VERSION ""

NS_ :

BS_:

BU_: Engine2 Aftertreatment_1_GasOutlet BrakesSystemController Transmission1 Engine1

BO_ 2364473170 AC_At1Out: 8 Aftertreatment_1_GasOutlet
 SG_ ArbitraryAddressCapable : 63|1@1+ (1,0) [0|1] "" Vector__XXX
 SG_ IndustryGroup M : 60|3@1+ (1,0) [0|7] "" Vector__XXX
 SG_ VehicleSystemInstance : 56|4@1+ (1,0) [0|15] "" Vector__XXX
 SG_ Function : 40|8@1+ (1,0) [0|255] "" Vector__XXX
 SG_ FunctionInstance : 35|5@1+ (1,0) [0|31] "" Vector__XXX
 SG_ ECUInstance : 32|3@1+ (1,0) [0|7] "" Vector__XXX
 SG_ ManufacturerCode : 21|11@1+ (1,0) [0|2047] "" Vector__XXX
 SG_ IdentityNumber : 0|21@1+ (1,0) [0|2097152] "" Vector__XXX
 SG_ VehicleSystem m0 : 49|7@1+ (1,0) [0|127] "" Vector__XXX
 SG_ VehicleSystem5 m5 : 49|7@1+ (1,0) [0|127] "" Vector__XXX
 SG_ VehicleSystem4 m4 : 49|7@1+ (1,0) [0|127] "" Vector__XXX
 SG_ VehicleSystem3 m3 : 49|7@1+ (1,0) [0|127] "" Vector__XXX
 SG_ VehicleSystem2 m2 : 49|7@1+ (1,0) [0|127] "" Vector__XXX
 SG_ VehicleSystem1 m1 : 49|7@1+ (1,0) [0|127] "" Vector__XXX

BO_ 2364473169 AC_At1In: 8 Vector__XXX
 SG_ ArbitraryAddressCapable : 63|1@1+ (1,0) [0|1] "" Vector__XXX
 SG_ IndustryGroup M : 60|3@1+ (1,0) [0|7] "" Vector__XXX
 SG_ VehicleSystemInstance : 56|4@1+ (1,0) [0|15] "" Vector__XXX
 SG_ Function : 40|8@1+ (1,0) [0|255] "" Vector__XXX
 SG_ FunctionInstance : 35|5@1+ (1,0) [0|31] "" Vector__XXX
 SG_ ECUInstance : 32|3@1+ (1,0) [0|7] "" Vector__XXX
 SG_ ManufacturerCode : 21|11@1+ (1,0) [0|2047] "" Vector__XXX
 SG_ IdentityNumber : 0|21@1+ (1,0) [0|2097152] "" Vector__XXX
 SG_ VehicleSystem m0 : 49|7@1+ (1,0) [0|127] "" Vector__XXX
 SG_ VehicleSystem5 m5 : 49|7@1+ (1,0) [0|127] "" Vector__XXX
 SG_ VehicleSystem4 m4 : 49|7@1+ (1,0) [0|127] "" Vector__XXX
 SG_ VehicleSystem3 m3 : 49|7@1+ (1,0) [0|127] "" Vector__XXX
 SG_ VehicleSystem2 m2 : 49|7@1+ (1,0) [0|127] "" Vector__XXX
 SG_ VehicleSystem1 m1 : 49|7@1+ (1,0) [0|127] "" Vector__XXX

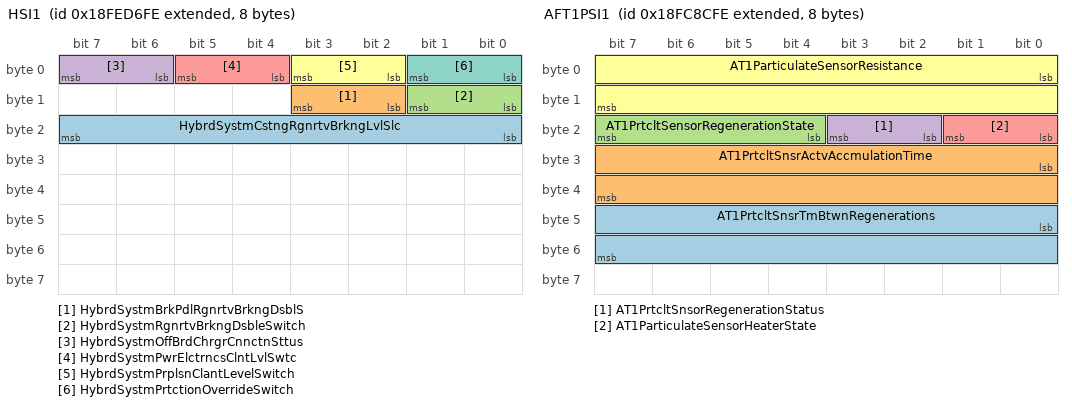
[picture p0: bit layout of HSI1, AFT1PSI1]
BO_ 2566838014 HSI1: 8 Vector__XXX
 SG_ HybrdSystmCstngRgnrtvBrkngLvlSlc : 16|8@1+ (0.4,0) [0|100] "%" Vector__XXX
 SG_ HybrdSystmBrkPdlRgnrtvBrkngDsblS : 10|2@1+ (1,0) [0|3] "" Vector__XXX
 SG_ HybrdSystmRgnrtvBrkngDsbleSwitch : 8|2@1+ (1,0) [0|3] "" Vector__XXX
 SG_ HybrdSystmOffBrdChrgrCnnctnSttus : 6|2@1+ (1,0) [0|3] "" Vector__XXX
 SG_ HybrdSystmPwrElctrncsClntLvlSwtc : 4|2@1+ (1,0) [0|3] "" Vector__XXX
 SG_ HybrdSystmPrplsnClantLevelSwitch : 2|2@1+ (1,0) [0|3] "" Vector__XXX
 SG_ HybrdSystmPrtctionOverrideSwitch : 0|2@1+ (1,0) [0|3] "" Vector__XXX

BO_ 2566761726 EFI: 8 Vector__XXX
 SG_ EngIdleFuelFlowRateThreshold : 8|32@1+ (0.001,0) [0|4211081.215] "L/h" Vector__XXX
 SG_ NmbrOfFlCnsmptnMntrngTransducers : 0|8@1+ (1,0) [0|250] "" Vector__XXX

BO_ 2566756350 LFI3: 8 Vector__XXX
 SG_ EngFuelReturnTemp : 8|8@1+ (1,-40) [-40|210] "°C" Vector__XXX
 SG_ EngFuelSupplyTemp : 0|8@1+ (1,-40) [-40|210] "°C" Vector__XXX

BO_ 2566756094 LFI2: 8 Vector__XXX
 SG_ EngFuelReturnFlowRate : 32|32@1+ (0.001,0) [0|4211081.215] "L/h" Vector__XXX
 SG_ EngFuelSupplyFlowRate : 0|32@1+ (0.001,0) [0|4211081.215] "L/h" Vector__XXX

BO_ 2566687998 AFT1PSI1: 8 Vector__XXX
 SG_ AT1PrtcltSnsrTmBtwnRegenerations : 40|16@1+ (6,0) [0|385530] "s" Vector__XXX
 SG_ AT1PrtcltSnsrActvAccmulationTime : 24|16@1+ (6,0) [0|385530] "s" Vector__XXX
 SG_ AT1PrtcltSensorRegenerationState : 20|4@1+ (1,0) [0|15] "" Vector__XXX
 SG_ AT1PrtcltSnsorRegenerationStatus : 18|2@1+ (1,0) [0|3] "" Vector__XXX
 SG_ AT1ParticulateSensorHeaterState : 16|2@1+ (1,0) [0|3] "" Vector__XXX
 SG_ AT1ParticulateSensorResistance : 0|16@1+ (1,0) [0|62500] "kohm" Vector__XXX

BO_ 2566687742 AFT1PSI2: 8 Vector__XXX
 SG_ AT1PrtclteSensorHeaterResistance : 40|16@1+ (0.1,0) [0|6425.5] "ohm" Vector__XXX
 SG_ AT1PrticulateSensorMaxResistance : 32|16@1+ (250,0) [0|62500] "kohm" Vector__XXX
 SG_ AT1ParticulateSensorTemp : 16|16@1+ (0.03125,-273) [-273|1734.96875] "°C" Vector__XXX
 SG_ AT1PrtcltSnsrRgnrtionFailedCount : 8|8@1+ (1,0) [0|250] "" Vector__XXX
 SG_ AT1ParticulateSensorPowerSupply : 4|2@1+ (1,0) [0|3] "" Vector__XXX
 SG_ AT1PrtclateSensorDetectionStatus : 0|4@1+ (1,0) [0|15] "" Vector__XXX

BO_ 2365348350 ELS: 8 Vector__XXX
 SG_ EngLoadShareStatus : 2|4@1+ (1,0) [0|15] "" Vector__XXX
 SG_ EngUnloadStatus : 0|2@1+ (1,0) [0|3] "" Vector__XXX

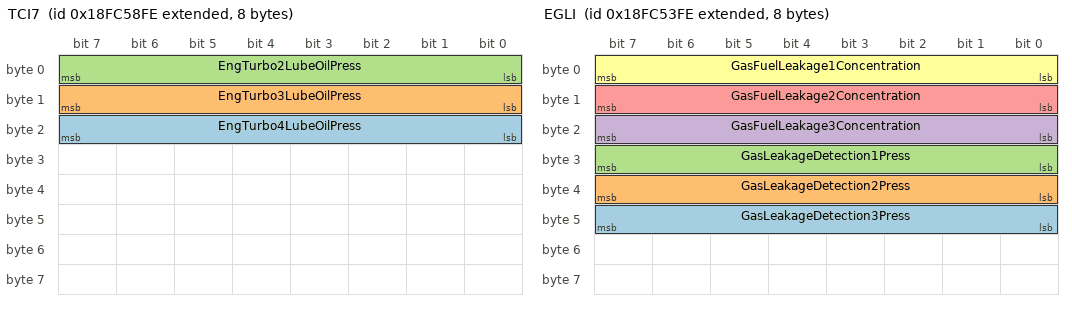
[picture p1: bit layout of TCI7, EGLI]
BO_ 2566674686 TCI7: 8 Vector__XXX
 SG_ EngTurbo4LubeOilPress : 16|8@1+ (4,0) [0|1000] "kPa" Vector__XXX
 SG_ EngTurbo3LubeOilPress : 8|8@1+ (4,0) [0|1000] "kPa" Vector__XXX
 SG_ EngTurbo2LubeOilPress : 0|8@1+ (4,0) [0|1000] "kPa" Vector__XXX

BO_ 2566674430 SCROII1: 8 Vector__XXX
 SG_ DslExhstFldQalityMalfunctionTime : 32|32@1+ (1,0) [0|4211081215] "s" Vector__XXX
 SG_ DieselExhaustFluidTank1EmptyTime : 0|32@1+ (1,0) [0|4211081215] "s" Vector__XXX

BO_ 2566674174 SCROII2: 8 Vector__XXX
 SG_ SCROperatorInducementTotalTime : 32|32@1+ (1,0) [0|4211081215] "s" Vector__XXX
 SG_ ATSCRMalfunctionTime : 0|32@1+ (1,0) [0|4211081215] "s" Vector__XXX

BO_ 2566673406 EGLI: 8 Vector__XXX
 SG_ GasLeakageDetection3Press : 40|8@1+ (4,0) [0|100] "kPa" Vector__XXX
 SG_ GasLeakageDetection2Press : 32|8@1+ (4,0) [0|100] "kPa" Vector__XXX
 SG_ GasLeakageDetection1Press : 24|8@1+ (4,0) [0|100] "kPa" Vector__XXX
 SG_ GasFuelLeakage3Concentration : 16|8@1+ (0.5,0) [0|100] "%" Vector__XXX
 SG_ GasFuelLeakage2Concentration : 8|8@1+ (0.5,0) [0|100] "%" Vector__XXX
 SG_ GasFuelLeakage1Concentration : 0|8@1+ (0.5,0) [0|100] "%" Vector__XXX

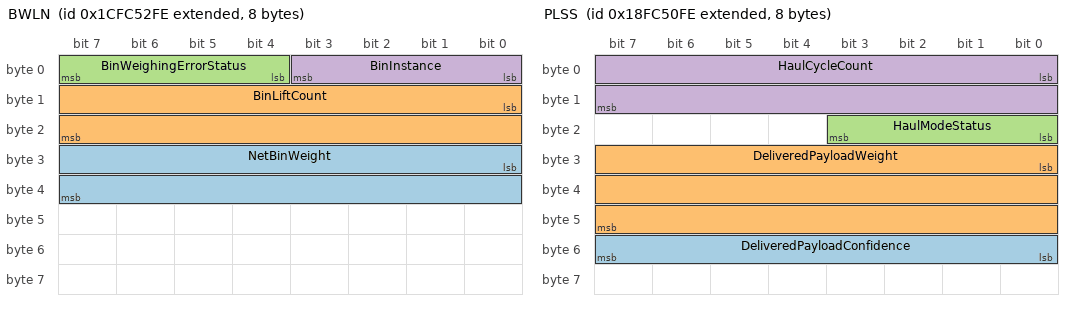
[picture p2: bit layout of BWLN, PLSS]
BO_ 2633782014 BWLN: 8 Vector__XXX
 SG_ NetBinWeight : 24|16@1+ (2,0) [0|128510] "kg" Vector__XXX
 SG_ BinLiftCount : 8|16@1+ (1,0) [0|64255] "" Vector__XXX
 SG_ BinWeighingErrorStatus : 4|4@1+ (1,0) [0|15] "" Vector__XXX
 SG_ BinInstance : 0|4@1+ (1,0) [0|15] "" Vector__XXX

BO_ 2365346302 ASC7: 8 Vector__XXX
 SG_ LiftAxle2Status : 3|3@1+ (1,0) [0|7] "" Vector__XXX
 SG_ LiftAxle1Status : 0|3@1+ (1,0) [0|7] "" Vector__XXX

BO_ 2566672638 PLSS: 8 Vector__XXX
 SG_ DeliveredPayloadConfidence : 48|8@1+ (0.5,0) [0|100] "%" Vector__XXX
 SG_ DeliveredPayloadWeight : 24|24@1+ (2,0) [0|32899070] "kg" Vector__XXX
 SG_ HaulModeStatus : 16|4@1+ (1,0) [0|15] "" Vector__XXX
 SG_ HaulCycleCount : 0|16@1+ (1,0) [0|64255] "" Vector__XXX

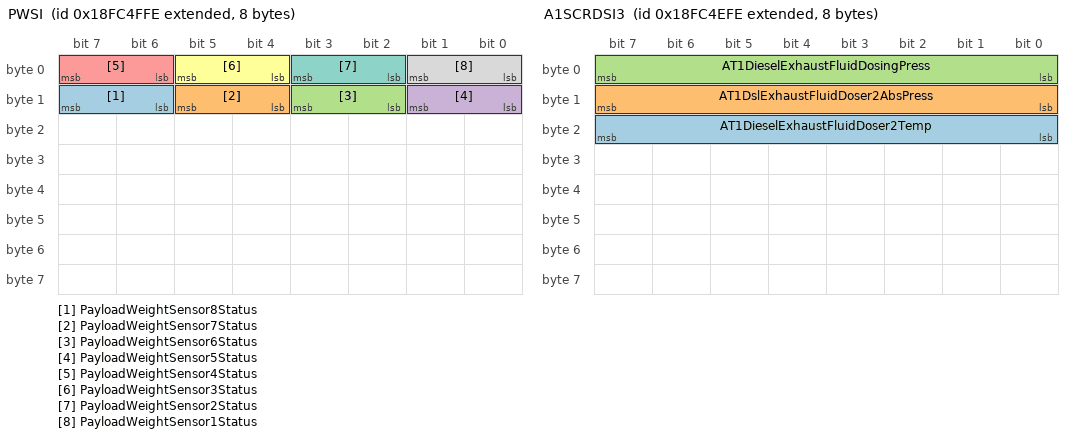
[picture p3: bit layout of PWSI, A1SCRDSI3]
BO_ 2566672382 PWSI: 8 Vector__XXX
 SG_ PayloadWeightSensor8Status : 14|2@1+ (1,0) [0|3] "" Vector__XXX
 SG_ PayloadWeightSensor7Status : 12|2@1+ (1,0) [0|3] "" Vector__XXX
 SG_ PayloadWeightSensor6Status : 10|2@1+ (1,0) [0|3] "" Vector__XXX
 SG_ PayloadWeightSensor5Status : 8|2@1+ (1,0) [0|3] "" Vector__XXX
 SG_ PayloadWeightSensor4Status : 6|2@1+ (1,0) [0|3] "" Vector__XXX
 SG_ PayloadWeightSensor3Status : 4|2@1+ (1,0) [0|3] "" Vector__XXX
 SG_ PayloadWeightSensor2Status : 2|2@1+ (1,0) [0|3] "" Vector__XXX
 SG_ PayloadWeightSensor1Status : 0|2@1+ (1,0) [0|3] "" Vector__XXX

BO_ 2566672126 A1SCRDSI3: 8 Vector__XXX
 SG_ AT1DieselExhaustFluidDoser2Temp : 16|8@1+ (1,-40) [-40|210] "°C" Vector__XXX
 SG_ AT1DslExhaustFluidDoser2AbsPress : 8|8@1+ (8,0) [0|2000] "kPa" Vector__XXX
 SG_ AT1DieselExhaustFluidDosingPress : 0|8@1+ (4,0) [0|1000] "kPa" Vector__XXX

BO_ 2566671870 A2SCRDSI3: 8 Vector__XXX
 SG_ AT2DieselExhaustFluidDosingPress : 0|8@1+ (4,0) [0|1000] "kPa" Vector__XXX

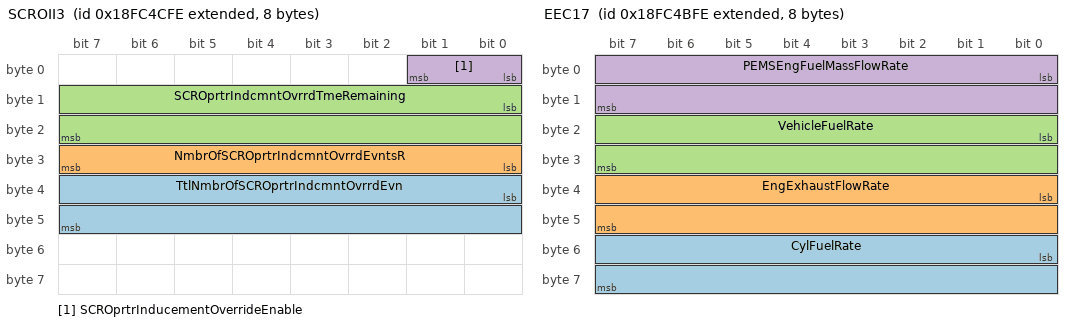
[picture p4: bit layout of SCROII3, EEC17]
BO_ 2566671614 SCROII3: 8 Vector__XXX
 SG_ TtlNmbrOfSCROprtrIndcmntOvrrdEvn : 32|16@1+ (1,0) [0|64255] "" Vector__XXX
 SG_ NmbrOfSCROprtrIndcmntOvrrdEvntsR : 24|8@1+ (1,0) [0|250] "" Vector__XXX
 SG_ SCROprtrIndcmntOvrrdTmeRemaining : 8|16@1+ (1,0) [0|64255] "s" Vector__XXX
 SG_ SCROprtrInducementOverrideEnable : 0|2@1+ (1,0) [0|3] "" Vector__XXX

BO_ 2566671358 EEC17: 8 Vector__XXX
 SG_ CylFuelRate : 48|16@1+ (0.03125,0) [0|2007.96875] "mg/stroke" Vector__XXX
 SG_ EngExhaustFlowRate : 32|16@1+ (0.2,0) [0|12851] "kg/h" Vector__XXX
 SG_ VehicleFuelRate : 16|16@1+ (0.02,0) [0|1285.1] "g/s" Vector__XXX
 SG_ PEMSEngFuelMassFlowRate : 0|16@1+ (0.02,0) [0|1285.1] "g/s" Vector__XXX

BO_ 2566671102 SCRSC: 8 Vector__XXX
 SG_ SCRSystemCleaningForcedStatus : 53|3@1+ (1,0) [0|7] "" Vector__XXX
 SG_ SCRSystmClnngAtmtcIntationConfig : 48|2@1+ (1,0) [0|3] "" Vector__XXX
 SG_ SCRSystmClnngInhbtdDTVhclSpdBlwA : 46|2@1+ (1,0) [0|3] "" Vector__XXX
 SG_ SCRSystmClnngInhbtdDTEngNtWrmdUp : 44|2@1+ (1,0) [0|3] "" Vector__XXX
 SG_ SCRSystmClnngInhbtdDTPrmnntSystm : 42|2@1+ (1,0) [0|3] "" Vector__XXX
 SG_ SCRSystmClnngInhbtdDTTmprrySystm : 40|2@1+ (1,0) [0|3] "" Vector__XXX
 SG_ SCRSystmClnngInhbtdDTSystmTmeout : 38|2@1+ (1,0) [0|3] "" Vector__XXX
 SG_ SCRSystmClnngInhbtdDTSystmFltAct : 36|2@1+ (1,0) [0|3] "" Vector__XXX
 SG_ SCRSystmClnngInhbtdDTLwExhstTemp : 34|2@1+ (1,0) [0|3] "" Vector__XXX
 SG_ SCRSystmClnngInhbtdDTPrkngBrkNtS : 32|2@1+ (1,0) [0|3] "" Vector__XXX
 SG_ SCRSystmClnngInhbtdDTVhclSpdAbvA : 30|2@1+ (1,0) [0|3] "" Vector__XXX
 SG_ SCRSystmClnngInhbtdDTOtOfNeutral : 28|2@1+ (1,0) [0|3] "" Vector__XXX
 SG_ SCRSystmClnngInhbtdDTAcclPdlOffI : 26|2@1+ (1,0) [0|3] "" Vector__XXX
 SG_ SCRSystmClnngInhbtdDeToPTOActive : 24|2@1+ (1,0) [0|3] "" Vector__XXX
 SG_ SCRSystmClnngInhbtdDTSrvcBrkActv : 22|2@1+ (1,0) [0|3] "" Vector__XXX
 SG_ SCRSystmClnngInhbtdDTCltchDsnggd : 20|2@1+ (1,0) [0|3] "" Vector__XXX
 SG_ SCRSystmClnngInhbtdDTInhbtSwitch : 18|2@1+ (1,0) [0|3] "" Vector__XXX
 SG_ SCRSystemCleaningInhibitedStatus : 16|2@1+ (1,0) [0|3] "" Vector__XXX
 SG_ SCRSystemCleaningStatus : 10|2@1+ (1,0) [0|3] "" Vector__XXX
 SG_ SCRSystemCleaningLampCmd : 0|3@1+ (1,0) [0|7] "" Vector__XXX

BO_ 2566670846 AT1HI2: 8 Vector__XXX
 SG_ AT1SCRSystmAvrgDstncBtwnSystmCln : 160|32@1+ (0.125,0) [0|526385151.875] "km" Vector__XXX
 SG_ AT1SCRSystmAvrgTmBtwnSystmClnngE : 128|32@1+ (1,0) [0|4211081215] "s" Vector__XXX
 SG_ AT1SCRSystmTtlNmbrOfSystmClnngMn : 96|32@1+ (1,0) [0|4211081215] "" Vector__XXX
 SG_ AT1SCRSystmTtlNmbrOfSystmClnngIn : 64|32@1+ (1,0) [0|4211081215] "" Vector__XXX
 SG_ AT1SCRSystmTtlNmbrOfSystmClnngEv : 32|32@1+ (1,0) [0|4211081215] "" Vector__XXX
 SG_ AT1SCRSystemTotalCleaningTime : 0|32@1+ (1,0) [0|4211081215] "s" Vector__XXX

BO_ 2566670590 AT2HI2: 8 Vector__XXX
 SG_ AT2SCRSystmAvrgDstncBtwnSystmCln : 160|32@1+ (0.125,0) [0|526385151.875] "km" Vector__XXX
 SG_ AT2SCRSystmAvrgTmBtwnSystmClnngE : 128|32@1+ (1,0) [0|4211081215] "s" Vector__XXX
 SG_ AT2SCRSystmTtlNmbrOfSystmClnngMn : 96|32@1+ (1,0) [0|4211081215] "" Vector__XXX
 SG_ AT2SCRSystmTtlNmbrOfSystmClnngIn : 64|32@1+ (1,0) [0|4211081215] "" Vector__XXX
 SG_ AT2SCRSystmTtlNmbrOfSystmClnngEv : 32|32@1+ (1,0) [0|4211081215] "" Vector__XXX
 SG_ AT2SCRSystmTtlSystemCleaningTime : 0|32@1+ (1,0) [0|4211081215] "s" Vector__XXX

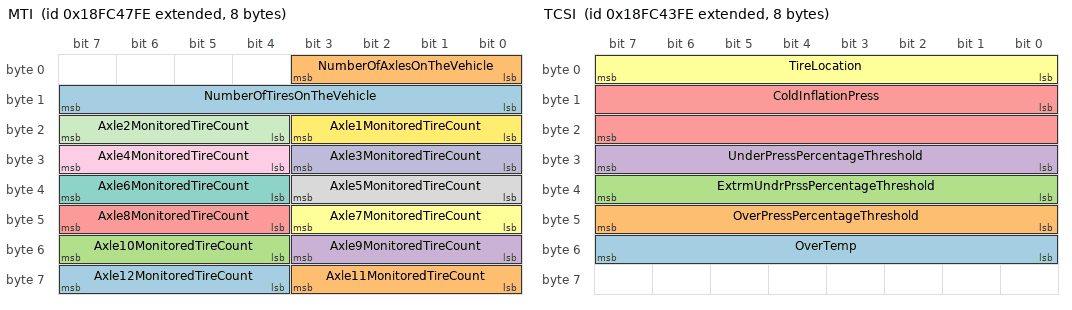
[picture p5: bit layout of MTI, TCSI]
BO_ 2566670334 MTI: 8 Vector__XXX
 SG_ Axle12MonitoredTireCount : 60|4@1+ (1,0) [0|13] "" Vector__XXX
 SG_ Axle11MonitoredTireCount : 56|4@1+ (1,0) [0|13] "" Vector__XXX
 SG_ Axle10MonitoredTireCount : 52|4@1+ (1,0) [0|13] "" Vector__XXX
 SG_ Axle9MonitoredTireCount : 48|4@1+ (1,0) [0|13] "" Vector__XXX
 SG_ Axle8MonitoredTireCount : 44|4@1+ (1,0) [0|13] "" Vector__XXX
 SG_ Axle7MonitoredTireCount : 40|4@1+ (1,0) [0|13] "" Vector__XXX
 SG_ Axle6MonitoredTireCount : 36|4@1+ (1,0) [0|13] "" Vector__XXX
 SG_ Axle5MonitoredTireCount : 32|4@1+ (1,0) [0|13] "" Vector__XXX
 SG_ Axle4MonitoredTireCount : 28|4@1+ (1,0) [0|13] "" Vector__XXX
 SG_ Axle3MonitoredTireCount : 24|4@1+ (1,0) [0|13] "" Vector__XXX
 SG_ Axle2MonitoredTireCount : 20|4@1+ (1,0) [0|13] "" Vector__XXX
 SG_ Axle1MonitoredTireCount : 16|4@1+ (1,0) [0|13] "" Vector__XXX
 SG_ NumberOfTiresOnTheVehicle : 8|8@1+ (1,0) [0|250] "" Vector__XXX
 SG_ NumberOfAxlesOnTheVehicle : 0|4@1+ (1,0) [0|13] "" Vector__XXX

BO_ 2566670078 TSId: 8 Vector__XXX
 SG_ TireSensorIdentificationNumber : 0|8@1+ (1,0) [0|255] "" Vector__XXX
 SG_ TireSensorLocation : 65528|8@1+ (1,0) [0|255] "" Vector__XXX
 SG_ TireSensorTireNumber : 65520|8@1+ (1,0) [0|250] "" Vector__XXX
 SG_ NumberOfTireSensors : 65512|8@1+ (1,0) [0|250] "" Vector__XXX

BO_ 2566669822 TWSSI: 8 Vector__XXX
 SG_ TrWrelessSignalStrengthIndicator : 0|8@1+ (0.5,-125) [-125|0] "dBm" Vector__XXX
 SG_ TireLocation : 0|8@1+ (1,0) [0|0] "" Vector__XXX
 SG_ TireSensorNumber : 0|8@1+ (1,0) [0|250] "" Vector__XXX
 SG_ TtalNumberOfTireSensorsMonitored : 0|8@1+ (1,0) [0|250] "" Vector__XXX
 SG_ AntennaNumber : 0|8@1+ (1,0) [0|250] "" Vector__XXX
 SG_ TotalNumberOfAntennasUsed : 0|8@1+ (1,0) [0|250] "" Vector__XXX

BO_ 2566669310 TCSI: 8 Vector__XXX
 SG_ OverTemp : 48|8@1+ (1,-40) [-40|210] "°C" Vector__XXX
 SG_ OverPressPercentageThreshold : 40|8@1+ (0.5,0) [0|125] "%" Vector__XXX
 SG_ ExtrmUndrPrssPercentageThreshold : 32|8@1+ (0.5,0) [0|125] "%" Vector__XXX
 SG_ UnderPressPercentageThreshold : 24|8@1+ (0.5,0) [0|125] "%" Vector__XXX
 SG_ ColdInflationPress : 8|16@1+ (1,0) [0|64255] "kPa" Vector__XXX
 SG_ TireLocation : 0|8@1+ (1,0) [0|0] "" Vector__XXX

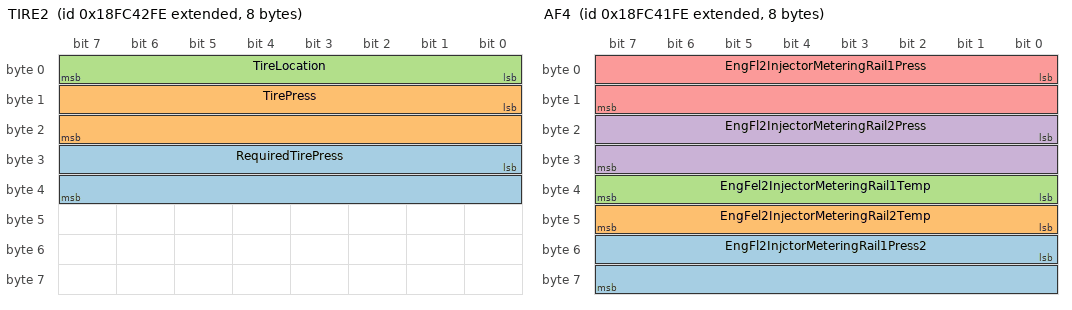
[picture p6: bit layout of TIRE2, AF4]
BO_ 2566669054 TIRE2: 8 Vector__XXX
 SG_ RequiredTirePress : 24|16@1+ (1,0) [0|64255] "kPa" Vector__XXX
 SG_ TirePress : 8|16@1+ (1,0) [0|64255] "kPa" Vector__XXX
 SG_ TireLocation : 0|8@1+ (1,0) [0|0] "" Vector__XXX

BO_ 2566668798 AF4: 8 Vector__XXX
 SG_ EngFl2InjctorMeteringRail1Press2 : 48|16@1+ (2,0) [0|128510] "kPa" Vector__XXX
 SG_ EngFel2InjectorMeteringRail2Temp : 40|8@1+ (1,-40) [-40|210] "°C" Vector__XXX
 SG_ EngFel2InjectorMeteringRail1Temp : 32|8@1+ (1,-40) [-40|210] "°C" Vector__XXX
 SG_ EngFl2InjectorMeteringRail2Press : 16|16@1+ (2,0) [0|128510] "kPa" Vector__XXX
 SG_ EngFl2InjectorMeteringRail1Press : 0|16@1+ (2,0) [0|128510] "kPa" Vector__XXX

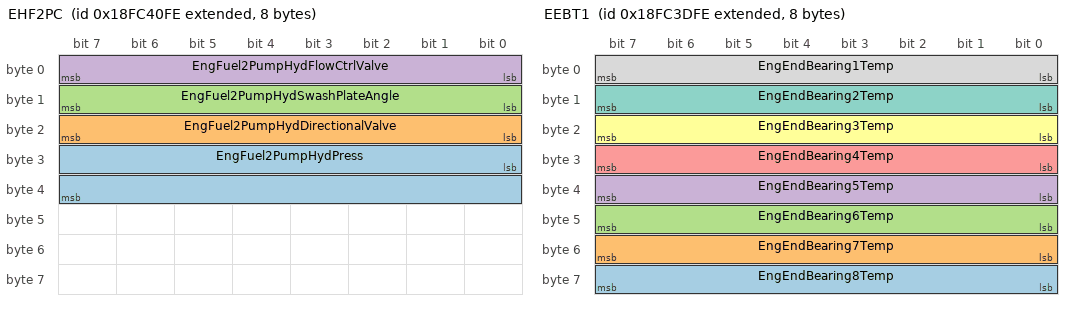
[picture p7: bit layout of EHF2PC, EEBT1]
BO_ 2566668542 EHF2PC: 8 Vector__XXX
 SG_ EngFuel2PumpHydPress : 24|16@1+ (2,0) [0|128510] "kPa" Vector__XXX
 SG_ EngFuel2PumpHydDirectionalValve : 16|8@1+ (0.4,0) [0|100] "%" Vector__XXX
 SG_ EngFuel2PumpHydSwashPlateAngle : 8|8@1+ (0.4,0) [0|100] "%" Vector__XXX
 SG_ EngFuel2PumpHydFlowCtrlValve : 0|8@1+ (0.4,0) [0|100] "%" Vector__XXX

BO_ 2566668286 ETCC2: 8 Vector__XXX
 SG_ EngStagedTurboSolenoidStatus : 0|8@1+ (0.4,0) [0|100] "%" Vector__XXX

BO_ 2566668030 HEDPI: 8 Vector__XXX
 SG_ HtExchngerDebrisPurgeApproaching : 2|2@1+ (1,0) [0|3] "" Vector__XXX
 SG_ HeatExchangerDebrisPurgeStatus : 0|2@1+ (1,0) [0|3] "" Vector__XXX

BO_ 2566667774 EEBT1: 8 Vector__XXX
 SG_ EngEndBearing8Temp : 56|8@1+ (1,-40) [-40|210] "°C" Vector__XXX
 SG_ EngEndBearing7Temp : 48|8@1+ (1,-40) [-40|210] "°C" Vector__XXX
 SG_ EngEndBearing6Temp : 40|8@1+ (1,-40) [-40|210] "°C" Vector__XXX
 SG_ EngEndBearing5Temp : 32|8@1+ (1,-40) [-40|210] "°C" Vector__XXX
 SG_ EngEndBearing4Temp : 24|8@1+ (1,-40) [-40|210] "°C" Vector__XXX
 SG_ EngEndBearing3Temp : 16|8@1+ (1,-40) [-40|210] "°C" Vector__XXX
 SG_ EngEndBearing2Temp : 8|8@1+ (1,-40) [-40|210] "°C" Vector__XXX
 SG_ EngEndBearing1Temp : 0|8@1+ (1,-40) [-40|210] "°C" Vector__XXX

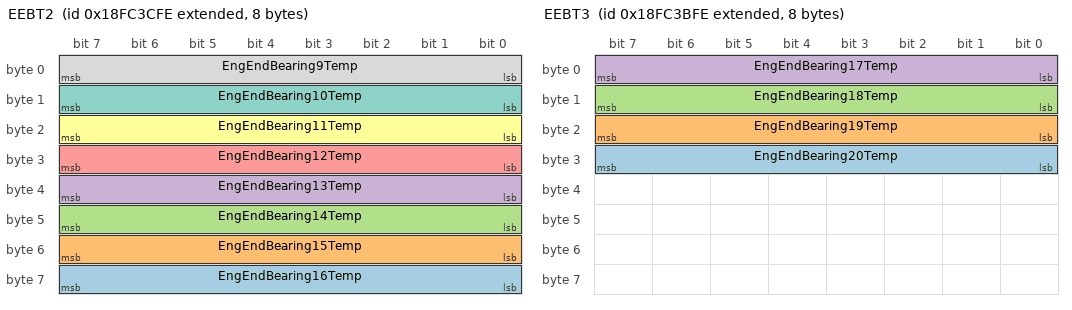
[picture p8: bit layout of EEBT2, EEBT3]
BO_ 2566667518 EEBT2: 8 Vector__XXX
 SG_ EngEndBearing16Temp : 56|8@1+ (1,-40) [-40|210] "°C" Vector__XXX
 SG_ EngEndBearing15Temp : 48|8@1+ (1,-40) [-40|210] "°C" Vector__XXX
 SG_ EngEndBearing14Temp : 40|8@1+ (1,-40) [-40|210] "°C" Vector__XXX
 SG_ EngEndBearing13Temp : 32|8@1+ (1,-40) [-40|210] "°C" Vector__XXX
 SG_ EngEndBearing12Temp : 24|8@1+ (1,-40) [-40|210] "°C" Vector__XXX
 SG_ EngEndBearing11Temp : 16|8@1+ (1,-40) [-40|210] "°C" Vector__XXX
 SG_ EngEndBearing10Temp : 8|8@1+ (1,-40) [-40|210] "°C" Vector__XXX
 SG_ EngEndBearing9Temp : 0|8@1+ (1,-40) [-40|210] "°C" Vector__XXX

BO_ 2566667262 EEBT3: 8 Vector__XXX
 SG_ EngEndBearing20Temp : 24|8@1+ (1,-40) [-40|210] "°C" Vector__XXX
 SG_ EngEndBearing19Temp : 16|8@1+ (1,-40) [-40|210] "°C" Vector__XXX
 SG_ EngEndBearing18Temp : 8|8@1+ (1,-40) [-40|210] "°C" Vector__XXX
 SG_ EngEndBearing17Temp : 0|8@1+ (1,-40) [-40|210] "°C" Vector__XXX

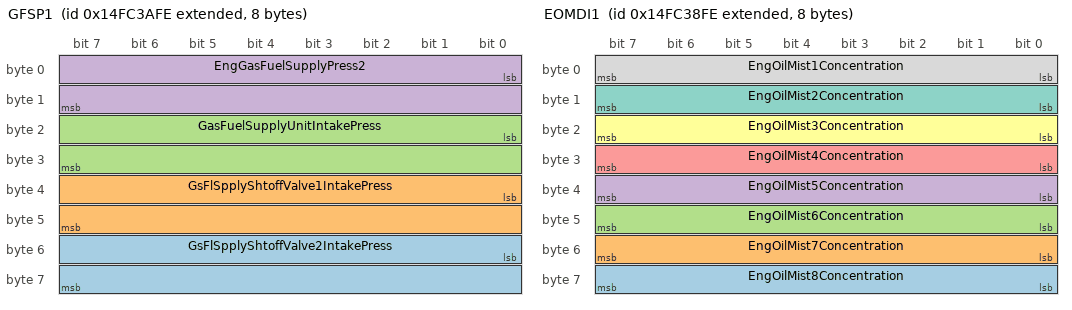
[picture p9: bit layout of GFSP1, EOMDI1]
BO_ 2499558142 GFSP1: 8 Vector__XXX
 SG_ GsFlSpplyShtoffValve2IntakePress : 48|16@1+ (0.5,0) [0|32127.5] "kPa" Vector__XXX
 SG_ GsFlSpplyShtoffValve1IntakePress : 32|16@1+ (0.5,0) [0|32127.5] "kPa" Vector__XXX
 SG_ GasFuelSupplyUnitIntakePress : 16|16@1+ (0.5,0) [0|32127.5] "kPa" Vector__XXX
 SG_ EngGasFuelSupplyPress2 : 0|16@1+ (0.5,0) [0|32127.5] "kPa" Vector__XXX

BO_ 2499557886 GFSP2: 8 Vector__XXX
 SG_ PlantInertGasSupplyOutletPress : 16|16@1+ (0.5,0) [0|32127.5] "kPa" Vector__XXX
 SG_ PlantGasFuelSupplyOutletPress : 0|16@1+ (0.5,0) [0|32127.5] "kPa" Vector__XXX

BO_ 2499557630 EOMDI1: 8 Vector__XXX
 SG_ EngOilMist8Concentration : 56|8@1+ (1,0) [0|250] "%" Vector__XXX
 SG_ EngOilMist7Concentration : 48|8@1+ (1,0) [0|250] "%" Vector__XXX
 SG_ EngOilMist6Concentration : 40|8@1+ (1,0) [0|250] "%" Vector__XXX
 SG_ EngOilMist5Concentration : 32|8@1+ (1,0) [0|250] "%" Vector__XXX
 SG_ EngOilMist4Concentration : 24|8@1+ (1,0) [0|250] "%" Vector__XXX
 SG_ EngOilMist3Concentration : 16|8@1+ (1,0) [0|250] "%" Vector__XXX
 SG_ EngOilMist2Concentration : 8|8@1+ (1,0) [0|250] "%" Vector__XXX
 SG_ EngOilMist1Concentration : 0|8@1+ (1,0) [0|250] "%" Vector__XXX

BO_ 2499557374 EOMDI2: 8 Vector__XXX
 SG_ EngOilMist10Concentration : 8|8@1+ (1,0) [0|250] "%" Vector__XXX
 SG_ EngOilMist9Concentration : 0|8@1+ (1,0) [0|250] "%" Vector__XXX

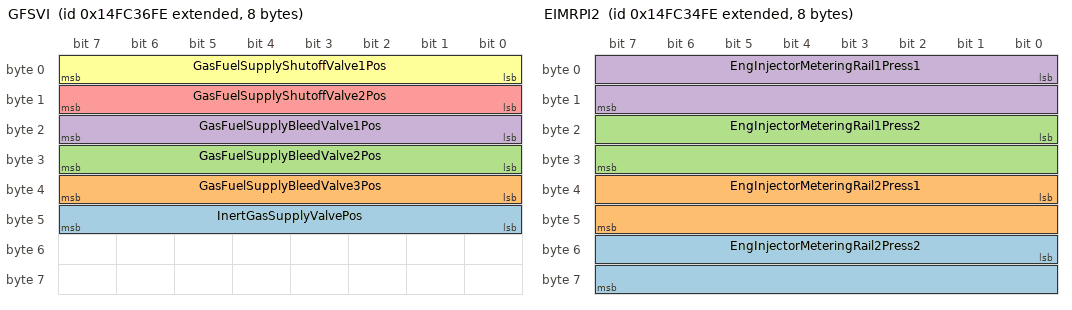
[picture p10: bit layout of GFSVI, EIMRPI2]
BO_ 2499557118 GFSVI: 8 Vector__XXX
 SG_ InertGasSupplyValvePos : 40|8@1+ (0.4,0) [0|100] "%" Vector__XXX
 SG_ GasFuelSupplyBleedValve3Pos : 32|8@1+ (0.4,0) [0|100] "%" Vector__XXX
 SG_ GasFuelSupplyBleedValve2Pos : 24|8@1+ (0.4,0) [0|100] "%" Vector__XXX
 SG_ GasFuelSupplyBleedValve1Pos : 16|8@1+ (0.4,0) [0|100] "%" Vector__XXX
 SG_ GasFuelSupplyShutoffValve2Pos : 8|8@1+ (0.4,0) [0|100] "%" Vector__XXX
 SG_ GasFuelSupplyShutoffValve1Pos : 0|8@1+ (0.4,0) [0|100] "%" Vector__XXX

BO_ 2566665726 AT2P1I: 8 Vector__XXX
 SG_ AT2DslExhustFluidPump2MotorSpeed : 8|16@1+ (0.5,0) [0|32127.5] "rpm" Vector__XXX
 SG_ AT2DieselExhaustFluidPumpHeater : 0|8@1+ (0.4,0) [0|100] "%" Vector__XXX

BO_ 2499556606 EIMRPI2: 8 Vector__XXX
 SG_ EngInjectorMeteringRail2Press2 : 48|16@1+ (5,0) [0|321275] "kPa" Vector__XXX
 SG_ EngInjectorMeteringRail2Press1 : 32|16@1+ (5,0) [0|321275] "kPa" Vector__XXX
 SG_ EngInjectorMeteringRail1Press2 : 16|16@1+ (5,0) [0|321275] "kPa" Vector__XXX
 SG_ EngInjectorMeteringRail1Press1 : 0|16@1+ (5,0) [0|321275] "kPa" Vector__XXX

BO_ 2499556350 EIMRPI3: 8 Vector__XXX
 SG_ EngInjctrMtringRail2DesiredPress : 16|16@1+ (5,0) [0|321275] "kPa" Vector__XXX
 SG_ EngInjctrMtringRail1DesiredPress : 0|16@1+ (5,0) [0|321275] "kPa" Vector__XXX

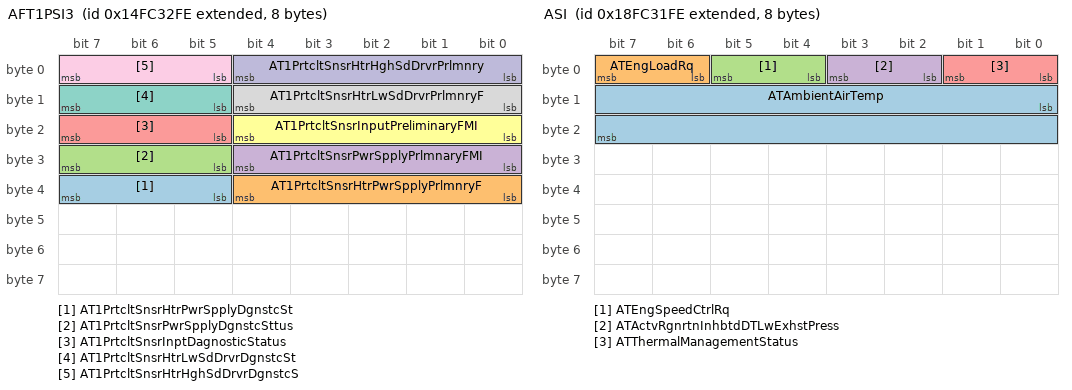
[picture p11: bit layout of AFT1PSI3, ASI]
BO_ 2499556094 AFT1PSI3: 8 Vector__XXX
 SG_ AT1PrtcltSnsrHtrPwrSpplyDgnstcSt : 37|3@1+ (1,0) [0|7] "" Vector__XXX
 SG_ AT1PrtcltSnsrHtrPwrSpplyPrlmnryF : 32|5@1+ (1,0) [0|31] "" Vector__XXX
 SG_ AT1PrtcltSnsrPwrSpplyDgnstcSttus : 29|3@1+ (1,0) [0|7] "" Vector__XXX
 SG_ AT1PrtcltSnsrPwrSpplyPrlmnaryFMI : 24|5@1+ (1,0) [0|31] "" Vector__XXX
 SG_ AT1PrtcltSnsrInptDagnosticStatus : 21|3@1+ (1,0) [0|7] "" Vector__XXX
 SG_ AT1PrtcltSnsrInputPreliminaryFMI : 16|5@1+ (1,0) [0|31] "" Vector__XXX
 SG_ AT1PrtcltSnsrHtrLwSdDrvrDgnstcSt : 13|3@1+ (1,0) [0|7] "" Vector__XXX
 SG_ AT1PrtcltSnsrHtrLwSdDrvrPrlmnryF : 8|5@1+ (1,0) [0|31] "" Vector__XXX
 SG_ AT1PrtcltSnsrHtrHghSdDrvrDgnstcS : 5|3@1+ (1,0) [0|7] "" Vector__XXX
 SG_ AT1PrtcltSnsrHtrHghSdDrvrPrlmnry : 0|5@1+ (1,0) [0|31] "" Vector__XXX

BO_ 2566664702 ASI: 8 Vector__XXX
 SG_ ATAmbientAirTemp : 8|16@1+ (0.03125,-273) [-273|1734.96875] "°C" Vector__XXX
 SG_ ATEngLoadRq : 6|2@1+ (1,0) [0|3] "" Vector__XXX
 SG_ ATEngSpeedCtrlRq : 4|2@1+ (1,0) [0|3] "" Vector__XXX
 SG_ ATActvRgnrtnInhbtdDTLwExhstPress : 2|2@1+ (1,0) [0|3] "" Vector__XXX
 SG_ ATThermalManagementStatus : 0|2@1+ (1,0) [0|3] "" Vector__XXX

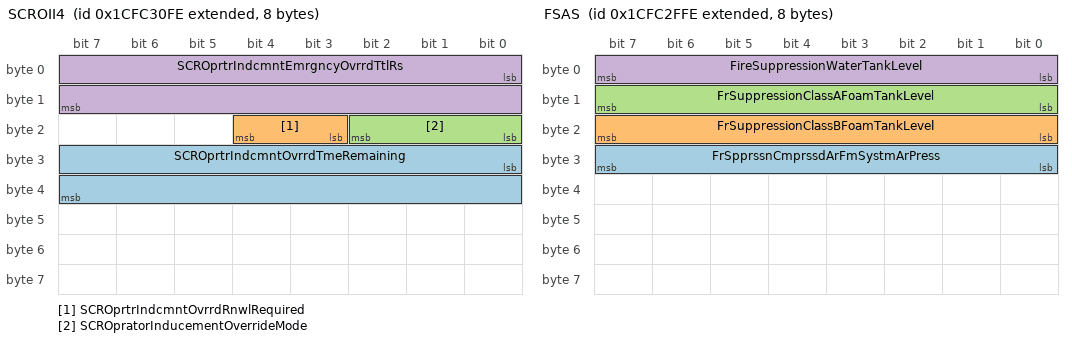
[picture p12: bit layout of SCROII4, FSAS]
BO_ 2633773310 SCROII4: 8 Vector__XXX
 SG_ SCROprtrIndcmntOvrrdTmeRemaining : 24|16@1+ (1,0) [0|64255] "min" Vector__XXX
 SG_ SCROprtrIndcmntOvrrdRnwlRequired : 19|2@1+ (1,0) [0|3] "" Vector__XXX
 SG_ SCROpratorInducementOverrideMode : 16|3@1+ (1,0) [0|7] "" Vector__XXX
 SG_ SCROprtrIndcmntEmrgncyOvrrdTtlRs : 0|16@1+ (1,0) [0|64255] "" Vector__XXX

BO_ 2633773054 FSAS: 8 Vector__XXX
 SG_ FrSpprssnCmprssdArFmSystmArPress : 24|8@1+ (8,0) [0|2000] "kPa" Vector__XXX
 SG_ FrSuppressionClassBFoamTankLevel : 16|8@1+ (0.4,0) [0|100] "%" Vector__XXX
 SG_ FrSuppressionClassAFoamTankLevel : 8|8@1+ (0.4,0) [0|100] "%" Vector__XXX
 SG_ FireSuppressionWaterTankLevel : 0|8@1+ (0.4,0) [0|100] "%" Vector__XXX

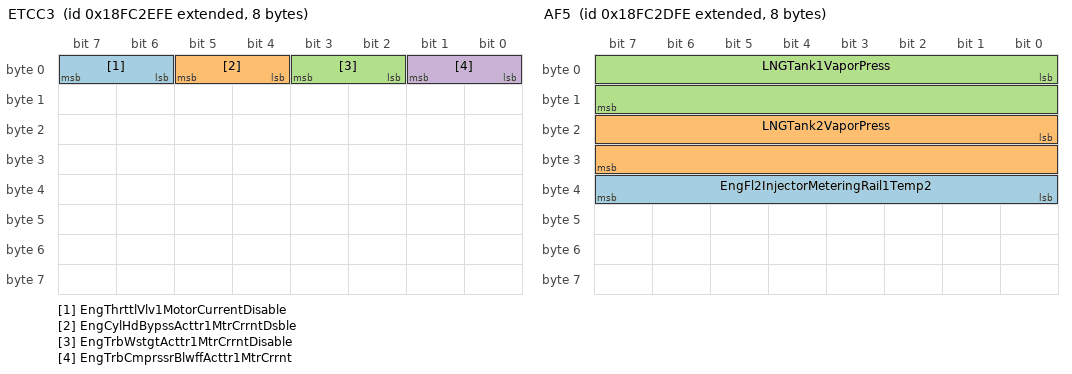
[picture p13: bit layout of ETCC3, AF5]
BO_ 2566663934 ETCC3: 8 Vector__XXX
 SG_ EngThrttlVlv1MotorCurrentDisable : 6|2@1+ (1,0) [0|3] "" Vector__XXX
 SG_ EngCylHdBypssActtr1MtrCrrntDsble : 4|2@1+ (1,0) [0|3] "" Vector__XXX
 SG_ EngTrbWstgtActtr1MtrCrrntDisable : 2|2@1+ (1,0) [0|3] "" Vector__XXX
 SG_ EngTrbCmprssrBlwffActtr1MtrCrrnt : 0|2@1+ (1,0) [0|3] "" Vector__XXX

BO_ 2566663678 AF5: 8 Vector__XXX
 SG_ EngFl2InjectorMeteringRail1Temp2 : 32|8@1+ (1,-40) [-40|210] "°C" Vector__XXX
 SG_ LNGTank2VaporPress : 16|16@1+ (0.1,0) [0|6425.5] "kPa" Vector__XXX
 SG_ LNGTank1VaporPress : 0|16@1+ (0.1,0) [0|6425.5] "kPa" Vector__XXX

BO_ 2566663422 BCLC: 8 Vector__XXX
 SG_ TrlrBrkClprLnngClranceAxle5Right : 38|2@1+ (1,0) [0|3] "" Vector__XXX
 SG_ TrlrBrkClprLnngClaranceAxle5Left : 36|2@1+ (1,0) [0|3] "" Vector__XXX
 SG_ TrlrBrkClprLnngClranceAxle4Right : 34|2@1+ (1,0) [0|3] "" Vector__XXX
 SG_ TrlrBrkClprLnngClaranceAxle4Left : 32|2@1+ (1,0) [0|3] "" Vector__XXX
 SG_ TrlrBrkClprLnngClranceAxle3Right : 30|2@1+ (1,0) [0|3] "" Vector__XXX
 SG_ TrlrBrkClprLnngClaranceAxle3Left : 28|2@1+ (1,0) [0|3] "" Vector__XXX
 SG_ TrlrBrkClprLnngClranceAxle2Right : 26|2@1+ (1,0) [0|3] "" Vector__XXX
 SG_ TrlrBrkClprLnngClaranceAxle2Left : 24|2@1+ (1,0) [0|3] "" Vector__XXX
 SG_ TrlrBrkClprLnngClranceAxle1Right : 22|2@1+ (1,0) [0|3] "" Vector__XXX
 SG_ TrlrBrkClprLnngClaranceAxle1Left : 20|2@1+ (1,0) [0|3] "" Vector__XXX
 SG_ TrctrBrkClprLnngClrnceAxle5Right : 18|2@1+ (1,0) [0|3] "" Vector__XXX
 SG_ TrctrBrkClprLnngClranceAxle5Left : 16|2@1+ (1,0) [0|3] "" Vector__XXX
 SG_ TrctrBrkClprLnngClrnceAxle4Right : 14|2@1+ (1,0) [0|3] "" Vector__XXX
 SG_ TrctrBrkClprLnngClranceAxle4Left : 12|2@1+ (1,0) [0|3] "" Vector__XXX
 SG_ TrctrBrkClprLnngClrnceAxle3Right : 10|2@1+ (1,0) [0|3] "" Vector__XXX
 SG_ TrctrBrkClprLnngClranceAxle3Left : 8|2@1+ (1,0) [0|3] "" Vector__XXX
 SG_ TrctrBrkClprLnngClrnceAxle2Right : 6|2@1+ (1,0) [0|3] "" Vector__XXX
 SG_ TrctrBrkClprLnngClranceAxle2Left : 4|2@1+ (1,0) [0|3] "" Vector__XXX
 SG_ TrctrBrkClprLnngClrnceAxle1Right : 2|2@1+ (1,0) [0|3] "" Vector__XXX
 SG_ TrctrBrkClprLnngClranceAxle1Left : 0|2@1+ (1,0) [0|3] "" Vector__XXX

BO_ 2566663166 CCVS4: 8 Vector__XXX
 SG_ CruiseCtrlAdjustedMaxSpeed : 16|16@1+ (0.00390625,0) [0|250.996] "km/h" Vector__XXX
 SG_ AppliedVehicleSpeedLimit : 0|16@1+ (0.00390625,0) [0|250.996] "km/h" Vector__XXX

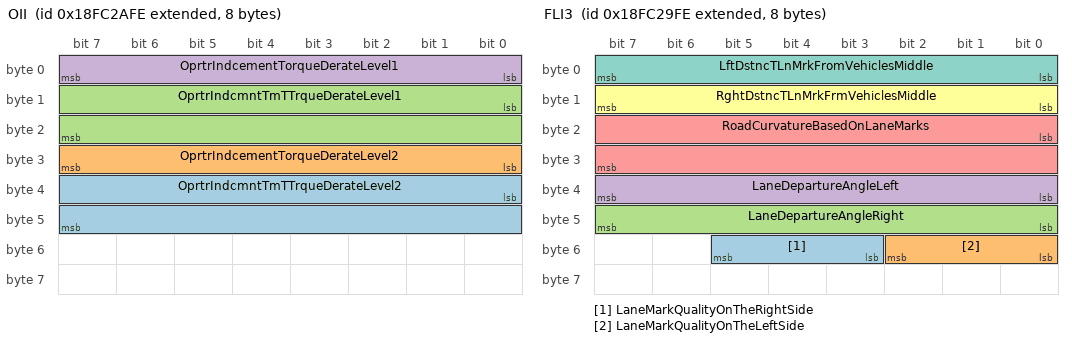
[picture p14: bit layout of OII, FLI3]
BO_ 2566662910 OII: 8 Vector__XXX
 SG_ OprtrIndcmntTmTTrqueDerateLevel2 : 32|16@1+ (1,0) [0|64255] "min" Vector__XXX
 SG_ OprtrIndcementTorqueDerateLevel2 : 24|8@1+ (1,0) [0|250] "%" Vector__XXX
 SG_ OprtrIndcmntTmTTrqueDerateLevel1 : 8|16@1+ (1,0) [0|64255] "min" Vector__XXX
 SG_ OprtrIndcementTorqueDerateLevel1 : 0|8@1+ (1,0) [0|250] "%" Vector__XXX

BO_ 2566662654 FLI3: 8 Vector__XXX
 SG_ LaneMarkQualityOnTheRightSide : 51|3@1+ (1,0) [0|7] "" Vector__XXX
 SG_ LaneMarkQualityOnTheLeftSide : 48|3@1+ (1,0) [0|7] "" Vector__XXX
 SG_ LaneDepartureAngleRight : 40|8@1+ (0.1,-12.5) [-12.5|12.5] "deg" Vector__XXX
 SG_ LaneDepartureAngleLeft : 32|8@1+ (0.1,-12.5) [-12.5|12.5] "deg" Vector__XXX
 SG_ RoadCurvatureBasedOnLaneMarks : 16|16@1+ (0.0078125,-250) [-250|251.992] "1/km" Vector__XXX
 SG_ RghtDstncTLnMrkFrmVehiclesMiddle : 8|8@1+ (0.02,0) [0|5] "m" Vector__XXX
 SG_ LftDstncTLnMrkFromVehiclesMiddle : 0|8@1+ (0.02,0) [0|5] "m" Vector__XXX

BO_ 2566662142 A1DEFI2: 8 Vector__XXX
 SG_ AT1DieselExhaustFluidCtrl2Temp : 8|8@1+ (1,-40) [-40|210] "°C" Vector__XXX
 SG_ AT1DieselExhaustFluidCtrl1Temp : 0|8@1+ (1,-40) [-40|210] "°C" Vector__XXX

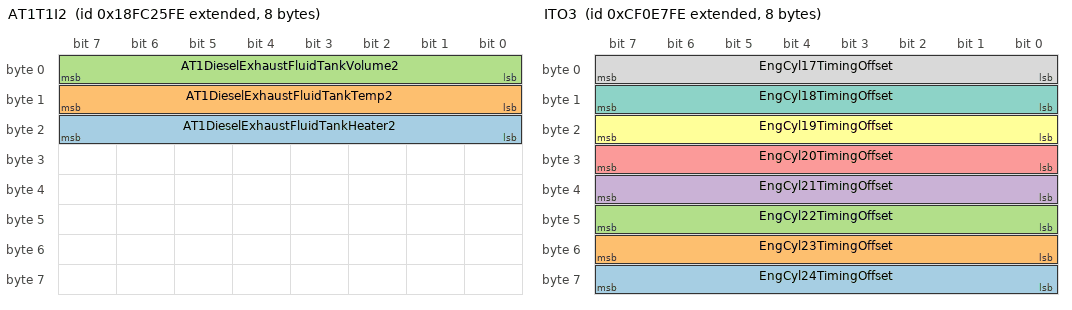
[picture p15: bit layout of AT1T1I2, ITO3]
BO_ 2566661630 AT1T1I2: 8 Vector__XXX
 SG_ AT1DieselExhaustFluidTankHeater2 : 16|8@1+ (0.4,0) [0|100] "%" Vector__XXX
 SG_ AT1DieselExhaustFluidTankTemp2 : 8|8@1+ (1,-40) [-40|210] "°C" Vector__XXX
 SG_ AT1DieselExhaustFluidTankVolume2 : 0|8@1+ (0.4,0) [0|100] "%" Vector__XXX

BO_ 2566661374 A2DEFT1: 8 Vector__XXX
 SG_ AT2DieselExhaustFluidCtrl2Temp : 8|8@1+ (1,-40) [-40|210] "°C" Vector__XXX
 SG_ AT2DieselExhaustFluidCtrlTemp : 0|8@1+ (1,-40) [-40|210] "°C" Vector__XXX
 SG_ AT2DieselExhaustFluidTankHeater2 : 16|8@1+ (0.4,0) [0|100] "%" Vector__XXX
 SG_ AT2DieselExhaustFluidTankTemp2 : 8|8@1+ (1,-40) [-40|210] "°C" Vector__XXX
 SG_ AT2DieselExhaustFluidTankVolume2 : 0|8@1+ (0.4,0) [0|100] "%" Vector__XXX

BO_ 2364598270 ITO3: 8 Vector__XXX
 SG_ EngCyl24TimingOffset : 56|8@1+ (0.1,-12.5) [-12.5|12.5] "deg" Vector__XXX
 SG_ EngCyl23TimingOffset : 48|8@1+ (0.1,-12.5) [-12.5|12.5] "deg" Vector__XXX
 SG_ EngCyl22TimingOffset : 40|8@1+ (0.1,-12.5) [-12.5|12.5] "deg" Vector__XXX
 SG_ EngCyl21TimingOffset : 32|8@1+ (0.1,-12.5) [-12.5|12.5] "deg" Vector__XXX
 SG_ EngCyl20TimingOffset : 24|8@1+ (0.1,-12.5) [-12.5|12.5] "deg" Vector__XXX
 SG_ EngCyl19TimingOffset : 16|8@1+ (0.1,-12.5) [-12.5|12.5] "deg" Vector__XXX
 SG_ EngCyl18TimingOffset : 8|8@1+ (0.1,-12.5) [-12.5|12.5] "deg" Vector__XXX
 SG_ EngCyl17TimingOffset : 0|8@1+ (0.1,-12.5) [-12.5|12.5] "deg" Vector__XXX

CM_ BO_ 2364473170 "Message used to claim an address for a Controller Application.";
CM_ SG_ 2364473170 IndustryGroup "0 = Global; 
   1  = On-Highway; 
   2  = Agricultural and Forestry; 
   3  = Construction; 
   4  = Marine;
   5  = Industrial - Process
          Control - Stationary (Gen-Sets)
   6  = Reserve for SAE
   7  = Reserve for SAE";
CM_ SG_ 2364473170 ManufacturerCode "Assigned by NMEA 2000 Committee";
CM_ BO_ 2364473169 "Message used to claim an address for a Controller Application.";
CM_ SG_ 2364473169 IndustryGroup "0 = Global; 
   1  = On-Highway; 
   2  = Agricultural and Forestry; 
   3  = Construction; 
   4  = Marine;
   5  = Industrial - Process
          Control - Stationary (Gen-Sets)
   6  = Reserve for SAE
   7  = Reserve for SAE";
CM_ SG_ 2364473169 ManufacturerCode "Assigned by NMEA 2000 Committee";
CM_ BO_ 2566838014 "This message can be sent by any controller that has hybrid system related information.";
CM_ SG_ 2566838014 HybrdSystmCstngRgnrtvBrkngLvlSlc "Indicates the coasting regenerative braking level selector position.  Coasting regenerative braking occurs when neither the accelerator nor the brake pedal are depressed.
The coasting regenerative braking level is the position of the driver’s ...";
CM_ SG_ 2566838014 HybrdSystmBrkPdlRgnrtvBrkngDsblS "Indicates the brake pedal regenerative braking disable switch position.  This switch allows the operator to disable regenerative braking (e.g. such as during slippery road conditions) that is controlled by brake pedal application.   Regenerative ...";
CM_ SG_ 2566838014 HybrdSystmRgnrtvBrkngDsbleSwitch "Indicates the regenerative braking disable switch position.  This switch gives the operator the ability to disable all regenerative braking from all inputs (e.g. such as during slippery road conditions).
00 = Regenerative Braking Disable Switch is ...";
CM_ SG_ 2566838014 HybrdSystmOffBrdChrgrCnnctnSttus "Indicates the off-board plug-in charger connection status.  One of the uses of this signal is to protect against vehicle motion while a charger is plugged in.
00 = Off-board charger is not connected
01 = Off-board charger is connected
10 = Error
 ...";
CM_ SG_ 2566838014 HybrdSystmPwrElctrncsClntLvlSwtc "Indicates the coolant level switch position in the hybrid system power electronics (e.g. Inverters, DC/DC converters) cooling system.

00 = Coolant Level is not sufficient
01 = Coolant Level is sufficient
10 = Error
11 = Not Available";
CM_ SG_ 2566838014 HybrdSystmPrplsnClantLevelSwitch "Indicates the coolant level switch position in the hybrid system propulsion (e.g. electric motor, generator) cooling system.

00 = Coolant Level is not sufficient
01 = Coolant Level is sufficient
10 = Error
11 = Not Available";
CM_ SG_ 2566838014 HybrdSystmPrtctionOverrideSwitch "Indicates the Protection Override switch position.  This switch allows the operator to override hybrid system protection features and failure modes allowing hybrid system to continue to operate if possible.
00 = Not Active
01 = Active
10 = Error
 ...";
CM_ BO_ 2566761726 "Configuration information for engine fuel system.";
CM_ SG_ 2566761726 EngIdleFuelFlowRateThreshold "A configuration value that indicates the maximum flow rate for engine idle operation.";
CM_ SG_ 2566761726 NmbrOfFlCnsmptnMntrngTransducers "The number of fuel consumption monitoring transducers installed in the fuel consumption monitoring system.";
CM_ BO_ 2566756350 "Message for reporting information associated with liquid fuel.";
CM_ SG_ 2566756350 EngFuelReturnTemp "The temperature of the fuel flowing through a fuel return line from the engine back to the fuel tank.";
CM_ SG_ 2566756350 EngFuelSupplyTemp "The temperature of the fuel flowing through a fuel supply line from the fuel tank to the engine.";
CM_ BO_ 2566756094 "Message for reporting information associated with liquid fuel.";
CM_ SG_ 2566756094 EngFuelReturnFlowRate "The rate of fuel flowing through a fuel return line carrying fuel from the engine back to fuel tank.";
CM_ SG_ 2566756094 EngFuelSupplyFlowRate "The rate of fuel flowing through a fuel supply line carrying fuel from the fuel tank to the engine.";
CM_ BO_ 2566687998 "This message contains information for the particulate sensor in bank 1 of a 2 bank system or the particulate sensor in a single bank system.

This sensor is downstream of the DPF.";
CM_ SG_ 2566687998 AT1PrtcltSnsrTmBtwnRegenerations "This is the time between the last two successful regenerations of the particulate sensor. If two successful particulate sensor regenerations have not ever occurred on this sensor, then this value shall be 0.";
CM_ SG_ 2566687998 AT1PrtcltSnsrActvAccmulationTime "This is the amount of time since the last successful regeneration completed.  The sensor has been accumulating particulate matter since that time.";
CM_ SG_ 2566687998 AT1PrtcltSensorRegenerationState "Indicates if the particulate sensor regeneration is currently active, and if so, the reason for the regeneration.
0000 - Regeneration is not active
0001 - Regneration is active and has been initiated by request via SPN 6783
0010 - Regeneration is ...";
CM_ SG_ 2566687998 AT1PrtcltSnsorRegenerationStatus "The status of the most recent attempt of this operational cycle to activate the particulate sensor regeneration process. This will not be updated until the regeneration is no longer active, as indicated by SPN 6774.
Operational cycle refers to the ...";
CM_ SG_ 2566687998 AT1ParticulateSensorHeaterState "The states of the particulate sensor heater.  The heater will change states from 11 to 10, 10 to 01, and 01 to 00 in a typical heating event.
00 - Heater is in closed loop control
01 - Heater is being held at a specified level
10 - Heater is in ...";
CM_ SG_ 2566687998 AT1ParticulateSensorResistance "This sensor is located in the exhaust stream somewhere after the DPF, but not necessarily immediately after the DPF.  It provides a resistance value that can be used to determine particulate matter in the exhaust stream. The value in this parameter ...";
CM_ BO_ 2566687742 "This message contains information for the particulate sensor in bank 1 of a 2 bank system or the particulate sensor in a single bank system.

This sensor is downstream of the DPF.";
CM_ SG_ 2566687742 AT1PrtclteSensorHeaterResistance "The resistance of the particulate sensor heater.";
CM_ SG_ 2566687742 AT1PrticulateSensorMaxResistance "This is the maximum resistance that the particulate sensor can measure.";
CM_ SG_ 2566687742 AT1ParticulateSensorTemp "Temperature of the particulate sensor.";
CM_ SG_ 2566687742 AT1PrtcltSnsrRgnrtionFailedCount "This is the number of times that the particulate sensor regeneration process has been attempted but failed to complete.";
CM_ SG_ 2566687742 AT1ParticulateSensorPowerSupply "State signal which indicates when the Aftertreatment 1 particulate sensor has power applied to it. Note that this is referring to the power supplied to the sensor, not the power supplied to the controller connected to the sensor.
00 – Off
01 – On
 ...";
CM_ SG_ 2566687742 AT1PrtclateSensorDetectionStatus "Detection status of the particulate sensor
0000 – Initialization for particulate matter detection
0001 – Waiting for dew point (see SPN 6784)
0010 – Particulate matter detection
0011 – Heater is active for particulate sensor regeneration
0100 – ...";
CM_ BO_ 2365348350 "This PGN contains information relating to integrated engine load sharing status values.";
CM_ SG_ 2365348350 EngLoadShareStatus "This signal indicates that the status of an engine load sharing feature.

0000 - Offline
0001 - Master
0010 - Slave
0011 - Loading
0100 - Unloading
0101 -1101 - Reserved
1110 - Error
1111 - Unavailable";
CM_ SG_ 2365348350 EngUnloadStatus "This signal indicates the status of an external request to unload the engine, such as the external unload request switch.

00 - Not Requested
01 - Requested
10 - Error
11 - Not Available";
CM_ BO_ 2566674686 "Turbocharger Information";
CM_ SG_ 2566674686 EngTurbo4LubeOilPress "Gage pressure of oil in the lubrication system for the 4th turbocharger.";
CM_ SG_ 2566674686 EngTurbo3LubeOilPress "Gage pressure of oil in the lubrication system for the 3rd turbocharger.";
CM_ SG_ 2566674686 EngTurbo2LubeOilPress "Gage pressure of oil in the lubrication system for the 2nd turbocharger.";
CM_ BO_ 2566674430 "Contains timers that indicate how long specific causes for inducement have been active.";
CM_ SG_ 2566674430 DslExhstFldQalityMalfunctionTime "Indicates the amount of time an error has been active due to detection of low Diesel Exhaust Fluid Quality. This will accumulate over the life of the product and will never be reset.";
CM_ SG_ 2566674430 DieselExhaustFluidTank1EmptyTime "Indicates the time the Diesel Exhaust Fluid Tank 1 Level is indicated as empty. This will accumulate over the life of the product and will never be reset.";
CM_ BO_ 2566674174 "Contains parameters that are related to SCR inducement.";
CM_ SG_ 2566674174 SCROperatorInducementTotalTime "Indicates the time that operator inducement has been active. This will accumulate over the life of the product and will never be reset.";
CM_ SG_ 2566674174 ATSCRMalfunctionTime "Indicates the amount of time an error condition has been active due to a malfunction in the Aftertreatment SCR system.
The source of the malfunction condition could be a component failure, detection of tampering, or other reason that prevents ...";
CM_ BO_ 2566673406 "Used to transmit the gaseous fuel leakage information determined by the engine monitoring system.";
CM_ SG_ 2566673406 GasLeakageDetection3Press "Pressure measured in gas leakage detection point 3. Measured media is of the gas, meaning it could be air, inert gas, fuel air mixture or charge air mixture, depending on the failure mode detected. The third measurement point is in a separate leak ...";
CM_ SG_ 2566673406 GasLeakageDetection2Press "Pressure measured in gas leakage detection point 2. Measured media is of the gas, meaning it could be air, inert gas, fuel air mixture or charge air mixture, depending on the failure mode detected. The second measurement point is either another ...";
CM_ SG_ 2566673406 GasLeakageDetection1Press "Pressure measured in gas leakage detection point 1. Measured media is of the gas, meaning it could be air, inert gas, fuel air mixture or charge air mixture, depending on the failure mode detected. The measurement point is typically in the engine ...";
CM_ SG_ 2566673406 GasFuelLeakage3Concentration "Percentage of detected gaseous fuel leak compared to the lower explosion limit (LEL). 100% means the measured value is on the lower explosion limit. 0% means no detected gaseous fuel in measurement point. The third measurement point is in a separate ...";
CM_ SG_ 2566673406 GasFuelLeakage2Concentration "Percentage of detected gaseous fuel leak compared to the lower explosion limit (LEL). 100% means the measured value is on the lower explosion limit. 0% means no detected gaseous fuel in measurement point. The second  measurement point is either ...";
CM_ SG_ 2566673406 GasFuelLeakage1Concentration "Percentage of detected gaseous fuel leak compared to the lower explosion limit (LEL). 100% means the measured value is on the lower explosion limit. 0% means no detected gaseous fuel in measurement point. The measurement point is typically in the ...";
CM_ BO_ 2633782014 "Used to transmit bin weights.

Note:  This PGN is transmitted for as many Bin Instances as exist on the vehicle.";
CM_ SG_ 2633782014 NetBinWeight "Mass of bin contents at most recent unload";
CM_ SG_ 2633782014 BinLiftCount "Increments with each lift, whether or not net bin weight changes.  The count rolls over at data range limit.

The count can be reset using SPN 6898 in PGN 56832.";
CM_ SG_ 2633782014 BinWeighingErrorStatus "Bin weighing error status

0 = No error
1 = Bad lift cycle
2 = Weighing error: bin lifted, not emptied
3 = Weighing error: empty bin lifted, emptied
4 - 14 = Reserved
15 = Not available / not applicable";
CM_ SG_ 2633782014 BinInstance "Gives the instance of the bin on the vehicle whose parameters are transmitted in the remainder of the PGN, with the first or only bin as instance 1.";
CM_ BO_ 2365346302 "Used for suspension control information";
CM_ SG_ 2365346302 LiftAxle2Status "Indicates the status of a tag axle 2.  Numbering of lift/tag axles starts at front axle.  SPN 1822 may be used if less detail is acceptable.
000 - Down (tag axle is laden)
001 - Unloading (load is being transferred from the tag axle)
010 - ...";
CM_ SG_ 2365346302 LiftAxle1Status "Indicates the status of a tag axle 1.  Numbering of lift/tag axles starts at front axle.  SPN 1743 may be used if less detail is acceptable.
000 - Down (tag axle is laden)
001 - Unloading (load is being transferred from the tag axle)
010 - ...";
CM_ BO_ 2566672638 "Status Information for Payload Measurement Systems.
 
This provides the last haul cycle payload information to the operator.";
CM_ SG_ 2566672638 DeliveredPayloadConfidence "The level of confidence of the delivered payload weight measurement. Higher confidence values indicate greater probability the delivered payload weight is the actual weight and providing feedback on the potential for improving system accuracy.";
CM_ SG_ 2566672638 DeliveredPayloadWeight "The delivered payload mass during the last haul cycle. This is the amount of material moved and delivered by a machine is a key work cycle parameter.
Delivered payload weight is defined as the last loaded weight less the carry back weight (material ...";
CM_ SG_ 2566672638 HaulModeStatus "The current operating state of the haul cycle.
0000 - Not in Haul Mode
0001 - Loading -- Payload is being added to the machine
0010 - Approaching Loaded -- Machine is near its maximum capacity
0011 - Loaded -- Loading operation has been ...";
CM_ SG_ 2566672638 HaulCycleCount "A counter incremented by 1 with each instance of a new haul cycle, defined as a dump to dump cycle. The counter shall increment from 0 to 64255, rolling over to 0 on the next increment after 64255.";
CM_ BO_ 2566672382 "Staus Information on each Payload sensor in a payload measurement system";
CM_ SG_ 2566672382 PayloadWeightSensor8Status "Status of the payload system sensor 8 measurement.

00 = Sensor fully functional
01 = Sensor degraded
10 = Error (Sensor failed)
11 = Not available";
CM_ SG_ 2566672382 PayloadWeightSensor7Status "Status of the payload system sensor 7 measurement.

00 = Sensor fully functional
01 = Sensor degraded
10 = Error (Sensor failed)
11 = Not available";
CM_ SG_ 2566672382 PayloadWeightSensor6Status "Status of the payload system sensor 6 measurement.

00 = Sensor fully functional
01 = Sensor degraded
10 = Error (Sensor failed)
11 = Not available";
CM_ SG_ 2566672382 PayloadWeightSensor5Status "Status of the payload system sensor 5 measurement.

00 = Sensor fully functional
01 = Sensor degraded
10 = Error (Sensor failed)
11 = Not available";
CM_ SG_ 2566672382 PayloadWeightSensor4Status "Status of the payload system sensor 4 measurement.

00 = Sensor fully functional
01 = Sensor degraded
10 = Error (Sensor failed)
11 = Not available";
CM_ SG_ 2566672382 PayloadWeightSensor3Status "Status of the payload system sensor 3 measurement.

00 = Sensor fully functional
01 = Sensor degraded
10 = Error (Sensor failed)
11 = Not available";
CM_ SG_ 2566672382 PayloadWeightSensor2Status "Status of the payload system sensor 2 measurement.

00 = Sensor fully functional
01 = Sensor degraded
10 = Error (Sensor failed)
11 = Not available";
CM_ SG_ 2566672382 PayloadWeightSensor1Status "Status of the payload system sensor 1 measurement.

00 = Sensor fully functional
01 = Sensor degraded
10 = Error (Sensor failed)
11 = Not available";
CM_ BO_ 2566672126 "This message contains additional  SCR dosing system information for aftertreatment system 1 (or bank 1).";
CM_ SG_ 2566672126 AT1DieselExhaustFluidDoser2Temp "The temperature (measured closest to dosing valve) of the second DEF dosing unit for aftertreatment system 1 (exhaust bank 1).";
CM_ SG_ 2566672126 AT1DslExhaustFluidDoser2AbsPress "The SCR doser 2 diesel exhaust fluid absolute pressure (measured closest to dosing valve) for aftertreatment system 1 (exhaust bank 1).";
CM_ SG_ 2566672126 AT1DieselExhaustFluidDosingPress "The SCR dosing diesel exhaust fluid gage pressure (measured closest to dosing valve) for aftertreatment system 1 (exhaust bank 1). This is the gage equivalent to SPN 4334.";
CM_ BO_ 2566671870 "This message contains additional  SCR dosing system information for aftertreatment system 2 (or bank 2).";
CM_ SG_ 2566671870 AT2DieselExhaustFluidDosingPress "The SCR dosing diesel exhaust fluid gage pressure (measured closest to dosing valve) for aftertreatment system 2 (exhaust bank 2). This is the gage equivalent to SPN 4387.";
CM_ BO_ 2566671614 "Contains parameters related to overriding the operator inducement.";
CM_ SG_ 2566671614 TtlNmbrOfSCROprtrIndcmntOvrrdEvn "Indicates total number of operator inducement override events activated throughout the lifetime of engine operation.
This number will remain at the maximum value once it is reached.
See EU Commission directive 2012/46/EU. Appendix 1 Section 5.5 ...";
CM_ SG_ 2566671614 NmbrOfSCROprtrIndcmntOvrrdEvntsR "During an operator inducement event, the operator may be able to override the inducement multiple times. This parameter indicates the remaining number of times that the currently active inducement can be overridden during an operator inducement ...";
CM_ SG_ 2566671614 SCROprtrIndcmntOvrrdTmeRemaining "This parameter is used to indicate the time remaining during an operator inducement override event.  See also SPN 7344 for an alternate SLOT.
When an operator inducement is not active, this parameter indicates the maximum time that an operator ...";
CM_ SG_ 2566671614 SCROprtrInducementOverrideEnable "Indicates if an operator inducement derate is allowed to be overridden.

Note: Inducement override is only allowed under certain conditions approved by EPA/ARB.

00 Override not allowed
01 Override allowed
10 SAE Reserved
11 Not available";
CM_ BO_ 2566671358 "This message includes some parameters that are used to support PEMS.
Manufacturers that support this PGN shall support both PEMS Engine Fuel Mass Flow Rate (SPN 6893) and Vehicle Fuel Rate (SPN 6894) even if the vehicle does not use fuel for the ...";
CM_ SG_ 2566671358 CylFuelRate "Cylinder fuel rate shall indicate the amount of fuel injected into the cylinder for combustion during the most recent intake stroke of the engine.

NOTE: Cylinder fuel rate shall indicate zero mg/stroke when the engine is not running.";
CM_ SG_ 2566671358 EngExhaustFlowRate "Engine Exhaust Flow Rate shall indicate the measured/calculated exhaust gas mass flow upstream of the aftertreatment system.
Engine Exhaust Flow Rate shall be calculated as the average exhaust flow rate over the last 1000 milliseconds prior to the ...";
CM_ SG_ 2566671358 VehicleFuelRate "Vehicle Fuel Rate shall indicate the amount of fuel consumed by the engine and fuel injected directly into the aftertreatment system per unit of time, in grams per second.
Vehicle Fuel Rate shall be calculated as the sum of the fuel consumed over ...";
CM_ SG_ 2566671358 PEMSEngFuelMassFlowRate "PEMS Engine Fuel Mass Flow Rate shall indicate the amount of fuel consumed by the engine per unit of time (does not include fuel injected directly into the aftertreatment system, but does include fuel injected into the engine cylinders for the ...";
CM_ BO_ 2566671102 "Contains information about cleaning the SCR system in the aftertreatment system.
If there are aftertreatment systems on two banks, this PGN represents the composite information from both banks.
NOTE: This message will be transmitted by the engine ...";
CM_ SG_ 2566671102 SCRSystemCleaningForcedStatus "Indicates the forced execution status of SCR system cleaning.
000 Not Active
001 Active – Forced by Switch (See SPN 3696)
010 Active – Forced by Service Tool
011 Reserved for SAE Assignment
100 Reserved for SAE Assignment
101 Reserved for SAE ...";
CM_ SG_ 2566671102 SCRSystmClnngAtmtcIntationConfig "Indicates the configuration of SCR system cleaning automatic initiation.

00 not enabled
01 enabled
10 reserved for SAE assignment
11 not available";
CM_ SG_ 2566671102 SCRSystmClnngInhbtdDTVhclSpdBlwA "Indicates the state of SCR system cleaning inhibition due to the vehicle speed being less than the allowed vehicle speed.
00 not inhibited
01 inhibited
10 reserved for SAE assignment
11 not available
This SPN indicates the reason for the SCR ...";
CM_ SG_ 2566671102 SCRSystmClnngInhbtdDTEngNtWrmdUp "Indicates the state of SCR system cleaning inhibition due to the engine not being warmed up.
00 not inhibited
01 inhibited
10 reserved for SAE assignment
11 not available
This SPN indicates the reason for the SCR system cleaning event not being ...";
CM_ SG_ 2566671102 SCRSystmClnngInhbtdDTPrmnntSystm "Indicates the state of SCR system cleaning inhibition due to a permanent system lockout.
00 not inhibited
01 inhibited
10 reserved for SAE assignment
11 not available
This SPN indicates the reason for the SCR system cleaning event not being ...";
CM_ SG_ 2566671102 SCRSystmClnngInhbtdDTTmprrySystm "Indicates the state of SCR system cleaning inhibition due to a temporary system lockout.
00 not inhibited
01 inhibited
10 reserved for SAE assignment
11 not available
This SPN indicates the reason for the SCR system cleaning event not being ...";
CM_ SG_ 2566671102 SCRSystmClnngInhbtdDTSystmTmeout "Indicates the state of SCR system cleaning inhibition due to a system timeout.
00 not inhibited
01 inhibited
10 reserved for SAE assignment
11 not available
This SPN indicates the reason for the SCR system cleaning event not being initiated or ...";
CM_ SG_ 2566671102 SCRSystmClnngInhbtdDTSystmFltAct "Indicates the state of SCR system cleaning inhibition due to a system fault being active.
00 not inhibited
01 inhibited
10 reserved for SAE assignment
11 not available
This SPN indicates the reason for the SCR system cleaning event not being ...";
CM_ SG_ 2566671102 SCRSystmClnngInhbtdDTLwExhstTemp "Indicates the state of SCR system cleaning inhibition due to the exhaust temperature being too low.  This implies that the SCR system is too cold for cleaning.
00 not inhibited
01 inhibited
10 reserved for SAE assignment
11 not available
This ...";
CM_ SG_ 2566671102 SCRSystmClnngInhbtdDTPrkngBrkNtS "Indicates the state of SCR system cleaning inhibition due to the parking brake being not set.
00 not inhibited
01 inhibited
10 reserved for SAE assignment
11 not available
This SPN indicates the reason for the SCR system cleaning event not ...";
CM_ SG_ 2566671102 SCRSystmClnngInhbtdDTVhclSpdAbvA "Indicates the state of SCR system cleaning inhibition due to the vehicle speed being above an allowed limit.
00 not inhibited
01 inhibited
10 reserved for SAE assignment
11 not available
This SPN indicates the reason for the SCR system cleaning ...";
CM_ SG_ 2566671102 SCRSystmClnngInhbtdDTOtOfNeutral "Indicates the state of SCR system cleaning inhibition due to the accelerator pedal being out of neutral.
00 not inhibited
01 inhibited
10 reserved for SAE assignment
11 not available
This SPN indicates the reason for the SCR system cleaning ...";
CM_ SG_ 2566671102 SCRSystmClnngInhbtdDTAcclPdlOffI "Indicates the state of SCR system cleaning inhibition due to the accelerator pedal being off idle.
00 not inhibited
01 inhibited
10 reserved for SAE assignment
11 not available
This SPN indicates the reason for the SCR system cleaning event not ...";
CM_ SG_ 2566671102 SCRSystmClnngInhbtdDeToPTOActive "Indicates the state of SCR system cleaning inhibition due to the PTO being active.
00 not inhibited
01 inhibited
10 reserved for SAE assignment
11 not available
This SPN indicates the reason for the SCR system cleaning event not being initiated ...";
CM_ SG_ 2566671102 SCRSystmClnngInhbtdDTSrvcBrkActv "Indicates the state of SCR system cleaning inhibition due to the service brake being active.
00 not inhibited
01 inhibited
10 reserved for SAE assignment
11 not available
This SPN indicates the reason for the SCR system cleaning event not being ...";
CM_ SG_ 2566671102 SCRSystmClnngInhbtdDTCltchDsnggd "Indicates the state of SCR system cleaning event inhibition due to the clutch being disengaged.
00 not inhibited
01 inhibited
10 reserved for SAE assignment
11 not available
This SPN indicates the reason for the SCR system cleaning event not ...";
CM_ SG_ 2566671102 SCRSystmClnngInhbtdDTInhbtSwitch "Indicates the state of SCR system cleaning inhibition due to the SCR system cleaning Inhibit Switch.
00 not inhibited
01 inhibited
10 reserved for SAE assignment
11 not available
This SPN indicates the reason for the SCR system cleaning event ...";
CM_ SG_ 2566671102 SCRSystemCleaningInhibitedStatus "Indicates the state of SCR system cleaning inhibition.
00 not inhibited
01 inhibited
10 reserved for SAE assignment
11 not available
This SPN indicates the reason for the SCR system cleaning event not being initiated or being exited prior to ...";
CM_ SG_ 2566671102 SCRSystemCleaningStatus "Indicates the state of SCR system cleaning.  This is an aggregate of bank 1 and bank 2.  It is a system status and not individual bank status.
00 not active
01 active
10 SCR system cleaning is needed - automatically initiated SCR system cleaning ...";
CM_ SG_ 2566671102 SCRSystemCleaningLampCmd "Command to control the SCR system cleaning lamp.
000 Off
001 On – solid
010 reserved for SAE assignment
011 reserved for SAE assignment
100 On – fast blink (1 HZ)
101 reserved for SAE assignment
110 reserved for SAE assignment
111 not ...";
CM_ BO_ 2566670846 "Contains information about the history of the aftertreatment 1 system";
CM_ SG_ 2566670846 AT1SCRSystmAvrgDstncBtwnSystmCln "Indicates the average distance since last reset between cleaning events for the SCR system in bank 1.

If the manufacturer allows this parameter to be reset, this distance is the average since last reset.";
CM_ SG_ 2566670846 AT1SCRSystmAvrgTmBtwnSystmClnngE "Indicates the average time since last reset between cleaning events for the SCR system in bank 1.
 
If the manufacturer allows this parameter to be reset, this time is the average since last reset.";
CM_ SG_ 2566670846 AT1SCRSystmTtlNmbrOfSystmClnngMn "Total number of manual cleaning requests on the SCR system in bank 1 by the operator over the lifetime of the device.";
CM_ SG_ 2566670846 AT1SCRSystmTtlNmbrOfSystmClnngIn "Total number of cleaning inhibit requests on the SCR system in bank 1 by the operator over the lifetime of the device.";
CM_ SG_ 2566670846 AT1SCRSystmTtlNmbrOfSystmClnngEv "Total number of cleaning events that have occurred on the SCR system in bank 1 over the lifetime of the device.";
CM_ SG_ 2566670846 AT1SCRSystemTotalCleaningTime "Total amount of time that a cleaning event has been active in the SCR system in bank 1 over the lifetime of the device.";
CM_ BO_ 2566670590 "Contains information about the history of the aftertreatment 2 system";
CM_ SG_ 2566670590 AT2SCRSystmAvrgDstncBtwnSystmCln "Indicates the average distance since last reset between cleaning events for the SCR system in bank 2.

If the manufacturer allows this parameter to be reset, this distance is the average since last reset.";
CM_ SG_ 2566670590 AT2SCRSystmAvrgTmBtwnSystmClnngE "Indicates the average time since last reset between cleaning events for the SCR system in bank 2.

If the manufacturer allows this parameter to be reset, this time is the average since last reset.";
CM_ SG_ 2566670590 AT2SCRSystmTtlNmbrOfSystmClnngMn "Total number of manual cleaning requests on the SCR system in bank 2 by the operator over the lifetime of the device.";
CM_ SG_ 2566670590 AT2SCRSystmTtlNmbrOfSystmClnngIn "Total number of cleaning inhibit requests on the SCR system in bank 2 by the operator over the lifetime of the device.";
CM_ SG_ 2566670590 AT2SCRSystmTtlNmbrOfSystmClnngEv "Total number of cleaning events that have occurred on the SCR system in bank 2 over the lifetime of the device.";
CM_ SG_ 2566670590 AT2SCRSystmTtlSystemCleaningTime "Total amount of time that a cleaning event has been active in the SCR system in bank 2 over the lifetime of the device.";
CM_ BO_ 2566670334 "Used by the tire monitoring system to report the number of tires, number of axles and number of tires on each axle it is monitoring on a specific vehicle. The axle number increments from front to rear of the vehicle per forward vehicle travel ...";
CM_ SG_ 2566670334 Axle12MonitoredTireCount "The number of tires on Axle 12 which are monitored by the tire monitor controller. The axle number increments from front to rear of the vehicle when facing the vehicle in the forward vehicle travel orientation. If the axle is not monitored by the ...";
CM_ SG_ 2566670334 Axle11MonitoredTireCount "The number of tires on Axle 11 which are monitored by the tire monitor controller. The axle number increments from front to rear of the vehicle when facing the vehicle in the forward vehicle travel orientation. If the axle is not monitored by the ...";
CM_ SG_ 2566670334 Axle10MonitoredTireCount "The number of tires on Axle 10 which are monitored by the tire monitor controller. The axle number increments from front to rear of the vehicle when facing the vehicle in the forward vehicle travel orientation. If the axle is not monitored by the ...";
CM_ SG_ 2566670334 Axle9MonitoredTireCount "The number of tires on Axle 9 which are monitored by the tire monitor controller. The axle number increments from front to rear of the vehicle when facing the vehicle in the forward vehicle travel orientation. If the axle is not monitored by the ...";
CM_ SG_ 2566670334 Axle8MonitoredTireCount "The number of tires on Axle 8 which are monitored by the tire monitor controller. The axle number increments from front to rear of the vehicle when facing the vehicle in the forward vehicle travel orientation. If the axle is not monitored by the ...";
CM_ SG_ 2566670334 Axle7MonitoredTireCount "The number of tires on Axle 7 which are monitored by the tire monitor controller. The axle number increments from front to rear of the vehicle when facing the vehicle in the forward vehicle travel orientation. If the axle is not monitored by the ...";
CM_ SG_ 2566670334 Axle6MonitoredTireCount "The number of tires on Axle 6 which are monitored by the tire monitor controller. The axle number increments from front to rear of the vehicle when facing the vehicle in the forward vehicle travel orientation. If the axle is not monitored by the ...";
CM_ SG_ 2566670334 Axle5MonitoredTireCount "The number of tires on Axle 5 which are monitored by the tire monitor controller. The axle number increments from front to rear of the vehicle when facing the vehicle in the forward vehicle travel orientation. If the axle is not monitored by the ...";
CM_ SG_ 2566670334 Axle4MonitoredTireCount "The number of tires on Axle 4 which are monitored by the tire monitor controller. The axle number increments from front to rear of the vehicle when facing the vehicle in the forward vehicle travel orientation. If the axle is not monitored by the ...";
CM_ SG_ 2566670334 Axle3MonitoredTireCount "The number of tires on Axle 3 which are monitored by the tire monitor controller. The axle number increments from front to rear of the vehicle when facing the vehicle in the forward vehicle travel orientation. If the axle is not monitored by the ...";
CM_ SG_ 2566670334 Axle2MonitoredTireCount "The number of tires on Axle 2 which are monitored by the tire monitor controller. The axle number increments from front to rear of the vehicle when facing the vehicle in the forward vehicle travel orientation. If the axle is not monitored by the ...";
CM_ SG_ 2566670334 Axle1MonitoredTireCount "The number of tires on Axle 1 which are monitored by the tire monitor controller. The axle number increments from front to rear of the vehicle when facing the vehicle in the forward vehicle travel orientation. If the axle is not monitored by the ...";
CM_ SG_ 2566670334 NumberOfTiresOnTheVehicle "The total number of tires monitored for tire parameters. A maximum of 250 tires is defined.";
CM_ SG_ 2566670334 NumberOfAxlesOnTheVehicle "The number of axles monitored for tire parameters. A maximum of 12 axles is defined.";
CM_ BO_ 2566670078 "The tire sensor identification number for each monitored tire.
Since there are multiple tire sensors to report, the message format will be a,b,c,d,b,c,d,b,c,d,b,c,d,...etc. where
a = Number of Tire Sensors
b = Tire Sensor Tire Number
c = Tire ...";
CM_ SG_ 2566670078 TireSensorIdentificationNumber "The identification number of tire sensor for the tire specified in the tire sensor tire number (SPN 6964) or tire sensor location (SPN 6965).";
CM_ SG_ 2566670078 TireSensorLocation "The location of monitored tire sensor on the vehicle.
The high order 4 bits indicate the vehicle axle position of the tire sensor, counting front to back on the vehicle, with the value 0 representing the front axle on the vehicle.
The low order 4 ...";
CM_ SG_ 2566670078 TireSensorTireNumber "The number of the monitored tire that corresponds with the Tire Sensor Identification Number (SPN 6966). The location of the numbered tire is reported in the Tire Sensor Location SPN.  The value 0xFF indicates this SPN is not used.";
CM_ SG_ 2566670078 NumberOfTireSensors "Total count of monitored tire sensor identification numbers represented in this instance of the parameter group.";
CM_ BO_ 2566669822 "The tire wireless signal strength indicator for each monitored tire. If there are multiple tire sensors with multiple antennas to report, the message format will be a,b,c,d,e,f,d,e,f,d,e,f,,...b,c,d,e,f,d,e,f,d,e,f,... b,c,d,e,f,d,e,f,d,e,f …..etc ...";
CM_ SG_ 2566669822 TrWrelessSignalStrengthIndicator "The wireless signal strength between the tire pressure sensor and the specified antenna, for the tire specified in the tire sensor number or tire sensor Location.";
CM_ SG_ 2566669822 TireLocation "The location of monitored tire on the vehicle.
The high order 4 bits indicate the vehicle axle position of the tire sensor, counting front to back on the vehicle, with the value 0 representing the front axle on the vehicle.
The low order 4 bits ...";
CM_ SG_ 2566669822 TireSensorNumber "The number of the monitored tire sensor that corresponds with the tire wireless signal strength indicator. The location of the numbered tire is reported in the tire sensor location SPN (SPN 6965). The value 0xFF indicates this SPN is not used.";
CM_ SG_ 2566669822 TtalNumberOfTireSensorsMonitored "Total number of tire sensors monitored for the specified antenna in this instance of the parameter group.";
CM_ SG_ 2566669822 AntennaNumber "Number of the antenna used to communicate signal strength of a group of sensors.  If a single antenna is used this will default to 0x01. When multiple antennas are used, the first antenna will have a value of 1, 2nd antenna will be 2, 3rd antenna ...";
CM_ SG_ 2566669822 TotalNumberOfAntennasUsed "Total count of antennas used in the specified vehicle system.";
CM_ BO_ 2566669310 "Details the attributes for the tire monitoring configuration status of the tires.
NOTE – Multiple instances of this message will be required to transmit data for all tire locations.  When reporting data for multiple tire locations, each successive ...";
CM_ SG_ 2566669310 OverTemp "The temperature above which the over temperature alert will trigger.";
CM_ SG_ 2566669310 OverPressPercentageThreshold "The percentage deviation from the set cold inflation pressure, for the over tire pressure alert.";
CM_ SG_ 2566669310 ExtrmUndrPrssPercentageThreshold "The percentage deviation from the set cold inflation pressure, for the extreme under tire pressure alert.";
CM_ SG_ 2566669310 UnderPressPercentageThreshold "The percentage deviation from the set cold inflation pressure, for the under tire pressure alert.";
CM_ SG_ 2566669310 ColdInflationPress "The cold inflation pressure of the tire. Cold inflation pressure is the default/reference inflation pressure suggested by the manufacturer for a specific tire.";
CM_ SG_ 2566669310 TireLocation "The location of monitored tire on the vehicle.
The high order 4 bits indicate the vehicle axle position of the tire sensor, counting front to back on the vehicle, with the value 0 representing the front axle on the vehicle.
The low order 4 bits ...";
CM_ BO_ 2566669054 "Tire Condition Message 2
NOTE – Multiple instances of this message will be required to transmit data for all tire locations.  When reporting data for multiple tire locations, each successive message, which provides data for a different tire ...";
CM_ SG_ 2566669054 RequiredTirePress "The required tire pressure at which air is contained in cavity formed by tire and rim.

This pressure of the tire is compensated to meet the specific physical environmental conditions (temperature) of the vehicle.";
CM_ SG_ 2566669054 TirePress "Pressure at which air is contained in cavity formed by tire and rim. See SPN 241 for alternate tire pressure with a lower range and coarser resolution.";
CM_ SG_ 2566669054 TireLocation "Identifies which tire is associated with the parametric data in PGN 64578. Refer to SPN 929 for further details and examples. The low order 4 bits represent a position number, counting left to right when facing in the direction of normal vehicle ...";
CM_ BO_ 2566668798 "Alternate Fuel 4";
CM_ SG_ 2566668798 EngFl2InjctorMeteringRail1Press2 "The second pressure of fuel 2 measured by first rail pressure sensor in the primary, or first, metering rail as delivered from the supply pump to the injector metering intake.";
CM_ SG_ 2566668798 EngFel2InjectorMeteringRail2Temp "The temperature of fuel 2 measured by first rail temperature sensor in the metering rail 2 as delivered from the supply pump to the injector metering intake.";
CM_ SG_ 2566668798 EngFel2InjectorMeteringRail1Temp "The temperature of fuel 2 measured by first rail temperature sensor in the primary, or first, metering rail as delivered from the supply pump to the injector metering intake.";
CM_ SG_ 2566668798 EngFl2InjectorMeteringRail2Press "The pressure of fuel 2 measured by first rail pressure sensor in the metering rail 2 as delivered from the supply pump to the injector metering intake.";
CM_ SG_ 2566668798 EngFl2InjectorMeteringRail1Press "The pressure of fuel 2 measured by first rail pressure sensor in the primary, or first, metering rail as delivered from the supply pump to the injector metering intake.";
CM_ BO_ 2566668542 "Hydraulically driven engine fuel 2 pump messages.";
CM_ SG_ 2566668542 EngFuel2PumpHydPress "Hydraulic pressure in the lines of the hydraulically driven fuel 2 pump.";
CM_ SG_ 2566668542 EngFuel2PumpHydDirectionalValve "Position of hydraulic directional valve to control application of hydraulic oil flow.  0% is no flow to the appliance; 100% is full flow to the appliance.";
CM_ SG_ 2566668542 EngFuel2PumpHydSwashPlateAngle "Position of hydraulic swash plate angle within hydraulic pump.  0% represents the lowest possible flow, 100% represents the maximum flow.";
CM_ SG_ 2566668542 EngFuel2PumpHydFlowCtrlValve "Position of hydraulic pump flow control valve opening; 0% = fully closed, 100% = fully open.";
CM_ BO_ 2566668286 "This PGN contains information on turbocharger commands.";
CM_ SG_ 2566668286 EngStagedTurboSolenoidStatus "Current state of the staged turbocharger solenoid, normalized to percent, 0% represents not actuated and 100% represents fully actuated.";
CM_ BO_ 2566668030 "Contains information about purging debris from the heat exchanger.";
CM_ SG_ 2566668030 HtExchngerDebrisPurgeApproaching "Status signal which indicates that purging the debris from the heat exchanger is imminent.

00     Not approaching
01     Approaching
10     SAE reserved
11     Not available";
CM_ SG_ 2566668030 HeatExchangerDebrisPurgeStatus "Indicates whether the system is currently purging debris from the heat exchanger.

00    Inactive
01    Active
10    SAE reserved
11    Not available";
CM_ BO_ 2566667774 "Used to transmit temperature values at end bearings for connecting rods in the engine cylinder";
CM_ SG_ 2566667774 EngEndBearing8Temp "Temperature of end bearing of the connecting rod for cylinder 8 on the engine";
CM_ SG_ 2566667774 EngEndBearing7Temp "Temperature of end bearing of the connecting rod for cylinder 7 on the engine";
CM_ SG_ 2566667774 EngEndBearing6Temp "Temperature of end bearing of the connecting rod for cylinder 6 on the engine";
CM_ SG_ 2566667774 EngEndBearing5Temp "Temperature of end bearing of the connecting rod for cylinder 5 on the engine";
CM_ SG_ 2566667774 EngEndBearing4Temp "Temperature of end bearing of the connecting rod for cylinder 4 on the engine";
CM_ SG_ 2566667774 EngEndBearing3Temp "Temperature of end bearing of the connecting rod for cylinder 3 on the engine";
CM_ SG_ 2566667774 EngEndBearing2Temp "Temperature of end bearing of the connecting rod for cylinder 2 on the engine";
CM_ SG_ 2566667774 EngEndBearing1Temp "Temperature of end bearing of the connecting rod for cylinder 1 on the engine";
CM_ BO_ 2566667518 "Used to transmit temperature values at end bearings for connecting rods in the engine cylinder";
CM_ SG_ 2566667518 EngEndBearing16Temp "Temperature of end bearing of the connecting rod for cylinder 16 on the engine";
CM_ SG_ 2566667518 EngEndBearing15Temp "Temperature of end bearing of the connecting rod for cylinder 15 on the engine";
CM_ SG_ 2566667518 EngEndBearing14Temp "Temperature of end bearing of the connecting rod for cylinder 14 on the engine";
CM_ SG_ 2566667518 EngEndBearing13Temp "Temperature of end bearing of the connecting rod for cylinder 13 on the engine";
CM_ SG_ 2566667518 EngEndBearing12Temp "Temperature of end bearing of the connecting rod for cylinder 12 on the engine";
CM_ SG_ 2566667518 EngEndBearing11Temp "Temperature of end bearing of the connecting rod for cylinder 11 on the engine";
CM_ SG_ 2566667518 EngEndBearing10Temp "Temperature of end bearing of the connecting rod for cylinder 10 on the engine";
CM_ SG_ 2566667518 EngEndBearing9Temp "Temperature of end bearing of the connecting rod for cylinder 9 on the engine";
CM_ BO_ 2566667262 "Used to transmit temperature values at end bearings for connecting rods in the engine cylinder";
CM_ SG_ 2566667262 EngEndBearing20Temp "Temperature of end bearing of the connecting rod for cylinder 20 on the engine";
CM_ SG_ 2566667262 EngEndBearing19Temp "Temperature of end bearing of the connecting rod for cylinder 19 on the engine";
CM_ SG_ 2566667262 EngEndBearing18Temp "Temperature of end bearing of the connecting rod for cylinder 18 on the engine";
CM_ SG_ 2566667262 EngEndBearing17Temp "Temperature of end bearing of the connecting rod for cylinder 17 on the engine";
CM_ BO_ 2499558142 "Used to transmit information on pressures at various points of Gaseous fuel supplied to the engine.";
CM_ SG_ 2499558142 GsFlSpplyShtoffValve2IntakePress "Pressure of gaseous fuel supply measured at shutoff valve 2 in gaseous fuel supply unit. Shutoff valves are used to regulate gaseous fuel supply to engine.";
CM_ SG_ 2499558142 GsFlSpplyShtoffValve1IntakePress "Pressure of gaseous fuel supply measured at shutoff valve 1 in gaseous fuel supply unit. Shutoff valves are used to regulate gaseous fuel supply to engine.";
CM_ SG_ 2499558142 GasFuelSupplyUnitIntakePress "Pressure of gaseous fuel supply measured at the intake of gaseous fuel supply unit. Gaseous fuel valve unit contains block and bleed valves to regulate the flow of gaseous fuel from the plant to engine.

Gas Supply Unit Intake Pressure";
CM_ SG_ 2499558142 EngGasFuelSupplyPress2 "Second gage pressure measurement of gaseous fuel supply to fuel metering device. If only one sensor is used for gas supply pressure measurement, use SPN 159 instead.";
CM_ BO_ 2499557886 "Used to transmit information on pressures at various points of Gaseous fuel supplied to the engine.";
CM_ SG_ 2499557886 PlantInertGasSupplyOutletPress "Pressure of the purge gas supplied to the engine. Inert gas is used to remove gaseous fuel build-up in the engines and in the fuel supply lines when gaseous fuel is not in operation.";
CM_ SG_ 2499557886 PlantGasFuelSupplyOutletPress "Pressure of the gaseous fuel supplied from the plant room for one or more engines.  Based on the application, plant room will contain fuel tank for gas, vaporizer and heater and cooler compartments.";
CM_ BO_ 2499557630 "Used to transmit oil mist information determined by the engine monitoring system";
CM_ SG_ 2499557630 EngOilMist8Concentration "Percentage of detected oil mist in compartment 8 compared to the lower explosion limit (LEL). 100% means the measured value is on the lower explosion limit,whereas 0% means no detected oil mist in the air.";
CM_ SG_ 2499557630 EngOilMist7Concentration "Percentage of detected oil mist in compartment 7 compared to the lower explosion limit (LEL). 100% means the measured value is on the lower explosion limit,whereas 0% means no detected oil mist in the air.";
CM_ SG_ 2499557630 EngOilMist6Concentration "Percentage of detected oil mist in compartment 6 compared to the lower explosion limit (LEL). 100% means the measured value is on the lower explosion limit,whereas 0% means no detected oil mist in the air.";
CM_ SG_ 2499557630 EngOilMist5Concentration "Percentage of detected oil mist in compartment 5 compared to the lower explosion limit (LEL). 100% means the measured value is on the lower explosion limit,whereas 0% means no detected oil mist in the air.";
CM_ SG_ 2499557630 EngOilMist4Concentration "Percentage of detected oil mist in compartment 4 compared to the lower explosion limit (LEL). 100% means the measured value is on the lower explosion limit,whereas 0% means no detected oil mist in the air.";
CM_ SG_ 2499557630 EngOilMist3Concentration "Percentage of detected oil mist in compartment 3 compared to the lower explosion limit (LEL). 100% means the measured value is on the lower explosion limit,whereas 0% means no detected oil mist in the air.";
CM_ SG_ 2499557630 EngOilMist2Concentration "Percentage of detected oil mist in compartment 2 compared to the lower explosion limit (LEL). 100% means the measured value is on the lower explosion limit,whereas 0% means no detected oil mist in the air.";
CM_ SG_ 2499557630 EngOilMist1Concentration "Percentage of detected oil mist in compartment 1 compared to the lower explosion limit (LEL). 100% means the measured value is on the lower explosion limit, whereas 0% means no detected oil mist in the air. This measurement is typically taken in ...";
CM_ BO_ 2499557374 "Used to transmit oil mist information determined by the engine monitoring system";
CM_ SG_ 2499557374 EngOilMist10Concentration "Percentage of detected oil mist in compartment 10 compared to the lower explosion limit (LEL). 100% means the measured value is on the lower explosion limit,whereas 0% means no detected oil mist in the air.";
CM_ SG_ 2499557374 EngOilMist9Concentration "Percentage of detected oil mist in compartment 9 compared to the lower explosion limit (LEL). 100% means the measured value is on the lower explosion limit,whereas 0% means no detected oil mist in the air.";
CM_ BO_ 2499557118 "Used to transmit information on valves on the gaseous fuel supply lines.";
CM_ SG_ 2499557118 InertGasSupplyValvePos "Position of inert gas supply valve used to control the flow of inert gas into the engine to purge the system.

0% represents valve fully closed and 100% represents valve fully open.";
CM_ SG_ 2499557118 GasFuelSupplyBleedValve3Pos "Position of bleed valve 3, which is used to control the flow of gaseous fuel through the fuel supply unit. 0% represents valve fully closed and 100% represents valve fully open.";
CM_ SG_ 2499557118 GasFuelSupplyBleedValve2Pos "Position of bleed valve 2, which is used to control the flow of gaseous fuel through the fuel supply unit. 0% represents valve fully closed and 100% represents valve fully open.";
CM_ SG_ 2499557118 GasFuelSupplyBleedValve1Pos "Position of bleed valve 1, which is used to control the flow of gaseous fuel through the fuel supply unit. 0% represents valve fully closed and 100% represents valve fully open.";
CM_ SG_ 2499557118 GasFuelSupplyShutoffValve2Pos "Position of shutoff valve 2, which is used to control the flow of gaseous fuel through the fuel supply unit. 0% represents valve fully closed and 100% represents valve fully open.";
CM_ SG_ 2499557118 GasFuelSupplyShutoffValve1Pos "Position of shutoff valve 1, which is used to control the flow of gaseous fuel through the fuel supply unit. 0% represents valve fully closed and 100% represents valve fully open.";
CM_ BO_ 2566665726 "Contains information on diesel exhaust fluid pumps for aftertreatment system 2.";
CM_ SG_ 2566665726 AT2DslExhustFluidPump2MotorSpeed "Rotational speed of the motor driving the second pump for the diesel exhaust fluid used in aftertreatment system 2 (exhaust bank 2).";
CM_ SG_ 2566665726 AT2DieselExhaustFluidPumpHeater "Percentage of heating applied to the aftertreatment 2 diesel exhaust fluid pump heater.  A value of 0% means no heating applied, a value of 100% means full heating applied. The diesel exhaust fluid pump heater warms the diesel exhaust fluid in the ...";
CM_ BO_ 2499556606 "Transmits the rail pressure information as measured by different rail pressure sensors.";
CM_ SG_ 2499556606 EngInjectorMeteringRail2Press2 "The pressure of fuel measured by second rail pressure sensor in the metering rail 2 as delivered from the supply pump to the injector metering intake.";
CM_ SG_ 2499556606 EngInjectorMeteringRail2Press1 "The pressure of fuel measured by first rail pressure sensor in the metering rail 2 as delivered from the supply pump to the injector metering intake.";
CM_ SG_ 2499556606 EngInjectorMeteringRail1Press2 "The pressure of fuel measured by the second rail pressure sensor in the primary, or first, metering rail as delivered from the supply pump to the injector metering intake.";
CM_ SG_ 2499556606 EngInjectorMeteringRail1Press1 "The pressure of fuel measured by first rail pressure sensor in the primary, or first, metering rail as delivered from the supply pump to the injector metering intake.";
CM_ BO_ 2499556350 "Transmits rail pressure information.";
CM_ SG_ 2499556350 EngInjctrMtringRail2DesiredPress "The desired pressure of fuel in metering rail 2 as delivered from the supply pump to the injector metering intake.";
CM_ SG_ 2499556350 EngInjctrMtringRail1DesiredPress "The desired pressure of fuel in the primary, or first, metering rail as delivered from the supply pump to the injector metering intake.";
CM_ BO_ 2499556094 "This message contains information for the particulate sensor in bank 1 of a 2 bank system or the particulate sensor in a single bank system.";
CM_ SG_ 2499556094 AT1PrtcltSnsrHtrPwrSpplyDgnstcSt "The value of this parameter is not retained when power is removed from the particulate sensor.
000 - Tests monitored continuously. There are no enable or pause conditions. See Aftertreatment 1 Particulate Sensor Heater Power Supply Preliminary FMI ...";
CM_ SG_ 2499556094 AT1PrtcltSnsrHtrPwrSpplyPrlmnryF "Used to identify the applicable J1939-73 FMI detected in the aftertreatment particulate sensor heater power supply by the manufacturer’s sensor control software in exhaust bank 1. When there is no failure FMI 31 is sent. In the case of multiple ...";
CM_ SG_ 2499556094 AT1PrtcltSnsrPwrSpplyDgnstcSttus "The value of this parameter is not retained when power is removed from the particulate sensor.
000 - Tests monitored continuously. There are no enable or pause conditions. See Aftertreatment 1 Particulate Sensor Power Supply Preliminary FMI (SPN ...";
CM_ SG_ 2499556094 AT1PrtcltSnsrPwrSpplyPrlmnaryFMI "Used to identify the applicable J1939-73 FMI detected in the aftertreatment particulate sensor power supply by the manufacturer’s sensor control software in exhaust bank 1. When there is no failure FMI 31 is sent. In the case of multiple failures ...";
CM_ SG_ 2499556094 AT1PrtcltSnsrInptDagnosticStatus "The value of this parameter is not retained when power is removed from the particulate sensor.
000 - Tests monitored continuously. There are no enable or pause conditions. See Aftertreatment 1 Particulate Sensor Input Preliminary FMI (SPN 7325) for ...";
CM_ SG_ 2499556094 AT1PrtcltSnsrInputPreliminaryFMI "Used to identify the applicable J1939-73 FMI detected in the aftertreatment particulate sensor input by the manufacturer’s sensor control software in exhaust bank 1. When there is no failure FMI 31 is sent. In the case of multiple failures the most ...";
CM_ SG_ 2499556094 AT1PrtcltSnsrHtrLwSdDrvrDgnstcSt "The value of this parameter is not retained when power is removed from the particulate sensor.
000 - Tests monitored continuously. There are no enable or pause conditions. See Aftertreatment 1 Particulate Sensor Heater Low Side Driver Preliminary ...";
CM_ SG_ 2499556094 AT1PrtcltSnsrHtrLwSdDrvrPrlmnryF "Used to identify the applicable J1939-73 FMI detected in the aftertreatment particulate sensor heater high side driver by the manufacturer’s sensor control software in exhaust bank 1. When there is no failure FMI 31 is sent. In the case of multiple ...";
CM_ SG_ 2499556094 AT1PrtcltSnsrHtrHghSdDrvrDgnstcS "The value of this parameter is not retained when power is removed from the particulate sensor.
000 - Tests monitored continuously. There are no enable or pause conditions. See Aftertreatment 1 Particulate Sensor Heater High Side Driver Preliminary ...";
CM_ SG_ 2499556094 AT1PrtcltSnsrHtrHghSdDrvrPrlmnry "Used to identify the applicable J1939-73 FMI detected in the aftertreatment particulate sensor heater high side driver by the manufacturer’s sensor control software in exhaust bank 1. When there is no failure FMI 31 is sent. In the case of multiple ...";
CM_ BO_ 2566664702 "The state of the aftertreatment system.";
CM_ SG_ 2566664702 ATAmbientAirTemp "Temperature of ambient air near the aftertreatment components such as DEF tank and DEF lines.";
CM_ SG_ 2566664702 ATEngLoadRq "Indicates whether the aftertreatment desires engine load to be applied. This is meant to notify the operator that the aftertreatment is requesting engine load for thermal purposes.
00 = No Request
01 = Aftertreatment Engine Load Desired
10 = ...";
CM_ SG_ 2566664702 ATEngSpeedCtrlRq "Indicates whether the aftertreatment desires engine speed control. This is meant to notify the operator that the aftertreatment is requesting engine speed control for thermal purposes.
00 = No Request
01 = Aftertreatment Engine Speed Control ...";
CM_ SG_ 2566664702 ATActvRgnrtnInhbtdDTLwExhstPress "The state of aftertreatment active regeneration inhibition due to low exhaust pressure.
Aftertreatment Regeneration is a process of increasing the temperature at the exhaust and thereby removing the deposits on aftertreatment components such as DPF ...";
CM_ SG_ 2566664702 ATThermalManagementStatus "Indicates whether Aftertreatment Thermal Management process is active.
Aftertreatment Thermal Management indicates that the exhaust temperatures have been controlled for the normal functioning of the aftertreatment system - This is not just limited ...";
CM_ BO_ 2633773310 "Contains parameters that are related to SCR inducement.";
CM_ SG_ 2633773310 SCROprtrIndcmntOvrrdTmeRemaining "Used to indicate the time remaining during an operator inducement override event.  When an operator inducement is active this parameter indicates the remaining time that the currently active operator inducement may be overridden.
See also SPN 6878 ...";
CM_ SG_ 2633773310 SCROprtrIndcmntOvrrdRnwlRequired "Indicates the required operator inducement override renewal state.

00 = Not Required
01 = Required
10 = Error
11 = Not Available";
CM_ SG_ 2633773310 SCROpratorInducementOverrideMode "Indicates the functional mode of SCR operator inducement override.
000          Not Available
001          Available - Not Active
010          Active
011          Active Extended
100          Expired
101-110  Not Defined
111          Not ...";
CM_ SG_ 2633773310 SCROprtrIndcmntEmrgncyOvrrdTtlRs "The total number of times the feature, which allows the operator to override the inducement strategies (as described in SPN 6880) during emergencies, such as hurricanes, has been reset.

This counter can not be reset.";
CM_ BO_ 2633773054 "Represents the status of various agents used for fire
suppression and solutions.";
CM_ SG_ 2633773054 FrSpprssnCmprssdArFmSystmArPress "Compressed Air Foam System (CAFS) air compressor pressure.";
CM_ SG_ 2633773054 FrSuppressionClassBFoamTankLevel "Liquid level of the Class-B foam agent tank.";
CM_ SG_ 2633773054 FrSuppressionClassAFoamTankLevel "Liquid level of the Class-A foam agent tank.";
CM_ SG_ 2633773054 FireSuppressionWaterTankLevel "Liquid level of the fire apparatus water tank.";
CM_ BO_ 2566663934 "Contains command signals to Turbocharger Compressor Blowoff, Wastegate, Cylinder Head Bypass
and Throttle Valve actuators.";
CM_ SG_ 2566663934 EngThrttlVlv1MotorCurrentDisable "Command to disable power to motor in the actuator to prevent unnecessary load on the component.

00 - Do Not Disable
01 - Disable
10 - Reserved
11 - Don't Care/Take No Action";
CM_ SG_ 2566663934 EngCylHdBypssActtr1MtrCrrntDsble "Command to disable power to motor in the actuator to prevent unnecessary load on the component.

00 - Do Not Disable
01 - Disable
10 - Reserved
11 - Don't Care/Take No Action";
CM_ SG_ 2566663934 EngTrbWstgtActtr1MtrCrrntDisable "Command to disable power to motor in the actuator to prevent unnecessary load on the component.

00 - Do Not Disable
01 - Disable
10 - Reserved
11 - Don't Care/Take No Action";
CM_ SG_ 2566663934 EngTrbCmprssrBlwffActtr1MtrCrrnt "Command to disable power to motor in the actuator to prevent unnecessary load on the component.

00 - Do Not Disable
01 - Disable
10 - Reserved
11 - Don't Care/Take No Action";
CM_ BO_ 2566663678 "Information on alternate fuel.";
CM_ SG_ 2566663678 EngFl2InjectorMeteringRail1Temp2 "The second temperature of fuel 2 measured by first rail temperature sensor in the primary, or first, metering rail as delivered from the supply pump to the injector metering intake.";
CM_ SG_ 2566663678 LNGTank2VaporPress "Gage pressure of the vapor in the second tank in a multi-tank system.";
CM_ SG_ 2566663678 LNGTank1VaporPress "Gage pressure of the vapor in the first tank in a multi-tank system (or unique tank if single-tank system).";
CM_ BO_ 2566663422 "Refers to disc brake caliper lining clearance condition.";
CM_ SG_ 2566663422 TrlrBrkClprLnngClranceAxle5Right "Brake caliper lining clearance for right brake on trailer axle 5.

00 - Caliper lining clearance is adequate
01 - Caliper lining clearance is low
10 - Error
11 - Not available / not applicable";
CM_ SG_ 2566663422 TrlrBrkClprLnngClaranceAxle5Left "Brake caliper lining clearance for left brake on trailer axle 5.

00 - Caliper lining clearance is adequate
01 - Caliper lining clearance is low
10 - Error
11 - Not available / not applicable";
CM_ SG_ 2566663422 TrlrBrkClprLnngClranceAxle4Right "Brake caliper lining clearance for right brake on trailer axle 4.

00 - Caliper lining clearance is adequate
01 - Caliper lining clearance is low
10 - Error
11 - Not available / not applicable";
CM_ SG_ 2566663422 TrlrBrkClprLnngClaranceAxle4Left "Brake caliper lining clearance for left brake on trailer axle 4.

00 - Caliper lining clearance is adequate
01 - Caliper lining clearance is low
10 - Error
11 - Not available / not applicable";
CM_ SG_ 2566663422 TrlrBrkClprLnngClranceAxle3Right "Brake caliper lining clearance for right brake on trailer axle 3.

00 - Caliper lining clearance is adequate
01 - Caliper lining clearance is low
10 - Error
11 - Not available / not applicable";
CM_ SG_ 2566663422 TrlrBrkClprLnngClaranceAxle3Left "Brake caliper lining clearance for left brake on trailer axle 3.

00 - Caliper lining clearance is adequate
01 - Caliper lining clearance is low
10 - Error
11 - Not available / not applicable";
CM_ SG_ 2566663422 TrlrBrkClprLnngClranceAxle2Right "Brake caliper lining clearance for right brake on trailer axle 2.

00 - Caliper lining clearance is adequate
01 - Caliper lining clearance is low
10 - Error
11 - Not available / not applicable";
CM_ SG_ 2566663422 TrlrBrkClprLnngClaranceAxle2Left "Brake caliper lining clearance for left brake on trailer axle 2.

00 - Caliper lining clearance is adequate
01 - Caliper lining clearance is low
10 - Error
11 - Not available / not applicable";
CM_ SG_ 2566663422 TrlrBrkClprLnngClranceAxle1Right "Brake caliper lining clearance for right brake on trailer axle 1.

00 - Caliper lining clearance is adequate
01 - Caliper lining clearance is low
10 - Error
11 - Not available / not applicable";
CM_ SG_ 2566663422 TrlrBrkClprLnngClaranceAxle1Left "Brake caliper lining clearance for left brake on trailer axle 1.

00 - Caliper lining clearance is adequate
01 - Caliper lining clearance is low
10 - Error
11 - Not available / not applicable";
CM_ SG_ 2566663422 TrctrBrkClprLnngClrnceAxle5Right "Brake caliper lining clearance for right brake on tractor axle 5.

00 - Caliper lining clearance is adequate
01 - Caliper lining clearance is low
10 - Error
11 - Not available / not applicable";
CM_ SG_ 2566663422 TrctrBrkClprLnngClranceAxle5Left "Brake caliper lining clearance for left brake on tractor axle 5.

00 - Caliper lining clearance is adequate
01 - Caliper lining clearance is low
10 - Error
11 - Not available / not applicable";
CM_ SG_ 2566663422 TrctrBrkClprLnngClrnceAxle4Right "Brake caliper lining clearance for right brake on tractor axle 4.

00 - Caliper lining clearance is adequate
01 - Caliper lining clearance is low
10 - Error
11 - Not available / not applicable";
CM_ SG_ 2566663422 TrctrBrkClprLnngClranceAxle4Left "Brake caliper lining clearance for right brake on tractor axle 4.

00 - Caliper lining clearance is adequate
01 - Caliper lining clearance is low
10 - Error
11 - Not available / not applicable";
CM_ SG_ 2566663422 TrctrBrkClprLnngClrnceAxle3Right "Brake caliper lining clearance for right brake on tractor axle 3.

00 - Caliper lining clearance is adequate
01 - Caliper lining clearance is low
10 - Error
11 - Not available / not applicable";
CM_ SG_ 2566663422 TrctrBrkClprLnngClranceAxle3Left "Brake caliper lining clearance for left brake on tractor axle 3.

00 - Caliper lining clearance is adequate
01 - Caliper lining clearance is low
10 - Error
11 - Not available / not applicable";
CM_ SG_ 2566663422 TrctrBrkClprLnngClrnceAxle2Right "Brake caliper lining clearance for right brake on tractor axle 2.

00 - Caliper lining clearance is adequate
01 - Caliper lining clearance is low
10 - Error
11 - Not available / not applicable";
CM_ SG_ 2566663422 TrctrBrkClprLnngClranceAxle2Left "Brake caliper lining clearance for left brake on tractor axle 2.

00 - Caliper lining clearance is adequate
01 - Caliper lining clearance is low
10 - Error
11 - Not available / not applicable";
CM_ SG_ 2566663422 TrctrBrkClprLnngClrnceAxle1Right "Brake caliper lining clearance for right brake on tractor axle 1.

00 - Caliper lining clearance is adequate
01 - Caliper lining clearance is low
10 - Error
11 - Not available / not applicable";
CM_ SG_ 2566663422 TrctrBrkClprLnngClranceAxle1Left "Brake caliper lining clearance for left brake on tractor axle 1.

00 - Caliper lining clearance is adequate
01 - Caliper lining clearance is low
10 - Error
11 - Not available / not applicable";
CM_ BO_ 2566663166 "Cruise Control / Vehicle Speed 4";
CM_ SG_ 2566663166 CruiseCtrlAdjustedMaxSpeed "Present maximum vehicle velocity at which cruise can be set. This parameter is expected to change during run-time due to functionality that could influence the behavior of the cruise control algorithm. This functionality may include, but is not ...";
CM_ SG_ 2566663166 AppliedVehicleSpeedLimit "The vehicle speed limit in effect.

See SPN 2595 for alternate resolution.

Note:  If a maximum vehicle speed limit is not selected, then the first byte of this parameter will be equal to 0xFB.";
CM_ BO_ 2566662910 "Contains parameters related to operator inducement.";
CM_ SG_ 2566662910 OprtrIndcmntTmTTrqueDerateLevel2 "This parameter provides the time until Operator Inducement Torque Derate Level 2 (SPN 7427) is activated.
When operator inducement is not active (SPN 5826 is 000), this parameter will be set to 0xFB00.  If this parameter decrements to 0, it will ...";
CM_ SG_ 2566662910 OprtrIndcementTorqueDerateLevel2 "The next torque derate that will be applied to the engine operation due to operator inducement after the torque derate specified in Operator Inducement Torque Derate Level 1 (SPN 7425) becomes active.
This parameter is a percentage of how much the ...";
CM_ SG_ 2566662910 OprtrIndcmntTmTTrqueDerateLevel1 "This parameter provides the time until Operator Inducement Torque Derate Level 1 (SPN 7425) is activated.
When operator inducement is not active (SPN 5826 is 000), this parameter will be set to 0xFB00.  If this parameter decrements to 0, it will ...";
CM_ SG_ 2566662910 OprtrIndcementTorqueDerateLevel1 "This is the first torque derate that will be applied to the engine operation due to operator inducement.  The torque derate indicated in this parameter will be applied when the value in Operator Inducement Time to Torque Derate Level 1 (SPN 7426) ...";
CM_ BO_ 2566662654 "Forward Lane Image message 3 for computing results outside the optical sensor (e.g., data fusion)";
CM_ SG_ 2566662654 LaneMarkQualityOnTheRightSide "The quality of the nearest lane mark on the right side of the vehicle.
000 = no lane marks detected
001 = low reliablity of detected lane marks
010 = good reliablity of detected lane marks
011 = perfect recognition of lane marks
100 - 101 = ...";
CM_ SG_ 2566662654 LaneMarkQualityOnTheLeftSide "The quality of the nearest lane mark on the left side of the vehicle.
000 = no lane marks detected
001 = low reliablity of detected lane marks
010 = good reliablity of detected lane marks
011 = perfect recognition of lane marks
100 - 101 = ...";
CM_ SG_ 2566662654 LaneDepartureAngleRight "Angle between right lane mark and vehicle driving direction. The angle is positive while vehicle is moving towards the lane marks, and negative if not. Measured values outside the limits are represented by signal value 251.
Parameter specific ...";
CM_ SG_ 2566662654 LaneDepartureAngleLeft "Angle between left lane mark and vehicle driving direction. The angle is positive while vehicle is moving towards the lane marks, and negative if not. Measured values outside the limits are represented by signal value 251.
Parameter specific values ...";
CM_ SG_ 2566662654 RoadCurvatureBasedOnLaneMarks "The road curvature parameter is based on lane marks as measured by the FLI.  It is the mean value of the road curvature of the lane marks on the left and right side of the lane. In case one of the lane mark is not recognized anymore, the value is ...";
CM_ SG_ 2566662654 RghtDstncTLnMrkFrmVehiclesMiddle "Distance between middle of the vehicle front and the inner/left edge of the nearest lane mark on the right side as measured from the Forward Lane Imager. The value represents the lane width at camera position. Measured values greater than 5 m ...";
CM_ SG_ 2566662654 LftDstncTLnMrkFromVehiclesMiddle "Distance between middle of the vehicle front and the inner/right edge of the nearest lane mark on the left side as measured from the Forward Lane Imager. The value represents the lane width at camera position. Measured values greater than 5 m ...";
CM_ BO_ 2566662142 "Sensor Information which measures temperature, concentration, and conductivity of the diesel exhaust fluid of the aftertreatment 1 system.";
CM_ SG_ 2566662142 AT1DieselExhaustFluidCtrl2Temp "Temperature of the diesel exhaust fluid at the aftertreatment 1 diesel exhaust fluid controller 2.";
CM_ SG_ 2566662142 AT1DieselExhaustFluidCtrl1Temp "Temperature of the diesel exhaust fluid at the aftertreatment 1 diesel exhaust fluid controller.
For controllers that have more exhaust emissions control functions than only diesel exhaust fluid control, see SPN 5486 - exhaust emission control ECU ...";
CM_ BO_ 2566661630 "Contains information on various tank levels";
CM_ SG_ 2566661630 AT1DieselExhaustFluidTankHeater2 "Percentage of heating applied to the second diesel exhaust fluid tank heater on aftertreatment 1. A value of 0% means no heating applied, a value of 100% means full heating applied. The diesel exhaust fluid tank heater warms the diesel exhaust fluid ...";
CM_ SG_ 2566661630 AT1DieselExhaustFluidTankTemp2 "The second temperature of aftertreatment 1 diesel exhaust fluid in the storage tank.";
CM_ SG_ 2566661630 AT1DieselExhaustFluidTankVolume2 "Second measurement of the ratio of volume of diesel exhaust fluid to the total volume of the diesel exhaust fluid storage container for aftertreatment system 1 (exhaust bank 1).  0% is empty and 100% is full.  See SPN 1761 and SPN 3517 for alternate ...";
CM_ BO_ 2566661374 "This message contains diesel exhaust fluid tank 1 information for aftertreatment system 2 (or bank 2).  The first tank for the aftertreatment sytem is primary reagent storage tank.";
CM_ SG_ 2566661374 AT2DieselExhaustFluidCtrl2Temp "Temperature of the diesel exhaust fluid at the aftertreatment 2 diesel exhaust fluid controller 2.";
CM_ SG_ 2566661374 AT2DieselExhaustFluidCtrlTemp "Temperature of the diesel exhaust fluid at the aftertreatment 2 diesel exhaust fluid controller.";
CM_ SG_ 2566661374 AT2DieselExhaustFluidTankHeater2 "Percentage of heating applied to the second diesel exhaust fluid tank heater on aftertreatment 2. A value of 0% means no heating applied, a value of 100% means full heating applied. The diesel exhaust fluid tank heater warms the diesel exhaust fluid ...";
CM_ SG_ 2566661374 AT2DieselExhaustFluidTankTemp2 "The second temperature of aftertreatment 2 diesel exhaust fluid in the storage tank.";
CM_ SG_ 2566661374 AT2DieselExhaustFluidTankVolume2 "Second measurement of the ratio of volume of diesel exhaust fluid to the total volume of the diesel exhaust fluid storage container for aftertreatment system 2 (exhaust bank 2).  0% is empty and 100% is full.  See SPN 4426 and SPN 4428 for alternate ...";
CM_ BO_ 2364598270 "This PGN contains timing offsets for cylinders 17-24.

These timing offsets are relative to the commanded engine timing advance (SPN 7355).";
CM_ SG_ 2364598270 EngCyl24TimingOffset "The ignition timing offset for Cylinder 24 from the engine timing advance (SPN 7355) as a command to the ignition control module. Positive values command an increasingly advanced timing.";
CM_ SG_ 2364598270 EngCyl23TimingOffset "The ignition timing offset for Cylinder 23 from the engine timing advance (SPN 7355) as a command to the ignition control module. Positive values command an increasingly advanced timing.";
CM_ SG_ 2364598270 EngCyl22TimingOffset "The ignition timing offset for Cylinder 22 from the engine timing advance (SPN 7355) as a command to the ignition control module. Positive values command an increasingly advanced timing.";
CM_ SG_ 2364598270 EngCyl21TimingOffset "The ignition timing offset for Cylinder 21 from the engine timing advance (SPN 7355) as a command to the ignition control module. Positive values command an increasingly advanced timing.";
CM_ SG_ 2364598270 EngCyl20TimingOffset "The ignition timing offset for Cylinder 20 from the engine timing advance (SPN 7355) as a command to the ignition control module. Positive values command an increasingly advanced timing.";
CM_ SG_ 2364598270 EngCyl19TimingOffset "The ignition timing offset for Cylinder 19 from the engine timing advance (SPN 7355) as a command to the ignition control module. Positive values command an increasingly advanced timing.";
CM_ SG_ 2364598270 EngCyl18TimingOffset "The ignition timing offset for Cylinder 18 from the engine timing advance (SPN 7355) as a command to the ignition control module. Positive values command an increasingly advanced timing.";
CM_ SG_ 2364598270 EngCyl17TimingOffset "The ignition timing offset for Cylinder 17 from the engine timing advance (SPN 7355) as a command to the ignition control module. Positive values command an increasingly advanced timing.";
BA_DEF_ SG_  "SigType" ENUM  "Default","Range","RangeSigned","ASCII","Discrete","Control","ReferencePGN","DTC","StringDelimiter","StringLength","StringLengthControl","MessageCounter","MessageChecksum";
BA_DEF_ SG_  "GenSigStartValue" INT 0 10000;
BA_DEF_ SG_  "GenSigSendType" ENUM  "Cyclic","OnWrite","OnWriteWithRepetition","OnChange","OnChangeWithRepetition","IfActive","IfActiveWithRepetition","NoSigSendType";
BA_DEF_ SG_  "GenSigILSupport" ENUM  "No","Yes";
BA_DEF_ SG_  "GenSigEVName" STRING ;
BA_DEF_ SG_  "SPN" INT 0 524287;
BA_DEF_ BO_  "TpJ1939VarDlc" ENUM  "No","Yes";
BA_DEF_ BO_  "GenMsgStartDelayTime" INT 0 100000;
BA_DEF_ BO_  "GenMsgILSupport" ENUM  "No","Yes";
BA_DEF_ BO_  "GenMsgDelayTime" INT 0 1000;
BA_DEF_ BO_  "GenMsgRequestable" INT 0 1;
BA_DEF_ BO_  "GenMsgSendType" ENUM  "cyclic","NotUsed","NotUsed","NotUsed","NotUsed","NotUsed","NotUsed","IfActive","noMsgSendType";
BA_DEF_ BO_  "VFrameFormat" ENUM  "StandardCAN","ExtendedCAN","reserved","J1939PG";
BA_DEF_ BO_  "GenMsgCycleTime" INT 0 3600000;
BA_DEF_ SG_  "SystemSignalLongSymbol" STRING ;
BA_DEF_DEF_  "SigType" "Default";
BA_DEF_DEF_  "GenSigStartValue" 0;
BA_DEF_DEF_  "GenSigSendType" "NoSigSendType";
BA_DEF_DEF_  "GenSigILSupport" "Yes";
BA_DEF_DEF_  "GenSigEVName" "Env@Nodename_@Signame";
BA_DEF_DEF_  "SPN" 0;
BA_DEF_DEF_  "TpJ1939VarDlc" "No";
BA_DEF_DEF_  "GenMsgStartDelayTime" 0;
BA_DEF_DEF_  "GenMsgILSupport" "Yes";
BA_DEF_DEF_  "GenMsgDelayTime" 0;
BA_DEF_DEF_  "GenMsgRequestable" 1;
BA_DEF_DEF_  "GenMsgSendType" "noMsgSendType";
BA_DEF_DEF_  "VFrameFormat" "J1939PG";
BA_DEF_DEF_  "GenMsgCycleTime" 0;
BA_DEF_DEF_  "SystemSignalLongSymbol" "";
BA_ "GenMsgCycleTime" BO_ 2566838014 1000;
BA_ "GenMsgSendType" BO_ 2566838014 0;
BA_ "GenMsgCycleTime" BO_ 2566756350 1000;
BA_ "GenMsgSendType" BO_ 2566756350 0;
BA_ "GenMsgCycleTime" BO_ 2566756094 1000;
BA_ "GenMsgSendType" BO_ 2566756094 0;
BA_ "GenMsgCycleTime" BO_ 2566687998 200;
BA_ "GenMsgSendType" BO_ 2566687998 0;
BA_ "GenMsgCycleTime" BO_ 2566687742 200;
BA_ "GenMsgSendType" BO_ 2566687742 0;
BA_ "GenMsgCycleTime" BO_ 2365348350 500;
BA_ "GenMsgSendType" BO_ 2365348350 0;
BA_ "GenMsgDelayTime" BO_ 2365348350 50;
BA_ "GenMsgCycleTime" BO_ 2566674686 1000;
BA_ "GenMsgSendType" BO_ 2566674686 0;
BA_ "GenMsgCycleTime" BO_ 2566674430 10000;
BA_ "GenMsgSendType" BO_ 2566674430 0;
BA_ "GenMsgDelayTime" BO_ 2566674430 1000;
BA_ "GenMsgCycleTime" BO_ 2566674174 10000;
BA_ "GenMsgSendType" BO_ 2566674174 0;
BA_ "GenMsgDelayTime" BO_ 2566674174 1000;
BA_ "GenMsgCycleTime" BO_ 2566673406 500;
BA_ "GenMsgSendType" BO_ 2566673406 0;
BA_ "GenMsgCycleTime" BO_ 2633782014 10000;
BA_ "GenMsgSendType" BO_ 2633782014 0;
BA_ "GenMsgDelayTime" BO_ 2633782014 1000;
BA_ "GenMsgCycleTime" BO_ 2365346302 100;
BA_ "GenMsgSendType" BO_ 2365346302 0;
BA_ "GenMsgCycleTime" BO_ 2566672638 1000;
BA_ "GenMsgSendType" BO_ 2566672638 0;
BA_ "GenMsgCycleTime" BO_ 2566672382 1000;
BA_ "GenMsgSendType" BO_ 2566672382 0;
BA_ "GenMsgCycleTime" BO_ 2566672126 500;
BA_ "GenMsgSendType" BO_ 2566672126 0;
BA_ "GenMsgCycleTime" BO_ 2566671870 500;
BA_ "GenMsgSendType" BO_ 2566671870 0;
BA_ "GenMsgCycleTime" BO_ 2566671102 1000;
BA_ "GenMsgSendType" BO_ 2566671102 0;
BA_ "GenMsgDelayTime" BO_ 2566671102 100;
BA_ "TpJ1939VarDlc" BO_ 2566670846 1;
BA_ "TpJ1939VarDlc" BO_ 2566670590 1;
BA_ "TpJ1939VarDlc" BO_ 2566670078 1;
BA_ "TpJ1939VarDlc" BO_ 2566669822 1;
BA_ "GenMsgCycleTime" BO_ 2566669054 10000;
BA_ "GenMsgSendType" BO_ 2566669054 0;
BA_ "GenMsgCycleTime" BO_ 2566668798 500;
BA_ "GenMsgSendType" BO_ 2566668798 0;
BA_ "GenMsgCycleTime" BO_ 2566668542 500;
BA_ "GenMsgSendType" BO_ 2566668542 0;
BA_ "GenMsgCycleTime" BO_ 2566668030 1000;
BA_ "GenMsgSendType" BO_ 2566668030 0;
BA_ "GenMsgCycleTime" BO_ 2566667774 1000;
BA_ "GenMsgSendType" BO_ 2566667774 0;
BA_ "GenMsgCycleTime" BO_ 2566667518 1000;
BA_ "GenMsgSendType" BO_ 2566667518 0;
BA_ "GenMsgCycleTime" BO_ 2566667262 1000;
BA_ "GenMsgSendType" BO_ 2566667262 0;
BA_ "GenMsgCycleTime" BO_ 2499558142 500;
BA_ "GenMsgSendType" BO_ 2499558142 0;
BA_ "GenMsgCycleTime" BO_ 2499557886 500;
BA_ "GenMsgSendType" BO_ 2499557886 0;
BA_ "GenMsgCycleTime" BO_ 2499557630 500;
BA_ "GenMsgSendType" BO_ 2499557630 0;
BA_ "GenMsgCycleTime" BO_ 2499557374 500;
BA_ "GenMsgSendType" BO_ 2499557374 0;
BA_ "GenMsgCycleTime" BO_ 2499557118 500;
BA_ "GenMsgSendType" BO_ 2499557118 0;
BA_ "GenMsgCycleTime" BO_ 2566665726 500;
BA_ "GenMsgSendType" BO_ 2566665726 0;
BA_ "GenMsgCycleTime" BO_ 2499556606 500;
BA_ "GenMsgSendType" BO_ 2499556606 0;
BA_ "GenMsgCycleTime" BO_ 2499556350 500;
BA_ "GenMsgSendType" BO_ 2499556350 0;
BA_ "GenMsgCycleTime" BO_ 2499556094 250;
BA_ "GenMsgSendType" BO_ 2499556094 0;
BA_ "GenMsgCycleTime" BO_ 2566664702 1000;
BA_ "GenMsgSendType" BO_ 2566664702 0;
BA_ "GenMsgDelayTime" BO_ 2566664702 100;
BA_ "GenMsgCycleTime" BO_ 2633773054 1000;
BA_ "GenMsgSendType" BO_ 2633773054 0;
BA_ "GenMsgCycleTime" BO_ 2566663934 500;
BA_ "GenMsgSendType" BO_ 2566663934 0;
BA_ "GenMsgCycleTime" BO_ 2566663678 500;
BA_ "GenMsgSendType" BO_ 2566663678 0;
BA_ "GenMsgCycleTime" BO_ 2566663422 1000;
BA_ "GenMsgSendType" BO_ 2566663422 0;
BA_ "GenMsgCycleTime" BO_ 2566663166 1000;
BA_ "GenMsgSendType" BO_ 2566663166 0;
BA_ "GenMsgCycleTime" BO_ 2566662910 10000;
BA_ "GenMsgSendType" BO_ 2566662910 0;
BA_ "GenMsgCycleTime" BO_ 2566662654 100;
BA_ "GenMsgSendType" BO_ 2566662654 0;
BA_ "GenMsgCycleTime" BO_ 2566662142 1000;
BA_ "GenMsgSendType" BO_ 2566662142 0;
BA_ "GenMsgCycleTime" BO_ 2566661630 1000;
BA_ "GenMsgSendType" BO_ 2566661630 0;
BA_ "GenMsgCycleTime" BO_ 2566661374 1000;
BA_ "GenMsgSendType" BO_ 2566661374 0;
BA_ "SPN" SG_ 2364473170 ArbitraryAddressCapable 2844;
BA_ "SPN" SG_ 2364473170 IndustryGroup 2846;
BA_ "SPN" SG_ 2364473170 VehicleSystemInstance 2843;
BA_ "SPN" SG_ 2364473170 Function 2841;
BA_ "SPN" SG_ 2364473170 FunctionInstance 2839;
BA_ "SPN" SG_ 2364473170 ECUInstance 2840;
BA_ "SPN" SG_ 2364473170 ManufacturerCode 2838;
BA_ "SigType" SG_ 2364473170 ManufacturerCode 1;
BA_ "SPN" SG_ 2364473170 IdentityNumber 2837;
BA_ "SPN" SG_ 2364473169 ArbitraryAddressCapable 2844;
BA_ "SPN" SG_ 2364473169 IndustryGroup 2846;
BA_ "SPN" SG_ 2364473169 VehicleSystemInstance 2843;
BA_ "SPN" SG_ 2364473169 Function 2841;
BA_ "SPN" SG_ 2364473169 FunctionInstance 2839;
BA_ "SPN" SG_ 2364473169 ECUInstance 2840;
BA_ "SPN" SG_ 2364473169 ManufacturerCode 2838;
BA_ "SigType" SG_ 2364473169 ManufacturerCode 1;
BA_ "SPN" SG_ 2364473169 IdentityNumber 2837;
BA_ "SPN" SG_ 2566838014 HybrdSystmCstngRgnrtvBrkngLvlSlc 7556;
BA_ "SigType" SG_ 2566838014 HybrdSystmCstngRgnrtvBrkngLvlSlc 1;
BA_ "SPN" SG_ 2566838014 HybrdSystmBrkPdlRgnrtvBrkngDsblS 7553;
BA_ "SigType" SG_ 2566838014 HybrdSystmBrkPdlRgnrtvBrkngDsblS 4;
BA_ "SPN" SG_ 2566838014 HybrdSystmRgnrtvBrkngDsbleSwitch 7552;
BA_ "SigType" SG_ 2566838014 HybrdSystmRgnrtvBrkngDsbleSwitch 4;
BA_ "SPN" SG_ 2566838014 HybrdSystmOffBrdChrgrCnnctnSttus 7551;
BA_ "SigType" SG_ 2566838014 HybrdSystmOffBrdChrgrCnnctnSttus 4;
BA_ "SPN" SG_ 2566838014 HybrdSystmPwrElctrncsClntLvlSwtc 7550;
BA_ "SigType" SG_ 2566838014 HybrdSystmPwrElctrncsClntLvlSwtc 4;
BA_ "SPN" SG_ 2566838014 HybrdSystmPrplsnClantLevelSwitch 7549;
BA_ "SigType" SG_ 2566838014 HybrdSystmPrplsnClantLevelSwitch 4;
BA_ "SPN" SG_ 2566838014 HybrdSystmPrtctionOverrideSwitch 7548;
BA_ "SigType" SG_ 2566838014 HybrdSystmPrtctionOverrideSwitch 4;
BA_ "SPN" SG_ 2566761726 EngIdleFuelFlowRateThreshold 2778;
BA_ "SigType" SG_ 2566761726 EngIdleFuelFlowRateThreshold 1;
BA_ "SPN" SG_ 2566761726 NmbrOfFlCnsmptnMntrngTransducers 2777;
BA_ "SigType" SG_ 2566761726 NmbrOfFlCnsmptnMntrngTransducers 1;
BA_ "SPN" SG_ 2566756350 EngFuelReturnTemp 2776;
BA_ "SigType" SG_ 2566756350 EngFuelReturnTemp 1;
BA_ "SPN" SG_ 2566756350 EngFuelSupplyTemp 2775;
BA_ "SigType" SG_ 2566756350 EngFuelSupplyTemp 1;
BA_ "SPN" SG_ 2566756094 EngFuelReturnFlowRate 2774;
BA_ "SigType" SG_ 2566756094 EngFuelReturnFlowRate 1;
BA_ "SPN" SG_ 2566756094 EngFuelSupplyFlowRate 2773;
BA_ "SigType" SG_ 2566756094 EngFuelSupplyFlowRate 1;
BA_ "SPN" SG_ 2566687998 AT1PrtcltSnsrTmBtwnRegenerations 6776;
BA_ "SigType" SG_ 2566687998 AT1PrtcltSnsrTmBtwnRegenerations 1;
BA_ "SPN" SG_ 2566687998 AT1PrtcltSnsrActvAccmulationTime 6775;
BA_ "SigType" SG_ 2566687998 AT1PrtcltSnsrActvAccmulationTime 1;
BA_ "SPN" SG_ 2566687998 AT1PrtcltSensorRegenerationState 6774;
BA_ "SPN" SG_ 2566687998 AT1PrtcltSnsorRegenerationStatus 6773;
BA_ "SigType" SG_ 2566687998 AT1PrtcltSnsorRegenerationStatus 5;
BA_ "SPN" SG_ 2566687998 AT1ParticulateSensorHeaterState 6772;
BA_ "SigType" SG_ 2566687998 AT1ParticulateSensorHeaterState 5;
BA_ "SPN" SG_ 2566687998 AT1ParticulateSensorResistance 6771;
BA_ "SigType" SG_ 2566687998 AT1ParticulateSensorResistance 1;
BA_ "SPN" SG_ 2566687742 AT1PrtclteSensorHeaterResistance 7070;
BA_ "SigType" SG_ 2566687742 AT1PrtclteSensorHeaterResistance 1;
BA_ "SPN" SG_ 2566687742 AT1PrticulateSensorMaxResistance 6781;
BA_ "SigType" SG_ 2566687742 AT1PrticulateSensorMaxResistance 1;
BA_ "SPN" SG_ 2566687742 AT1ParticulateSensorTemp 6780;
BA_ "SigType" SG_ 2566687742 AT1ParticulateSensorTemp 1;
BA_ "SPN" SG_ 2566687742 AT1PrtcltSnsrRgnrtionFailedCount 6779;
BA_ "SigType" SG_ 2566687742 AT1PrtcltSnsrRgnrtionFailedCount 1;
BA_ "SPN" SG_ 2566687742 AT1ParticulateSensorPowerSupply 6778;
BA_ "SigType" SG_ 2566687742 AT1ParticulateSensorPowerSupply 4;
BA_ "SPN" SG_ 2566687742 AT1PrtclateSensorDetectionStatus 6777;
BA_ "SPN" SG_ 2365348350 EngLoadShareStatus 6794;
BA_ "SPN" SG_ 2365348350 EngUnloadStatus 6793;
BA_ "SigType" SG_ 2365348350 EngUnloadStatus 4;
BA_ "SPN" SG_ 2566674686 EngTurbo4LubeOilPress 6813;
BA_ "SigType" SG_ 2566674686 EngTurbo4LubeOilPress 1;
BA_ "SPN" SG_ 2566674686 EngTurbo3LubeOilPress 6812;
BA_ "SigType" SG_ 2566674686 EngTurbo3LubeOilPress 1;
BA_ "SPN" SG_ 2566674686 EngTurbo2LubeOilPress 6811;
BA_ "SigType" SG_ 2566674686 EngTurbo2LubeOilPress 1;
BA_ "SPN" SG_ 2566674430 DslExhstFldQalityMalfunctionTime 6818;
BA_ "SigType" SG_ 2566674430 DslExhstFldQalityMalfunctionTime 1;
BA_ "SPN" SG_ 2566674430 DieselExhaustFluidTank1EmptyTime 6817;
BA_ "SigType" SG_ 2566674430 DieselExhaustFluidTank1EmptyTime 1;
BA_ "SPN" SG_ 2566674174 SCROperatorInducementTotalTime 7095;
BA_ "SigType" SG_ 2566674174 SCROperatorInducementTotalTime 1;
BA_ "SPN" SG_ 2566674174 ATSCRMalfunctionTime 6819;
BA_ "SigType" SG_ 2566674174 ATSCRMalfunctionTime 1;
BA_ "SPN" SG_ 2566673406 GasLeakageDetection3Press 6839;
BA_ "SigType" SG_ 2566673406 GasLeakageDetection3Press 1;
BA_ "SPN" SG_ 2566673406 GasLeakageDetection2Press 6838;
BA_ "SigType" SG_ 2566673406 GasLeakageDetection2Press 1;
BA_ "SPN" SG_ 2566673406 GasLeakageDetection1Press 6837;
BA_ "SigType" SG_ 2566673406 GasLeakageDetection1Press 1;
BA_ "SPN" SG_ 2566673406 GasFuelLeakage3Concentration 6836;
BA_ "SigType" SG_ 2566673406 GasFuelLeakage3Concentration 1;
BA_ "SPN" SG_ 2566673406 GasFuelLeakage2Concentration 6835;
BA_ "SigType" SG_ 2566673406 GasFuelLeakage2Concentration 1;
BA_ "SPN" SG_ 2566673406 GasFuelLeakage1Concentration 6834;
BA_ "SigType" SG_ 2566673406 GasFuelLeakage1Concentration 1;
BA_ "SPN" SG_ 2633782014 NetBinWeight 6841;
BA_ "SigType" SG_ 2633782014 NetBinWeight 1;
BA_ "SPN" SG_ 2633782014 BinLiftCount 6840;
BA_ "SigType" SG_ 2633782014 BinLiftCount 1;
BA_ "SPN" SG_ 2633782014 BinWeighingErrorStatus 6842;
BA_ "SPN" SG_ 2633782014 BinInstance 6845;
BA_ "SPN" SG_ 2365346302 LiftAxle2Status 6844;
BA_ "SPN" SG_ 2365346302 LiftAxle1Status 6843;
BA_ "SPN" SG_ 2566672638 DeliveredPayloadConfidence 6850;
BA_ "SigType" SG_ 2566672638 DeliveredPayloadConfidence 1;
BA_ "SPN" SG_ 2566672638 DeliveredPayloadWeight 6849;
BA_ "SPN" SG_ 2566672638 HaulModeStatus 6848;
BA_ "SPN" SG_ 2566672638 HaulCycleCount 6847;
BA_ "SigType" SG_ 2566672638 HaulCycleCount 1;
BA_ "SPN" SG_ 2566672382 PayloadWeightSensor8Status 6862;
BA_ "SigType" SG_ 2566672382 PayloadWeightSensor8Status 5;
BA_ "SPN" SG_ 2566672382 PayloadWeightSensor7Status 6861;
BA_ "SigType" SG_ 2566672382 PayloadWeightSensor7Status 5;
BA_ "SPN" SG_ 2566672382 PayloadWeightSensor6Status 6860;
BA_ "SigType" SG_ 2566672382 PayloadWeightSensor6Status 5;
BA_ "SPN" SG_ 2566672382 PayloadWeightSensor5Status 6859;
BA_ "SigType" SG_ 2566672382 PayloadWeightSensor5Status 5;
BA_ "SPN" SG_ 2566672382 PayloadWeightSensor4Status 6858;
BA_ "SigType" SG_ 2566672382 PayloadWeightSensor4Status 5;
BA_ "SPN" SG_ 2566672382 PayloadWeightSensor3Status 6857;
BA_ "SigType" SG_ 2566672382 PayloadWeightSensor3Status 5;
BA_ "SPN" SG_ 2566672382 PayloadWeightSensor2Status 6856;
BA_ "SigType" SG_ 2566672382 PayloadWeightSensor2Status 5;
BA_ "SPN" SG_ 2566672382 PayloadWeightSensor1Status 6855;
BA_ "SigType" SG_ 2566672382 PayloadWeightSensor1Status 5;
BA_ "SPN" SG_ 2566672126 AT1DieselExhaustFluidDoser2Temp 7460;
BA_ "SigType" SG_ 2566672126 AT1DieselExhaustFluidDoser2Temp 1;
BA_ "SPN" SG_ 2566672126 AT1DslExhaustFluidDoser2AbsPress 7459;
BA_ "SigType" SG_ 2566672126 AT1DslExhaustFluidDoser2AbsPress 1;
BA_ "SPN" SG_ 2566672126 AT1DieselExhaustFluidDosingPress 6875;
BA_ "SigType" SG_ 2566672126 AT1DieselExhaustFluidDosingPress 1;
BA_ "SPN" SG_ 2566671870 AT2DieselExhaustFluidDosingPress 6876;
BA_ "SigType" SG_ 2566671870 AT2DieselExhaustFluidDosingPress 1;
BA_ "SPN" SG_ 2566671614 TtlNmbrOfSCROprtrIndcmntOvrrdEvn 6880;
BA_ "SigType" SG_ 2566671614 TtlNmbrOfSCROprtrIndcmntOvrrdEvn 1;
BA_ "SPN" SG_ 2566671614 NmbrOfSCROprtrIndcmntOvrrdEvntsR 6879;
BA_ "SigType" SG_ 2566671614 NmbrOfSCROprtrIndcmntOvrrdEvntsR 1;
BA_ "SPN" SG_ 2566671614 SCROprtrIndcmntOvrrdTmeRemaining 6878;
BA_ "SigType" SG_ 2566671614 SCROprtrIndcmntOvrrdTmeRemaining 1;
BA_ "SPN" SG_ 2566671614 SCROprtrInducementOverrideEnable 6877;
BA_ "SigType" SG_ 2566671614 SCROprtrInducementOverrideEnable 5;
BA_ "SPN" SG_ 2566671358 CylFuelRate 7333;
BA_ "SigType" SG_ 2566671358 CylFuelRate 1;
BA_ "SPN" SG_ 2566671358 EngExhaustFlowRate 6895;
BA_ "SigType" SG_ 2566671358 EngExhaustFlowRate 1;
BA_ "SPN" SG_ 2566671358 VehicleFuelRate 6894;
BA_ "SigType" SG_ 2566671358 VehicleFuelRate 1;
BA_ "SPN" SG_ 2566671358 PEMSEngFuelMassFlowRate 6893;
BA_ "SigType" SG_ 2566671358 PEMSEngFuelMassFlowRate 1;
BA_ "SPN" SG_ 2566671102 SCRSystemCleaningForcedStatus 6934;
BA_ "SPN" SG_ 2566671102 SCRSystmClnngAtmtcIntationConfig 6933;
BA_ "SigType" SG_ 2566671102 SCRSystmClnngAtmtcIntationConfig 5;
BA_ "SPN" SG_ 2566671102 SCRSystmClnngInhbtdDTVhclSpdBlwA 6932;
BA_ "SigType" SG_ 2566671102 SCRSystmClnngInhbtdDTVhclSpdBlwA 5;
BA_ "SPN" SG_ 2566671102 SCRSystmClnngInhbtdDTEngNtWrmdUp 6931;
BA_ "SigType" SG_ 2566671102 SCRSystmClnngInhbtdDTEngNtWrmdUp 5;
BA_ "SPN" SG_ 2566671102 SCRSystmClnngInhbtdDTPrmnntSystm 6930;
BA_ "SigType" SG_ 2566671102 SCRSystmClnngInhbtdDTPrmnntSystm 5;
BA_ "SPN" SG_ 2566671102 SCRSystmClnngInhbtdDTTmprrySystm 6929;
BA_ "SigType" SG_ 2566671102 SCRSystmClnngInhbtdDTTmprrySystm 5;
BA_ "SPN" SG_ 2566671102 SCRSystmClnngInhbtdDTSystmTmeout 6928;
BA_ "SigType" SG_ 2566671102 SCRSystmClnngInhbtdDTSystmTmeout 5;
BA_ "SPN" SG_ 2566671102 SCRSystmClnngInhbtdDTSystmFltAct 6927;
BA_ "SigType" SG_ 2566671102 SCRSystmClnngInhbtdDTSystmFltAct 5;
BA_ "SPN" SG_ 2566671102 SCRSystmClnngInhbtdDTLwExhstTemp 6926;
BA_ "SigType" SG_ 2566671102 SCRSystmClnngInhbtdDTLwExhstTemp 5;
BA_ "SPN" SG_ 2566671102 SCRSystmClnngInhbtdDTPrkngBrkNtS 6925;
BA_ "SigType" SG_ 2566671102 SCRSystmClnngInhbtdDTPrkngBrkNtS 5;
BA_ "SPN" SG_ 2566671102 SCRSystmClnngInhbtdDTVhclSpdAbvA 6924;
BA_ "SigType" SG_ 2566671102 SCRSystmClnngInhbtdDTVhclSpdAbvA 5;
BA_ "SPN" SG_ 2566671102 SCRSystmClnngInhbtdDTOtOfNeutral 6923;
BA_ "SigType" SG_ 2566671102 SCRSystmClnngInhbtdDTOtOfNeutral 5;
BA_ "SPN" SG_ 2566671102 SCRSystmClnngInhbtdDTAcclPdlOffI 6922;
BA_ "SigType" SG_ 2566671102 SCRSystmClnngInhbtdDTAcclPdlOffI 5;
BA_ "SPN" SG_ 2566671102 SCRSystmClnngInhbtdDeToPTOActive 6921;
BA_ "SigType" SG_ 2566671102 SCRSystmClnngInhbtdDeToPTOActive 5;
BA_ "SPN" SG_ 2566671102 SCRSystmClnngInhbtdDTSrvcBrkActv 6920;
BA_ "SigType" SG_ 2566671102 SCRSystmClnngInhbtdDTSrvcBrkActv 5;
BA_ "SPN" SG_ 2566671102 SCRSystmClnngInhbtdDTCltchDsnggd 6919;
BA_ "SigType" SG_ 2566671102 SCRSystmClnngInhbtdDTCltchDsnggd 5;
BA_ "SPN" SG_ 2566671102 SCRSystmClnngInhbtdDTInhbtSwitch 6918;
BA_ "SigType" SG_ 2566671102 SCRSystmClnngInhbtdDTInhbtSwitch 5;
BA_ "SPN" SG_ 2566671102 SCRSystemCleaningInhibitedStatus 6917;
BA_ "SigType" SG_ 2566671102 SCRSystemCleaningInhibitedStatus 5;
BA_ "SPN" SG_ 2566671102 SCRSystemCleaningStatus 6916;
BA_ "SigType" SG_ 2566671102 SCRSystemCleaningStatus 5;
BA_ "SPN" SG_ 2566671102 SCRSystemCleaningLampCmd 6915;
BA_ "SPN" SG_ 2566670846 AT1SCRSystmAvrgDstncBtwnSystmCln 6940;
BA_ "SigType" SG_ 2566670846 AT1SCRSystmAvrgDstncBtwnSystmCln 1;
BA_ "SPN" SG_ 2566670846 AT1SCRSystmAvrgTmBtwnSystmClnngE 6939;
BA_ "SigType" SG_ 2566670846 AT1SCRSystmAvrgTmBtwnSystmClnngE 1;
BA_ "SPN" SG_ 2566670846 AT1SCRSystmTtlNmbrOfSystmClnngMn 6938;
BA_ "SigType" SG_ 2566670846 AT1SCRSystmTtlNmbrOfSystmClnngMn 1;
BA_ "SPN" SG_ 2566670846 AT1SCRSystmTtlNmbrOfSystmClnngIn 6937;
BA_ "SigType" SG_ 2566670846 AT1SCRSystmTtlNmbrOfSystmClnngIn 1;
BA_ "SPN" SG_ 2566670846 AT1SCRSystmTtlNmbrOfSystmClnngEv 6936;
BA_ "SigType" SG_ 2566670846 AT1SCRSystmTtlNmbrOfSystmClnngEv 1;
BA_ "SPN" SG_ 2566670846 AT1SCRSystemTotalCleaningTime 6935;
BA_ "SigType" SG_ 2566670846 AT1SCRSystemTotalCleaningTime 1;
BA_ "SPN" SG_ 2566670590 AT2SCRSystmAvrgDstncBtwnSystmCln 6947;
BA_ "SigType" SG_ 2566670590 AT2SCRSystmAvrgDstncBtwnSystmCln 1;
BA_ "SPN" SG_ 2566670590 AT2SCRSystmAvrgTmBtwnSystmClnngE 6946;
BA_ "SigType" SG_ 2566670590 AT2SCRSystmAvrgTmBtwnSystmClnngE 1;
BA_ "SPN" SG_ 2566670590 AT2SCRSystmTtlNmbrOfSystmClnngMn 6945;
BA_ "SigType" SG_ 2566670590 AT2SCRSystmTtlNmbrOfSystmClnngMn 1;
BA_ "SPN" SG_ 2566670590 AT2SCRSystmTtlNmbrOfSystmClnngIn 6944;
BA_ "SigType" SG_ 2566670590 AT2SCRSystmTtlNmbrOfSystmClnngIn 1;
BA_ "SPN" SG_ 2566670590 AT2SCRSystmTtlNmbrOfSystmClnngEv 6943;
BA_ "SigType" SG_ 2566670590 AT2SCRSystmTtlNmbrOfSystmClnngEv 1;
BA_ "SPN" SG_ 2566670590 AT2SCRSystmTtlSystemCleaningTime 6942;
BA_ "SigType" SG_ 2566670590 AT2SCRSystmTtlSystemCleaningTime 1;
BA_ "SPN" SG_ 2566670334 Axle12MonitoredTireCount 6962;
BA_ "SPN" SG_ 2566670334 Axle11MonitoredTireCount 6961;
BA_ "SPN" SG_ 2566670334 Axle10MonitoredTireCount 6960;
BA_ "SPN" SG_ 2566670334 Axle9MonitoredTireCount 6959;
BA_ "SPN" SG_ 2566670334 Axle8MonitoredTireCount 6958;
BA_ "SPN" SG_ 2566670334 Axle7MonitoredTireCount 6957;
BA_ "SPN" SG_ 2566670334 Axle6MonitoredTireCount 6956;
BA_ "SPN" SG_ 2566670334 Axle5MonitoredTireCount 6955;
BA_ "SPN" SG_ 2566670334 Axle4MonitoredTireCount 6954;
BA_ "SPN" SG_ 2566670334 Axle3MonitoredTireCount 6953;
BA_ "SPN" SG_ 2566670334 Axle2MonitoredTireCount 6952;
BA_ "SPN" SG_ 2566670334 Axle1MonitoredTireCount 6951;
BA_ "SPN" SG_ 2566670334 NumberOfTiresOnTheVehicle 6950;
BA_ "SigType" SG_ 2566670334 NumberOfTiresOnTheVehicle 1;
BA_ "SPN" SG_ 2566670334 NumberOfAxlesOnTheVehicle 6949;
BA_ "SPN" SG_ 2566670078 TireSensorIdentificationNumber 6966;
BA_ "SigType" SG_ 2566670078 TireSensorIdentificationNumber 8;
BA_ "SPN" SG_ 2566670078 TireSensorLocation 6965;
BA_ "SPN" SG_ 2566670078 TireSensorTireNumber 6964;
BA_ "SigType" SG_ 2566670078 TireSensorTireNumber 1;
BA_ "SPN" SG_ 2566670078 NumberOfTireSensors 6963;
BA_ "SigType" SG_ 2566670078 NumberOfTireSensors 1;
BA_ "SPN" SG_ 2566669822 TrWrelessSignalStrengthIndicator 6972;
BA_ "SigType" SG_ 2566669822 TrWrelessSignalStrengthIndicator 1;
BA_ "SPN" SG_ 2566669822 TireLocation 6971;
BA_ "SPN" SG_ 2566669822 TireSensorNumber 6970;
BA_ "SigType" SG_ 2566669822 TireSensorNumber 1;
BA_ "SPN" SG_ 2566669822 TtalNumberOfTireSensorsMonitored 6969;
BA_ "SigType" SG_ 2566669822 TtalNumberOfTireSensorsMonitored 1;
BA_ "SPN" SG_ 2566669822 AntennaNumber 6968;
BA_ "SigType" SG_ 2566669822 AntennaNumber 1;
BA_ "SPN" SG_ 2566669822 TotalNumberOfAntennasUsed 6967;
BA_ "SigType" SG_ 2566669822 TotalNumberOfAntennasUsed 1;
BA_ "SPN" SG_ 2566669310 OverTemp 6984;
BA_ "SigType" SG_ 2566669310 OverTemp 1;
BA_ "SPN" SG_ 2566669310 OverPressPercentageThreshold 6983;
BA_ "SigType" SG_ 2566669310 OverPressPercentageThreshold 1;
BA_ "SPN" SG_ 2566669310 ExtrmUndrPrssPercentageThreshold 6982;
BA_ "SigType" SG_ 2566669310 ExtrmUndrPrssPercentageThreshold 1;
BA_ "SPN" SG_ 2566669310 UnderPressPercentageThreshold 6981;
BA_ "SigType" SG_ 2566669310 UnderPressPercentageThreshold 1;
BA_ "SPN" SG_ 2566669310 ColdInflationPress 6980;
BA_ "SigType" SG_ 2566669310 ColdInflationPress 1;
BA_ "SPN" SG_ 2566669310 TireLocation 6979;
BA_ "SPN" SG_ 2566669054 RequiredTirePress 6989;
BA_ "SigType" SG_ 2566669054 RequiredTirePress 1;
BA_ "SPN" SG_ 2566669054 TirePress 6988;
BA_ "SigType" SG_ 2566669054 TirePress 1;
BA_ "SPN" SG_ 2566669054 TireLocation 6987;
BA_ "SPN" SG_ 2566668798 EngFl2InjctorMeteringRail1Press2 7513;
BA_ "SigType" SG_ 2566668798 EngFl2InjctorMeteringRail1Press2 1;
BA_ "SPN" SG_ 2566668798 EngFel2InjectorMeteringRail2Temp 7024;
BA_ "SigType" SG_ 2566668798 EngFel2InjectorMeteringRail2Temp 1;
BA_ "SPN" SG_ 2566668798 EngFel2InjectorMeteringRail1Temp 7023;
BA_ "SigType" SG_ 2566668798 EngFel2InjectorMeteringRail1Temp 1;
BA_ "SPN" SG_ 2566668798 EngFl2InjectorMeteringRail2Press 7022;
BA_ "SigType" SG_ 2566668798 EngFl2InjectorMeteringRail2Press 1;
BA_ "SPN" SG_ 2566668798 EngFl2InjectorMeteringRail1Press 7021;
BA_ "SigType" SG_ 2566668798 EngFl2InjectorMeteringRail1Press 1;
BA_ "SPN" SG_ 2566668542 EngFuel2PumpHydPress 7019;
BA_ "SigType" SG_ 2566668542 EngFuel2PumpHydPress 1;
BA_ "SPN" SG_ 2566668542 EngFuel2PumpHydDirectionalValve 7018;
BA_ "SigType" SG_ 2566668542 EngFuel2PumpHydDirectionalValve 1;
BA_ "SPN" SG_ 2566668542 EngFuel2PumpHydSwashPlateAngle 7017;
BA_ "SigType" SG_ 2566668542 EngFuel2PumpHydSwashPlateAngle 1;
BA_ "SPN" SG_ 2566668542 EngFuel2PumpHydFlowCtrlValve 7016;
BA_ "SigType" SG_ 2566668542 EngFuel2PumpHydFlowCtrlValve 1;
BA_ "SPN" SG_ 2566668286 EngStagedTurboSolenoidStatus 7025;
BA_ "SigType" SG_ 2566668286 EngStagedTurboSolenoidStatus 1;
BA_ "SPN" SG_ 2566668030 HtExchngerDebrisPurgeApproaching 7036;
BA_ "SigType" SG_ 2566668030 HtExchngerDebrisPurgeApproaching 5;
BA_ "SPN" SG_ 2566668030 HeatExchangerDebrisPurgeStatus 7035;
BA_ "SigType" SG_ 2566668030 HeatExchangerDebrisPurgeStatus 5;
BA_ "SPN" SG_ 2566667774 EngEndBearing8Temp 7050;
BA_ "SigType" SG_ 2566667774 EngEndBearing8Temp 1;
BA_ "SPN" SG_ 2566667774 EngEndBearing7Temp 7049;
BA_ "SigType" SG_ 2566667774 EngEndBearing7Temp 1;
BA_ "SPN" SG_ 2566667774 EngEndBearing6Temp 7048;
BA_ "SigType" SG_ 2566667774 EngEndBearing6Temp 1;
BA_ "SPN" SG_ 2566667774 EngEndBearing5Temp 7047;
BA_ "SigType" SG_ 2566667774 EngEndBearing5Temp 1;
BA_ "SPN" SG_ 2566667774 EngEndBearing4Temp 7046;
BA_ "SigType" SG_ 2566667774 EngEndBearing4Temp 1;
BA_ "SPN" SG_ 2566667774 EngEndBearing3Temp 7045;
BA_ "SigType" SG_ 2566667774 EngEndBearing3Temp 1;
BA_ "SPN" SG_ 2566667774 EngEndBearing2Temp 7044;
BA_ "SigType" SG_ 2566667774 EngEndBearing2Temp 1;
BA_ "SPN" SG_ 2566667774 EngEndBearing1Temp 7043;
BA_ "SigType" SG_ 2566667774 EngEndBearing1Temp 1;
BA_ "SPN" SG_ 2566667518 EngEndBearing16Temp 7058;
BA_ "SigType" SG_ 2566667518 EngEndBearing16Temp 1;
BA_ "SPN" SG_ 2566667518 EngEndBearing15Temp 7057;
BA_ "SigType" SG_ 2566667518 EngEndBearing15Temp 1;
BA_ "SPN" SG_ 2566667518 EngEndBearing14Temp 7056;
BA_ "SigType" SG_ 2566667518 EngEndBearing14Temp 1;
BA_ "SPN" SG_ 2566667518 EngEndBearing13Temp 7055;
BA_ "SigType" SG_ 2566667518 EngEndBearing13Temp 1;
BA_ "SPN" SG_ 2566667518 EngEndBearing12Temp 7054;
BA_ "SigType" SG_ 2566667518 EngEndBearing12Temp 1;
BA_ "SPN" SG_ 2566667518 EngEndBearing11Temp 7053;
BA_ "SigType" SG_ 2566667518 EngEndBearing11Temp 1;
BA_ "SPN" SG_ 2566667518 EngEndBearing10Temp 7052;
BA_ "SigType" SG_ 2566667518 EngEndBearing10Temp 1;
BA_ "SPN" SG_ 2566667518 EngEndBearing9Temp 7051;
BA_ "SigType" SG_ 2566667518 EngEndBearing9Temp 1;
BA_ "SPN" SG_ 2566667262 EngEndBearing20Temp 7062;
BA_ "SigType" SG_ 2566667262 EngEndBearing20Temp 1;
BA_ "SPN" SG_ 2566667262 EngEndBearing19Temp 7061;
BA_ "SigType" SG_ 2566667262 EngEndBearing19Temp 1;
BA_ "SPN" SG_ 2566667262 EngEndBearing18Temp 7060;
BA_ "SigType" SG_ 2566667262 EngEndBearing18Temp 1;
BA_ "SPN" SG_ 2566667262 EngEndBearing17Temp 7059;
BA_ "SigType" SG_ 2566667262 EngEndBearing17Temp 1;
BA_ "SPN" SG_ 2499558142 GsFlSpplyShtoffValve2IntakePress 7066;
BA_ "SigType" SG_ 2499558142 GsFlSpplyShtoffValve2IntakePress 1;
BA_ "SPN" SG_ 2499558142 GsFlSpplyShtoffValve1IntakePress 7065;
BA_ "SigType" SG_ 2499558142 GsFlSpplyShtoffValve1IntakePress 1;
BA_ "SPN" SG_ 2499558142 GasFuelSupplyUnitIntakePress 7064;
BA_ "SigType" SG_ 2499558142 GasFuelSupplyUnitIntakePress 1;
BA_ "SPN" SG_ 2499558142 EngGasFuelSupplyPress2 7063;
BA_ "SigType" SG_ 2499558142 EngGasFuelSupplyPress2 1;
BA_ "SPN" SG_ 2499557886 PlantInertGasSupplyOutletPress 7068;
BA_ "SigType" SG_ 2499557886 PlantInertGasSupplyOutletPress 1;
BA_ "SPN" SG_ 2499557886 PlantGasFuelSupplyOutletPress 7067;
BA_ "SigType" SG_ 2499557886 PlantGasFuelSupplyOutletPress 1;
BA_ "SPN" SG_ 2499557630 EngOilMist8Concentration 7078;
BA_ "SigType" SG_ 2499557630 EngOilMist8Concentration 1;
BA_ "SPN" SG_ 2499557630 EngOilMist7Concentration 7077;
BA_ "SigType" SG_ 2499557630 EngOilMist7Concentration 1;
BA_ "SPN" SG_ 2499557630 EngOilMist6Concentration 7076;
BA_ "SigType" SG_ 2499557630 EngOilMist6Concentration 1;
BA_ "SPN" SG_ 2499557630 EngOilMist5Concentration 7075;
BA_ "SigType" SG_ 2499557630 EngOilMist5Concentration 1;
BA_ "SPN" SG_ 2499557630 EngOilMist4Concentration 7074;
BA_ "SigType" SG_ 2499557630 EngOilMist4Concentration 1;
BA_ "SPN" SG_ 2499557630 EngOilMist3Concentration 7073;
BA_ "SigType" SG_ 2499557630 EngOilMist3Concentration 1;
BA_ "SPN" SG_ 2499557630 EngOilMist2Concentration 7072;
BA_ "SigType" SG_ 2499557630 EngOilMist2Concentration 1;
BA_ "SPN" SG_ 2499557630 EngOilMist1Concentration 7071;
BA_ "SigType" SG_ 2499557630 EngOilMist1Concentration 1;
BA_ "SPN" SG_ 2499557374 EngOilMist10Concentration 7080;
BA_ "SigType" SG_ 2499557374 EngOilMist10Concentration 1;
BA_ "SPN" SG_ 2499557374 EngOilMist9Concentration 7079;
BA_ "SigType" SG_ 2499557374 EngOilMist9Concentration 1;
BA_ "SPN" SG_ 2499557118 InertGasSupplyValvePos 7442;
BA_ "SigType" SG_ 2499557118 InertGasSupplyValvePos 1;
BA_ "SPN" SG_ 2499557118 GasFuelSupplyBleedValve3Pos 7085;
BA_ "SigType" SG_ 2499557118 GasFuelSupplyBleedValve3Pos 1;
BA_ "SPN" SG_ 2499557118 GasFuelSupplyBleedValve2Pos 7084;
BA_ "SigType" SG_ 2499557118 GasFuelSupplyBleedValve2Pos 1;
BA_ "SPN" SG_ 2499557118 GasFuelSupplyBleedValve1Pos 7083;
BA_ "SigType" SG_ 2499557118 GasFuelSupplyBleedValve1Pos 1;
BA_ "SPN" SG_ 2499557118 GasFuelSupplyShutoffValve2Pos 7082;
BA_ "SigType" SG_ 2499557118 GasFuelSupplyShutoffValve2Pos 1;
BA_ "SPN" SG_ 2499557118 GasFuelSupplyShutoffValve1Pos 7081;
BA_ "SigType" SG_ 2499557118 GasFuelSupplyShutoffValve1Pos 1;
BA_ "SPN" SG_ 2566665726 AT2DslExhustFluidPump2MotorSpeed 7466;
BA_ "SigType" SG_ 2566665726 AT2DslExhustFluidPump2MotorSpeed 1;
BA_ "SPN" SG_ 2566665726 AT2DieselExhaustFluidPumpHeater 7086;
BA_ "SigType" SG_ 2566665726 AT2DieselExhaustFluidPumpHeater 1;
BA_ "SPN" SG_ 2499556606 EngInjectorMeteringRail2Press2 7099;
BA_ "SigType" SG_ 2499556606 EngInjectorMeteringRail2Press2 1;
BA_ "SPN" SG_ 2499556606 EngInjectorMeteringRail2Press1 7098;
BA_ "SigType" SG_ 2499556606 EngInjectorMeteringRail2Press1 1;
BA_ "SPN" SG_ 2499556606 EngInjectorMeteringRail1Press2 7097;
BA_ "SigType" SG_ 2499556606 EngInjectorMeteringRail1Press2 1;
BA_ "SPN" SG_ 2499556606 EngInjectorMeteringRail1Press1 7096;
BA_ "SigType" SG_ 2499556606 EngInjectorMeteringRail1Press1 1;
BA_ "SPN" SG_ 2499556350 EngInjctrMtringRail2DesiredPress 7101;
BA_ "SigType" SG_ 2499556350 EngInjctrMtringRail2DesiredPress 1;
BA_ "SPN" SG_ 2499556350 EngInjctrMtringRail1DesiredPress 7100;
BA_ "SigType" SG_ 2499556350 EngInjctrMtringRail1DesiredPress 1;
BA_ "SPN" SG_ 2499556094 AT1PrtcltSnsrHtrPwrSpplyDgnstcSt 7330;
BA_ "SPN" SG_ 2499556094 AT1PrtcltSnsrHtrPwrSpplyPrlmnryF 7329;
BA_ "SPN" SG_ 2499556094 AT1PrtcltSnsrPwrSpplyDgnstcSttus 7328;
BA_ "SPN" SG_ 2499556094 AT1PrtcltSnsrPwrSpplyPrlmnaryFMI 7327;
BA_ "SPN" SG_ 2499556094 AT1PrtcltSnsrInptDagnosticStatus 7326;
BA_ "SPN" SG_ 2499556094 AT1PrtcltSnsrInputPreliminaryFMI 7325;
BA_ "SPN" SG_ 2499556094 AT1PrtcltSnsrHtrLwSdDrvrDgnstcSt 7324;
BA_ "SPN" SG_ 2499556094 AT1PrtcltSnsrHtrLwSdDrvrPrlmnryF 7323;
BA_ "SPN" SG_ 2499556094 AT1PrtcltSnsrHtrHghSdDrvrDgnstcS 7322;
BA_ "SPN" SG_ 2499556094 AT1PrtcltSnsrHtrHghSdDrvrPrlmnry 7321;
BA_ "SPN" SG_ 2566664702 ATAmbientAirTemp 7441;
BA_ "SigType" SG_ 2566664702 ATAmbientAirTemp 1;
BA_ "SPN" SG_ 2566664702 ATEngLoadRq 7503;
BA_ "SigType" SG_ 2566664702 ATEngLoadRq 5;
BA_ "SPN" SG_ 2566664702 ATEngSpeedCtrlRq 7502;
BA_ "SigType" SG_ 2566664702 ATEngSpeedCtrlRq 5;
BA_ "SPN" SG_ 2566664702 ATActvRgnrtnInhbtdDTLwExhstPress 7440;
BA_ "SigType" SG_ 2566664702 ATActvRgnrtnInhbtdDTLwExhstPress 5;
BA_ "SPN" SG_ 2566664702 ATThermalManagementStatus 7332;
BA_ "SigType" SG_ 2566664702 ATThermalManagementStatus 5;
BA_ "SPN" SG_ 2633773310 SCROprtrIndcmntOvrrdTmeRemaining 7344;
BA_ "SigType" SG_ 2633773310 SCROprtrIndcmntOvrrdTmeRemaining 1;
BA_ "SPN" SG_ 2633773310 SCROprtrIndcmntOvrrdRnwlRequired 7343;
BA_ "SigType" SG_ 2633773310 SCROprtrIndcmntOvrrdRnwlRequired 5;
BA_ "SPN" SG_ 2633773310 SCROpratorInducementOverrideMode 7342;
BA_ "SPN" SG_ 2633773310 SCROprtrIndcmntEmrgncyOvrrdTtlRs 7341;
BA_ "SigType" SG_ 2633773310 SCROprtrIndcmntEmrgncyOvrrdTtlRs 1;
BA_ "SPN" SG_ 2633773054 FrSpprssnCmprssdArFmSystmArPress 7350;
BA_ "SigType" SG_ 2633773054 FrSpprssnCmprssdArFmSystmArPress 1;
BA_ "SPN" SG_ 2633773054 FrSuppressionClassBFoamTankLevel 7349;
BA_ "SigType" SG_ 2633773054 FrSuppressionClassBFoamTankLevel 1;
BA_ "SPN" SG_ 2633773054 FrSuppressionClassAFoamTankLevel 7348;
BA_ "SigType" SG_ 2633773054 FrSuppressionClassAFoamTankLevel 1;
BA_ "SPN" SG_ 2633773054 FireSuppressionWaterTankLevel 7347;
BA_ "SigType" SG_ 2633773054 FireSuppressionWaterTankLevel 1;
BA_ "SPN" SG_ 2566663934 EngThrttlVlv1MotorCurrentDisable 7383;
BA_ "SigType" SG_ 2566663934 EngThrttlVlv1MotorCurrentDisable 5;
BA_ "SPN" SG_ 2566663934 EngCylHdBypssActtr1MtrCrrntDsble 7382;
BA_ "SigType" SG_ 2566663934 EngCylHdBypssActtr1MtrCrrntDsble 5;
BA_ "SPN" SG_ 2566663934 EngTrbWstgtActtr1MtrCrrntDisable 7381;
BA_ "SigType" SG_ 2566663934 EngTrbWstgtActtr1MtrCrrntDisable 5;
BA_ "SPN" SG_ 2566663934 EngTrbCmprssrBlwffActtr1MtrCrrnt 7380;
BA_ "SigType" SG_ 2566663934 EngTrbCmprssrBlwffActtr1MtrCrrnt 5;
BA_ "SPN" SG_ 2566663678 EngFl2InjectorMeteringRail1Temp2 7514;
BA_ "SigType" SG_ 2566663678 EngFl2InjectorMeteringRail1Temp2 1;
BA_ "SPN" SG_ 2566663678 LNGTank2VaporPress 6788;
BA_ "SigType" SG_ 2566663678 LNGTank2VaporPress 1;
BA_ "SPN" SG_ 2566663678 LNGTank1VaporPress 6787;
BA_ "SigType" SG_ 2566663678 LNGTank1VaporPress 1;
BA_ "SPN" SG_ 2566663422 TrlrBrkClprLnngClranceAxle5Right 7415;
BA_ "SigType" SG_ 2566663422 TrlrBrkClprLnngClranceAxle5Right 4;
BA_ "SPN" SG_ 2566663422 TrlrBrkClprLnngClaranceAxle5Left 7414;
BA_ "SigType" SG_ 2566663422 TrlrBrkClprLnngClaranceAxle5Left 4;
BA_ "SPN" SG_ 2566663422 TrlrBrkClprLnngClranceAxle4Right 7413;
BA_ "SigType" SG_ 2566663422 TrlrBrkClprLnngClranceAxle4Right 4;
BA_ "SPN" SG_ 2566663422 TrlrBrkClprLnngClaranceAxle4Left 7412;
BA_ "SigType" SG_ 2566663422 TrlrBrkClprLnngClaranceAxle4Left 4;
BA_ "SPN" SG_ 2566663422 TrlrBrkClprLnngClranceAxle3Right 7411;
BA_ "SigType" SG_ 2566663422 TrlrBrkClprLnngClranceAxle3Right 4;
BA_ "SPN" SG_ 2566663422 TrlrBrkClprLnngClaranceAxle3Left 7410;
BA_ "SigType" SG_ 2566663422 TrlrBrkClprLnngClaranceAxle3Left 4;
BA_ "SPN" SG_ 2566663422 TrlrBrkClprLnngClranceAxle2Right 7409;
BA_ "SigType" SG_ 2566663422 TrlrBrkClprLnngClranceAxle2Right 4;
BA_ "SPN" SG_ 2566663422 TrlrBrkClprLnngClaranceAxle2Left 7408;
BA_ "SigType" SG_ 2566663422 TrlrBrkClprLnngClaranceAxle2Left 4;
BA_ "SPN" SG_ 2566663422 TrlrBrkClprLnngClranceAxle1Right 7407;
BA_ "SigType" SG_ 2566663422 TrlrBrkClprLnngClranceAxle1Right 4;
BA_ "SPN" SG_ 2566663422 TrlrBrkClprLnngClaranceAxle1Left 7406;
BA_ "SigType" SG_ 2566663422 TrlrBrkClprLnngClaranceAxle1Left 4;
BA_ "SPN" SG_ 2566663422 TrctrBrkClprLnngClrnceAxle5Right 7405;
BA_ "SigType" SG_ 2566663422 TrctrBrkClprLnngClrnceAxle5Right 4;
BA_ "SPN" SG_ 2566663422 TrctrBrkClprLnngClranceAxle5Left 7404;
BA_ "SigType" SG_ 2566663422 TrctrBrkClprLnngClranceAxle5Left 4;
BA_ "SPN" SG_ 2566663422 TrctrBrkClprLnngClrnceAxle4Right 7403;
BA_ "SigType" SG_ 2566663422 TrctrBrkClprLnngClrnceAxle4Right 4;
BA_ "SPN" SG_ 2566663422 TrctrBrkClprLnngClranceAxle4Left 7402;
BA_ "SigType" SG_ 2566663422 TrctrBrkClprLnngClranceAxle4Left 4;
BA_ "SPN" SG_ 2566663422 TrctrBrkClprLnngClrnceAxle3Right 7401;
BA_ "SigType" SG_ 2566663422 TrctrBrkClprLnngClrnceAxle3Right 4;
BA_ "SPN" SG_ 2566663422 TrctrBrkClprLnngClranceAxle3Left 7400;
BA_ "SigType" SG_ 2566663422 TrctrBrkClprLnngClranceAxle3Left 4;
BA_ "SPN" SG_ 2566663422 TrctrBrkClprLnngClrnceAxle2Right 7399;
BA_ "SigType" SG_ 2566663422 TrctrBrkClprLnngClrnceAxle2Right 4;
BA_ "SPN" SG_ 2566663422 TrctrBrkClprLnngClranceAxle2Left 7398;
BA_ "SigType" SG_ 2566663422 TrctrBrkClprLnngClranceAxle2Left 4;
BA_ "SPN" SG_ 2566663422 TrctrBrkClprLnngClrnceAxle1Right 7397;
BA_ "SigType" SG_ 2566663422 TrctrBrkClprLnngClrnceAxle1Right 4;
BA_ "SPN" SG_ 2566663422 TrctrBrkClprLnngClranceAxle1Left 7396;
BA_ "SigType" SG_ 2566663422 TrctrBrkClprLnngClranceAxle1Left 4;
BA_ "SPN" SG_ 2566663166 CruiseCtrlAdjustedMaxSpeed 7495;
BA_ "SigType" SG_ 2566663166 CruiseCtrlAdjustedMaxSpeed 1;
BA_ "SPN" SG_ 2566663166 AppliedVehicleSpeedLimit 7420;
BA_ "SigType" SG_ 2566663166 AppliedVehicleSpeedLimit 1;
BA_ "SPN" SG_ 2566662910 OprtrIndcmntTmTTrqueDerateLevel2 7428;
BA_ "SigType" SG_ 2566662910 OprtrIndcmntTmTTrqueDerateLevel2 1;
BA_ "SPN" SG_ 2566662910 OprtrIndcementTorqueDerateLevel2 7427;
BA_ "SigType" SG_ 2566662910 OprtrIndcementTorqueDerateLevel2 1;
BA_ "SPN" SG_ 2566662910 OprtrIndcmntTmTTrqueDerateLevel1 7426;
BA_ "SigType" SG_ 2566662910 OprtrIndcmntTmTTrqueDerateLevel1 1;
BA_ "SPN" SG_ 2566662910 OprtrIndcementTorqueDerateLevel1 7425;
BA_ "SigType" SG_ 2566662910 OprtrIndcementTorqueDerateLevel1 1;
BA_ "SPN" SG_ 2566662654 LaneMarkQualityOnTheRightSide 7482;
BA_ "SPN" SG_ 2566662654 LaneMarkQualityOnTheLeftSide 7481;
BA_ "SPN" SG_ 2566662654 LaneDepartureAngleRight 7480;
BA_ "SigType" SG_ 2566662654 LaneDepartureAngleRight 1;
BA_ "SPN" SG_ 2566662654 LaneDepartureAngleLeft 7479;
BA_ "SigType" SG_ 2566662654 LaneDepartureAngleLeft 1;
BA_ "SPN" SG_ 2566662654 RoadCurvatureBasedOnLaneMarks 7478;
BA_ "SigType" SG_ 2566662654 RoadCurvatureBasedOnLaneMarks 1;
BA_ "SPN" SG_ 2566662654 RghtDstncTLnMrkFrmVehiclesMiddle 7477;
BA_ "SigType" SG_ 2566662654 RghtDstncTLnMrkFrmVehiclesMiddle 1;
BA_ "SPN" SG_ 2566662654 LftDstncTLnMrkFromVehiclesMiddle 7476;
BA_ "SigType" SG_ 2566662654 LftDstncTLnMrkFromVehiclesMiddle 1;
BA_ "SPN" SG_ 2566662142 AT1DieselExhaustFluidCtrl2Temp 7528;
BA_ "SigType" SG_ 2566662142 AT1DieselExhaustFluidCtrl2Temp 1;
BA_ "SPN" SG_ 2566662142 AT1DieselExhaustFluidCtrl1Temp 5480;
BA_ "SigType" SG_ 2566662142 AT1DieselExhaustFluidCtrl1Temp 1;
BA_ "SPN" SG_ 2566661630 AT1DieselExhaustFluidTankHeater2 7573;
BA_ "SigType" SG_ 2566661630 AT1DieselExhaustFluidTankHeater2 1;
BA_ "SPN" SG_ 2566661630 AT1DieselExhaustFluidTankTemp2 7572;
BA_ "SigType" SG_ 2566661630 AT1DieselExhaustFluidTankTemp2 1;
BA_ "SPN" SG_ 2566661630 AT1DieselExhaustFluidTankVolume2 7530;
BA_ "SigType" SG_ 2566661630 AT1DieselExhaustFluidTankVolume2 1;
BA_ "SPN" SG_ 2566661374 AT2DieselExhaustFluidCtrl2Temp 7535;
BA_ "SigType" SG_ 2566661374 AT2DieselExhaustFluidCtrl2Temp 1;
BA_ "SPN" SG_ 2566661374 AT2DieselExhaustFluidCtrlTemp 7529;
BA_ "SigType" SG_ 2566661374 AT2DieselExhaustFluidCtrlTemp 1;
BA_ "SPN" SG_ 2566661374 AT2DieselExhaustFluidTankHeater2 7575;
BA_ "SigType" SG_ 2566661374 AT2DieselExhaustFluidTankHeater2 1;
BA_ "SPN" SG_ 2566661374 AT2DieselExhaustFluidTankTemp2 7574;
BA_ "SigType" SG_ 2566661374 AT2DieselExhaustFluidTankTemp2 1;
BA_ "SPN" SG_ 2566661374 AT2DieselExhaustFluidTankVolume2 7531;
BA_ "SigType" SG_ 2566661374 AT2DieselExhaustFluidTankVolume2 1;
BA_ "SPN" SG_ 2364598270 EngCyl24TimingOffset 7379;
BA_ "SigType" SG_ 2364598270 EngCyl24TimingOffset 1;
BA_ "SPN" SG_ 2364598270 EngCyl23TimingOffset 7378;
BA_ "SigType" SG_ 2364598270 EngCyl23TimingOffset 1;
BA_ "SPN" SG_ 2364598270 EngCyl22TimingOffset 7377;
BA_ "SigType" SG_ 2364598270 EngCyl22TimingOffset 1;
BA_ "SPN" SG_ 2364598270 EngCyl21TimingOffset 7376;
BA_ "SigType" SG_ 2364598270 EngCyl21TimingOffset 1;
BA_ "SPN" SG_ 2364598270 EngCyl20TimingOffset 7375;
BA_ "SigType" SG_ 2364598270 EngCyl20TimingOffset 1;
BA_ "SPN" SG_ 2364598270 EngCyl19TimingOffset 7374;
BA_ "SigType" SG_ 2364598270 EngCyl19TimingOffset 1;
BA_ "SPN" SG_ 2364598270 EngCyl18TimingOffset 7373;
BA_ "SigType" SG_ 2364598270 EngCyl18TimingOffset 1;
BA_ "SPN" SG_ 2364598270 EngCyl17TimingOffset 7372;
BA_ "SigType" SG_ 2364598270 EngCyl17TimingOffset 1;
VAL_ 2364473170 IndustryGroup 6 "Reserved for SAE" 7 "Reserved for SAE" 5 "IndustrialProcessCtrlStationary" 4 "Marine" 3 "Construction" 2 "Agricultural and Forestry" 1 "On-Highway" 0 "Global" ;
VAL_ 2364473170 Function 127 "Reserved" 126 "Reserved" 125 "Reserved" 124 "Reserved" 123 "Reserved" 122 "Reserved" 121 "Reserved" 120 "Reserved" 119 "Reserved" 118 "Reserved" 117 "Reserved" 116 "Reserved" 115 "Reserved" 114 "Reserved" 113 "Reserved" 112 "Reserved" 111 "Reserved" 110 "Reserved" 109 "Reserved" 108 "Reserved" 107 "Reserved" 106 "Reserved" 105 "Reserved" 104 "Reserved" 103 "Reserved" 102 "Reserved" 101 "Reserved" 42 "Water Pump Control" 41 "Lighting - Operator Controls" 40 "Seat Control" 39 "Ignition Control Module" 38 "Tire Pressure Control" 37 "Cab Controller" 36 "Pneumatic - System Controller" 35 "Suspension - System Controller" 34 "Hydraulic Pump Controller" 33 "System Monitor" 32 "Headway Controller" 31 "Propulsion Battery Charger" 30 "Management Computer" 29 "Virtual Terminal (in cab)" 28 "Off Vehicle Gateway" 27 "Power TakeOff (Secondary or Front)" 26 "Body Controller" 25 "Network Interconnect ECU" 24 "Vehicle Security" 23 "Vehicle Navigation" 22 "Aerodynamic Control" 21 "Cab Climate Control" 20 "Trip Recorder" 19 "Instrument Cluster" 18 "Suspension - Drive Axle" 17 "Suspension - Steer Axle" 16 "Steering Controller" 15 "Fuel System" 14 "Cruise Control" 13 "Retarder - Driveline" 12 "Retarder - Engine" 11 "Brakes - Drive Axle" 10 "Brakes - Steer Axle" 9 "Brakes - System Controller" 8 "Axle - Drive" 7 "Axle - Steering" 6 "Power TakeOff - (Main or Rear)" 5 "Shift Control/Console" 4 "Battery Pack Monitor" 3 "Transmission" 2 "Electric Propulsion Control" 1 "Auxiliary Power Unit (APU)" 0 "Engine" 100 "Reserved" 99 "Reserved" 98 "Reserved" 97 "Reserved" 96 "Reserved" 95 "Reserved" 94 "Reserved" 93 "Reserved" 92 "Reserved" 91 "Reserved" 90 "Reserved" 89 "Reserved" 88 "Reserved" 87 "Reserved" 86 "Reserved" 85 "Reserved" 84 "Reserved" 83 "Reserved" 82 "Reserved" 81 "Reserved" 80 "Reserved" 79 "Reserved" 78 "Fire Suppression System" 77 "Fuel Properties Sensor" 76 "Temperature Sensor" 75 "Supplemental Fan" 74 "Lubrication System" 73 "Rollover Detection Control" 72 "Coolant Valve Controller" 71 "Transfer Case Control" 70 "Auxiliary Regeneration Device" 69 "Engine Emission Aftertreatement System" 68 "Aftertreatment system gas measurement" 67 "Electrical System Controller" 66 "I/O Controller" 65 "Gas Flow Measurement" 64 "Endurance Braking" 63 "Engine Valve Controller" 62 "On-Board Diagnostic Unit" 61 "File Server/Printer" 60 "Cab Display" 59 "Starter" 58 "Fan Drive Control" 57 "Steering Column Unit" 56 "Communications Unit, Radio" 55 "Communications Unit, Satellite" 54 "Communications Unit, Cellular" 53 "Alternator/Charging System" 52 "Chassis Controller" 51 "Forward-Looking Collision Warning System" 50 "Auxiliary Heater" 49 "Clutch/Converter Control" 48 "Ramp Control" 47 "Information System Controller" 46 "Oil Sensor Unit" 45 "Vehicle Dynamic Stability Control" 44 "Exhaust Emission Control" 43 "Transmission Display" ;
VAL_ 2364473170 ManufacturerCode 454 "NGK Spark Plug Co. Ltd" 453 "Cooper Bussmann" 452 "WIKA Alexander Wiegand SE & Co. KG" 451 "Parker Hannifin Corp" 450 "Dycor Technologies Ltd." 449 "Polaris Industries Inc" 448 "Stanadyne Corporation, Electronics Systems" 447 "Great Plains Mfg." 446 "CertTech, L.L.C." 445 "KAT MECHATRONIC, Electronic Product Division" 444 "ITT Power Solutions" 443 "SignalQuest, Inc." 442 "Horsch Maschinen GmbH" 441 "PTG Reifendruckregelsysteme GmbH" 440 "Cummins Power Generation" 439 "Hyundai Heavy Industries" 438 "Comar Systems Ltd" 437 "Digital Yacht Limited" 436 "Kinze Manufacturing" 435 "Zunhammer GmbH" 434 "Stored Energy Systems" 433 "Rowe Electronics" 432 "S&A Systems, Inc." 431 "Tohatsu Corporation" 430 "Auteq Telematica S.A." 520 "Trapeze" 519 "Peeters Landbouwmachines b.v." 518 "Transas USA Inc." 517 "Noland Engineering" 516 "AVAT Automation GmbH" 515 "GINAF Trucks Nederland B.V." 514 "DISTek Integration, Inc." 513 "FarmscanAg" 512 "Inpower LLC" 511 "Sulky" 510 "Marinesoft Co. Ltd" 509 "MOTORTECH GmbH" 508 "Transtech Innovations" 507 "Test Center ISOBUS" 506 "IHI STAR Machinery Corporation" 505 "Yetter Farm Equipment" 504 "Vesper Marine" 503 "Naviop S.R.L." 502 "Attwood Corporation" 501 "Agrotronix S.A." 500 "Oxbo International Corporation" 499 "LCJ Capteurs" 498 "Innovative Design Solutions, Inc" 497 "SENTRON Sistemas Embarcados" 496 "W. Gessmann GmbH" 495 "HOLMER Maschinenbau GmbH" 494 "Synerject" 493 "Watcheye" 492 "Inergy Automotive Systems" 491 "Penny and Giles Ltd" 490 "QuikQ" 489 "Appareo Systems" 488 "The Charles Machine Works, Inc." 487 "DSE Test Solutions A/S" 486 "Westport Innovations Inc." 485 "MATT automotive" 484 "Headsight Inc." 483 "Valeo" 482 "Tricon Electronics" 481 "Chetco Digital Instruments" 480 "EnerDel, Inc." 479 "Vapor Bus International" 478 "OceanSat BV" 477 "OilQuick AB" 476 "Hummingbird Marine Electronics" 475 "GME" 474 "Persen Technologies Inc." 473 "Boss Industries, Inc." 472 "Tenneco Inc." 471 "Sea Cross Marine AB" 470 "SI-TEX Marine Electronics" 469 "RA Consulting GmbH" 468 "Tyco Fire Protection Products" 467 "Lely Industries N.V." 466 "Veethree Electronics and Marine LLC" 465 "Ashcroft Inc" 464 "Leach International Corporation" 463 "PROBOTIQ" 462 "IHI Shibaura Machinery Corporation" 461 "HAWE Hydraulik SE" 460 "San Giorgio S.E.I.N." 459 "Alltek Marine Electronics Corp" 458 "Control Solutions, Inc." 457 "RUSELPROM-ElectricDrive Ltd" 456 "General Kinetics" 455 "ADZ NAGANO GmbH" 429 "Rota Engineering Ltd." 428 "Mfg_428" 427 "em-trak Marine Electronics Ltd" 426 "Egersund Marine Electronics AS" 425 "Methode Electronics Inc, MDI" 424 "Odyne LLC" 423 "BSM Wireless, Inc." 422 "True Heading AB" 421 "Vertex Standard Co, Ltd" 420 "Vermeer Corporation, ACS Group" 419 "Fusion Electronics Ltd" 418 "Intellistick Inc" 417 "KZValve" 416 "Kubota Corporation" 415 "Valid Manufacturing Ltd." 414 "Cattron Group International" 413 "Datapross Nijbroek bv" 412 "WebTech Wireless Inc." 411 "Hy-Drive Technologies Ltd." 410 "COBO S.p.A. Divisione 3B6" 409 "Transfluid S.r.L." 408 "Corvus Energy Ltd." 407 "Comtech Mobile Datacom" 406 "Vecima Networks Inc." 405 "Wema System AS" 404 "Com Nav Marine Ltd" 403 "Trackwell ADS, Inc." 402 "Simma Software, Inc." 401 "Torqeedo GmbH" 400 "Livorsi Marine" 399 "ISEKI & Co., Ltd." 398 "Hilite International" 397 "Sanyo-kiki Co Ltd." 396 "Beyond Measure" 395 "GENTEC S.R.L." 394 "Capi 2 Nederland BV" 393 "Harvest Tec, Inc" 392 "Tianyuan Technology Co Ltd." 391 "Electronic Design for Industry, Inc" 390 "Partech Inc." 389 "Benchmark Electronics, Minnesota Division" 388 "Innomatix, LLC" 387 "Orscheln Products, LLC" 386 "JLG Automation BVBA" 385 "Johnson Outdoor Marine Electronics" 384 "Camano Light" 383 "MCL Industries" 382 "National Agricultural and Food Research Organization" 380 "Suntech International Ltd." 379 "Yamabiko Corporation" 378 "Glendinning Marine Products" 377 "ifm electronic gmbh" 376 "Quake Global" 375 "Williams Controls Inc." 372 "Delphi" 381 "B&G" 374 "Northern Lights, Inc." 373 "Electronic Design Inc." 371 "Heinzmann GmbH & Co. KG" 370 "Rolls-Royce Marine AS" 369 "Power Torque Engineering Ltd" 368 "HANSENHOF_electronic" 367 "Fliegl Agrartechnik" 366 "Viewnyx Corp." 365 "Digi-Star, LLC" 364 "OEM Controls Inc." 363 "BEI Duncan" 362 "Alois Poettinger Maschinenfabrik GmbH" 361 "InMach" 360 "HJS Emission Technology GmbH & Co KG" 359 "Ludwig Bergmann GmbH" 358 "Victron Energy BV" 357 "Hardi International A/S" 356 "Fischer Panda Generators, Inc" 355 "Mastervolt International B.V." 354 "Junkkari OY" 353 "Hegemon Electronics, Inc." 352 "SAME DEUTZ-FAHR" 351 "Thrane & Thrane" 350 "Noris Marine Systems GmbH & Co KG" 349 "Suonentiet" 348 "Amazonen Werke H. Dreyer" 347 "Honeywell" 346 "Control Solutions" 345 "Korean Maritime University" 344 "Parvus Corporation" 343 "Baumer Group" 342 "THOMAS MAGNETE GmbH" 341 "Boning GmbH & Co" 340 "Continental AG" 339 "Competence Center ISOBUS e.V." 338 "GRAF-SYTECO" 337 "Carraro S.p.A." 336 "APE s.r.o." 335 "Evo Electric Ltd" 334 "Takata-Petri AG" 333 "Hadley Products Corporation" 332 "HWH Corporation" 331 "Horton, Inc." 330 "Kidde Aerospace and Defense" 329 "Deif A/S" 328 "Qwerty Electronik AB" 252 "Sensor-Technik Wiedemann GmbH" 251 "German Agricultural Society" 250 "Kuhn Group" 249 "Schaltbau GmbH" 233 "Yacht Monitoring Solutions Inc." 232 "TSD Integrated Controls" 1863 "Thomas G. Faria Co." 1862 "Sanshin" 1861 "Vector CANtech" 1860 "MMP" 1859 "Kvasar AB" 1858 "Litton" 1857 "Simrad" 1856 "Trimble" 1855 "Furuno USA" 1854 "Northstar Technologies" 1853 "Japan Radio Co." 1852 "Navionics" 1851 "Raymarine" 1850 "Teleflex" 222 "Generac Power Systems, Inc." 221 "SiE" 220 "Beede Electrical Instrument Company, Inc." 219 "Cat OEM Solutions" 218 "Gits Manufacturing Company" 217 "RM Michaelides Software & Elektronik GmbH" 216 "Paneltronics Inc." 215 "Aetna Engineering/Fireboy-Xintex" 214 "MC elettronica Srl" 213 "CNH Belgium N.V." 212 "Sure Power Industries, Inc." 211 "DNA Group" 210 "Iteris, Inc." 209 "Bell Equip. Co. SA (PTY) LTD" 208 "Drew Technologies, Inc." 207 "Otto Engineering" 206 "port GmbH" 205 "SmarTire Systems Inc" 204 "The Morey Corporation" 203 "MILtronik GmbH" 202 "Curtis Instruments, Inc." 201 "Disenos y Tecnologia S.A." 200 "MGM Brakes" 199 "Actia Corp." 198 "Mystic Valley Communications" 197 "Mechron Power Systems" 196 "LEMKEN GmbH & Co. KG" 195 "General Engine Products" 194 "TriMark Corporation" 193 "Nobletec" 192 "Floscan" 191 "XRS Corporation" 190 "Hella KGaA Hueck & Co." 189 "QUALCOMM" 188 "EMP Corp." 187 "Air-Weigh" 186 "Altronic, Inc." 185 "Beede Electrical Instrument Company" 184 "EIA Electronics" 183 "KDS Controls, Inc." 182 "Vehicle Systems Engineering B.V." 181 "Coretronics, Inc." 180 "Smart Power Systems" 179 "TeeJet Technologies Denmark" 178 "Siemens VDO Automotive AG" 177 "Diagnostic System Associates" 176 "Moritz Aerospace" 175 "Veris Technologies, Inc." 174 "AB Volvo Penta" 173 "Ryeso, Inc." 172 "Yanmar Marine USA" 171 "Wachendorff Elektronik GmbH & Co. KG" 170 "Computronics Corporation Ltd." 169 "Marlin Technologies Inc." 168 "Xantrex" 167 "JLG Industries Inc." 166 "Phoenix International" 165 "CPAC Systems AB" 164 "DaimlerChrysler Off-Highway" 163 "BRP Inc." 162 "Axiomatic Technologies" 161 "Offshore Systems (UK) Limited" 160 "Nido" 159 "NTech Industries Inc." 158 "Firestone Industrial Products Company" 157 "ISSPRO Inc." 156 "ITT Industries - Cannon" 155 "Vetronix Corporation" 154 "Westerbeke Corporation" 153 "Woodward, Industrial Controls Division" 152 "elobau GmbH & Co. KG" 151 "Raven Industries Inc. - Flow Controls Division" 150 "Fleetguard" 149 "Holset" 148 "Blue Water Data, Inc." 147 "Nautibus Electronic GmbH" 146 "Maxima Technologies" 145 "MurCal Controls" 144 "Mercury Marine" 143 "W. Gmeiner GmbH & Co." 142 "TRW Automotive (Commercial Steering Systems)" 141 "Thales Navigation Ltd." 140 "Lowrance Electronics, Inc." 139 "Caterpillar Trimble Control Technologies (CTCT), LLC" 138 "Georg Fritzmeier GmbH & Co. KG" 137 "Maretron" 136 "Komatsu Ltd." 135 "Airmar Technology Corporation" 134 "Iris Technology Ltd." 133 "Bucher Schoerling GmbH" 132 "Mulag-Fahrzeugwerk" 131 "ITT Industries" 130 "Nido - Universal Machines B.V." 129 "OMNEX Control Systems, Inc." 128 "Gerhard Duecker GmbH & Co. KG" 127 "Holland USA" 126 "Driver Tech" 125 "Nevada Automotive Test Center" 124 "Hydac Electronic" 123 "Basler Electric" 122 "FG Wilson (Engineering) Limited" 121 "HED (Hydro Electronic Devices, Inc.)" 120 "RDS Technology Ltd." 119 "IntegriNautics" 118 "Intron GmbH" 117 "HUSCO International" 116 "BEELINE Technologies" 115 "NACCO Materials Handling Group, Inc." 114 "EControls, Inc." 113 "Stress-Tek, Inc." 112 "MECALAC" 111 "Maschinenfabrik Bernard Krone GmbH" 110 "EPIQ Sensor-Nite" 109 "TeeJet Technologies Denmark" 108 "WTK-Elecktronik GmbH" 107 "Grimme Landmaschinen GmbH & Co. KG" 106 "BAE Systems Controls, Inc." 105 "Kiepe Elektrik GmbH & Co. KG" 104 "Claas Selbstfahrende Erntemaschinen GmbH" 103 "CLAAS Agrosystems GmbH & Co. KG" 102 "AGCO GmbH & Co." 101 "Sensoria" 100 "VDO Technik AG" 99 "International Transmissions Ltd (ITL)" 98 "Mueller-Elektronik GmbH & Co." 97 "Ag Leader Technology, Inc." 96 "Mech@tronic IT GmbH" 95 "Pacific Insight Electronics Corp." 94 "CNH Global N.V." 93 "Perkins Engines Company Ltd." 92 "Ag-Chem Equipment Co., Inc." 91 "BSG Bodensee Steuergeraete GmbH" 90 "Knorr-Bremse SfN GmbH" 89 "Kverneland Group, Electronics Division" 88 "Satloc Precision GPS" 87 "J.C. Bamford Excavators Ltd (JCB)" 86 "C.E. Niehoff & Company" 85 "Kohler Co." 84 "New Holland UK Limited" 83 "Bendix VORAD Technologies" 82 "Bobcat/Ingersoll-Rand" 81 "Fire Research Corp" 80 "Twin Disc, Inc." 79 "Daimler Benz AG - Engine Division (PBM)" 78 "Frank W. Murphy Manufacturing, Inc." 77 "Deere Power Systems Group" 76 "unused" 75 "Deere & Co. Agricultural Division" 74 "Eaton Axle-Brake Division" 73 "LeTourneau, Inc." 72 "Sisu Corporation" 71 "Vansco Electronics Ltd." 70 "Flex-Coil Limited" 69 "Trimble Navigation" 68 "Scania" 67 "Funk Manufacturing Company" 66 "John Deere Construction Equipment Division" 65 "MAN Nutzfahrzeuge AG" 64 "unused" 63 "ZF Industries Inc." 62 "Wabco" 61 "Volvo Truck Corp." 60 "Volvo Trucks North America Inc." 59 "VES Inc." 58 "SPX Corporation, OTC Division" 57 "Sauer-Danfoss Co." 56 "SAIC" 55 "Ryder System Inc." 54 "Meritor Wabco" 53 "Continental Automotive Systems US, Inc." 52 "Meritor Automotive, Inc." 51 "Robert Bosch GmbH" 50 "Robert Bosch Corp" 49 "RE America Inc." 48 "Pollak Alphabet" 47 "Phillips Semiconductor" 46 "Noregon Systems, Inc" 45 "PACCAR" 44 "Nippondenso Co. Ltd." 43 "International Truck and Engine Corp. Vehicle Electronics" 42 "International Truck and Engine Corp. Engine Electronics" 41 "Motorola Inc." 40 "Motorola AIEG Inc." 39 "Microfirm Inc." 38 "Micro Processor Systems Inc." 37 "Mack Trucks Inc." 36 "Lucas Ltd." 35 "Kenworth Truck Co." 34 "Kelsey Hayes Co." 33 "John Deere" 32 "Jacobs Vehicle Systems" 31 "J Pollak Corp." 30 "Isuzu Motors Ltd." 29 "Hino Motors Ltd." 28 "Grote Ind. Inc." 27 "GMC" 26 "General Motors Corp., Service Technology Group" 25 "Daimler Trucks North America LLC" 24 "Ford Motor Co., Vehicle Controls" 23 "Ford Motor Co., Heavy Truck" 22 "Ford Motor Co., Electronic Concepts $ Systems" 21 "Echilin Inc., Midland Brake Inc." 20 "Eaton Ltd" 19 "Eaton Corp. Trucking Info Services" 18 "Eaton Corp, Transmission Division" 17 "Eaton Corp. Res & Dev" 16 "Eaton Corp." 15 "Dickey-John Corp." 14 "Detroit Diesel Corporation" 13 "Delco Electronics" 12 "Deere & Company, Precision Farming" 11 "Dearborn Group Inc." 10 "Cummins Engine Co." 9 "Chrysler Corp." 8 "Caterpillar Inc." 7 "Case Corp." 6 "Berifors Electronics AB" 5 "AMP Inc." 4 "Ametek-Dixson" 3 "Ametek, US Gauge Division" 2 "Allison Transmission, GMC" 1 "Allied Signal Inc." 0 "Reserved" 231 "Topcon Positioning Systems, Inc." 230 "Saucon Technologies" 229 "Garmin International Inc." 228 "ZF Marine Electronics" 227 "Lykketronic A/S" 226 "Monaco Coach Corporation" 225 "SKF" 224 "EMMI Network, S.L." 223 "Vaueo Retarder Co., Ltd." 263 "IMMI" 262 "HydraForce, Inc" 261 "Red Dot Corporation" 260 "Reichhardt GmbH" 259 "Jetter AG" 258 "ARAG" 257 "Honda Motor Co., Ltd" 256 "Tyco Electronics AMP" 255 "MEAS France" 254 "GE Sensing" 253 "Mobile Control Systems" 298 "Holley Performance" 297 "Zonar Systems Inc" 296 "micro dynamics GmbH" 295 "BEP Marine" 294 "Grayhill Inc." 293 "Spyder Controls Corp." 292 "IKUSI - Angel Iglesias S.A." 291 "Groeneveld Transport Efficiency BV" 290 "Kuebler GmbH" 289 "Watlow" 288 "Mitsubishi FUSO Truck & Bus Corp." 287 "NTech Industries, Inc" 286 "Coelmo srl" 285 "Sea Recovery Corp" 284 "Mobile Tech Chile" 283 "CWF Hamilton & Co Ltd" 282 "Medallion Instrumentation Systems" 281 "Precision Governors LLC" 311 "Patrick Power Products" 310 "TECNORD srl" 309 "Krauss-Maffei Wegmann GmbH & Co. KG" 308 "Cyntrx" 307 "MBW Technologies" 306 "Sleipner Motor AB" 305 "NovAtel Inc" 304 "EmpirBus AB" 303 "CTS Corporation" 302 "Nissin Kogyo Co., LTD" 301 "Parker Hannifin (UK) Ltd FDE group" 300 "Systron Donner Automotive" 299 "Rauch Landmaschinen GmbH" 280 "Leica Geosystems Pty Ltd" 279 "Geometris LP" 278 "Takata Electronics" 277 "LHP Telematics" 276 "Aqua-Hot Heating Systems" 275 "Navico Egersund AS" 274 "LTW Technology Co., LTD" 273 "Active Research Limited" 272 "Gross Mechanical Laboratories, Inc" 327 "Sonceboz SA" 326 "Akron Brass Company" 325 "ASM Automation Sensorik Messtechnik GmbH" 324 "Snap-on Diagnostics" 323 "Mobileye Vision Technologies Ltd." 322 "MICHENKA s.r.o." 321 "Ultra Electronics, Electrics" 320 "Miedema Landbouwwerktuigenfabriek B.V." 319 "Cadec Global" 318 "SAT Plan" 317 "Navtronics Bvba" 316 "ITT Flow Control" 315 "Icom Incorporated" 314 "CSM GmbH" 313 "Ilmor Engineering, Inc" 312 "Lectronix, Inc." 271 "Cole Hersee" 270 "Tennant" 269 "Saft America Inc.,  Space & Defense Division" 268 "Accurate Technologies" 267 "Red Lion Controls, Inc" 266 "International Thermal Research Ltd" 265 "MTS Sensor Technologie GmbH" 264 "Autolync" 248 "Cooper Standard Automotive Active Systems Group" 247 "ePULSE" 246 "Class 1, Inc" 245 "Capstan Ag Systems, Inc." 244 "Techno-Matic" 243 "eRide, Inc." 242 "Kokusandenki Co. Ltd" 241 "Schneider Automation SAS " 240 "Vanair Mfg" 239 "May & Scofield Ltd" 238 "ZF Friedrichshafen AG" 237 "Agtron Enterprises Inc" 236 "Norac Systems International Inc" 235 "SailorMade Marine Telemetry - Tetra Technology Ltd." 234 "Mondial electronic GmbH" ;
VAL_ 2364473170 VehicleSystem 0 "Non-specific System" 127 "Not Available" ;
VAL_ 2364473170 VehicleSystem5 127 "Not Available" 0 "Ind. Process Control Stationary" ;
VAL_ 2364473170 VehicleSystem4 125 "Entertainment" 120 "Display" 85 "External Environment" 75 "Sensor Communication Interface" 35 "Electrical Generation" 100 "Deck, Cargo and Fishing Equipment" 90 "Internal Environment" 80 "Instrumentation/General Systems (deprecate)" 70 "Communications" 60 "Navigation" 50 "Propulsion" 40 "Steering and Control Surfaces" 30 "Electrical Distribution" 25 "Inter/Intranetwork Device" 20 "Safety Systems" 10 "System Tools" 127 "Not Available" 0 "Non-specific System" ;
VAL_ 2364473170 VehicleSystem3 8 "Grader" 7 "Four Wheel Drive Loader" 6 "Forklift" 5 "Excavator" 4 "Crawler" 3 "Backhoe" 2 "Articulated Dump Truck" 1 "Skid Steer Loader" 127 "Not Available" 0 "Non-specific System" ;
VAL_ 2364473170 VehicleSystem2 25 "Slurry Applicators" 24 "Utility Vehicles" 23 "Mulchers" 22 "Timber Processing Machines" 21 "Timber loaders" 20 "Forwarders" 19 "Timber Harvesters" 17 "Sensor Systems" 16 "Skidder" 15 "Earth Work" 14 "Special Crops" 13 "Powered Auxiliary Device" 12 "Farm Yard Operations" 11 "Transport/Trailer" 10 "Irrigation" 9 "Forage" 8 "Root Harvesters" 7 "Harvesters" 6 "Sprayers" 5 "Fertilizers" 4 "Planters/Seeders" 3 "Secondary Tillage" 2 "Tillage" 1 "Tractor" 127 "Not Available" 0 "Non-specific System" ;
VAL_ 2364473170 VehicleSystem1 2 "Trailer" 1 "Tractor" 127 "Not Available" 0 "Non-specific System" ;
VAL_ 2364473169 IndustryGroup 6 "Reserved for SAE" 7 "Reserved for SAE" 5 "IndustrialProcessCtrlStationary" 4 "Marine" 3 "Construction" 2 "Agricultural and Forestry" 1 "On-Highway" 0 "Global" ;
VAL_ 2364473169 Function 127 "Reserved" 126 "Reserved" 125 "Reserved" 124 "Reserved" 123 "Reserved" 122 "Reserved" 121 "Reserved" 120 "Reserved" 119 "Reserved" 118 "Reserved" 117 "Reserved" 116 "Reserved" 115 "Reserved" 114 "Reserved" 113 "Reserved" 112 "Reserved" 111 "Reserved" 110 "Reserved" 109 "Reserved" 108 "Reserved" 107 "Reserved" 106 "Reserved" 105 "Reserved" 104 "Reserved" 103 "Reserved" 102 "Reserved" 101 "Reserved" 42 "Water Pump Control" 41 "Lighting - Operator Controls" 40 "Seat Control" 39 "Ignition Control Module" 38 "Tire Pressure Control" 37 "Cab Controller" 36 "Pneumatic - System Controller" 35 "Suspension - System Controller" 34 "Hydraulic Pump Controller" 33 "System Monitor" 32 "Headway Controller" 31 "Propulsion Battery Charger" 30 "Management Computer" 29 "Virtual Terminal (in cab)" 28 "Off Vehicle Gateway" 27 "Power TakeOff (Secondary or Front)" 26 "Body Controller" 25 "Network Interconnect ECU" 24 "Vehicle Security" 23 "Vehicle Navigation" 22 "Aerodynamic Control" 21 "Cab Climate Control" 20 "Trip Recorder" 19 "Instrument Cluster" 18 "Suspension - Drive Axle" 17 "Suspension - Steer Axle" 16 "Steering Controller" 15 "Fuel System" 14 "Cruise Control" 13 "Retarder - Driveline" 12 "Retarder - Engine" 11 "Brakes - Drive Axle" 10 "Brakes - Steer Axle" 9 "Brakes - System Controller" 8 "Axle - Drive" 7 "Axle - Steering" 6 "Power TakeOff - (Main or Rear)" 5 "Shift Control/Console" 4 "Battery Pack Monitor" 3 "Transmission" 2 "Electric Propulsion Control" 1 "Auxiliary Power Unit (APU)" 0 "Engine" 100 "Reserved" 99 "Reserved" 98 "Reserved" 97 "Reserved" 96 "Reserved" 95 "Reserved" 94 "Reserved" 93 "Reserved" 92 "Reserved" 91 "Reserved" 90 "Reserved" 89 "Reserved" 88 "Reserved" 87 "Reserved" 86 "Reserved" 85 "Reserved" 84 "Reserved" 83 "Reserved" 82 "Reserved" 81 "Reserved" 80 "Reserved" 79 "Reserved" 78 "Fire Suppression System" 77 "Fuel Properties Sensor" 76 "Temperature Sensor" 75 "Supplemental Fan" 74 "Lubrication System" 73 "Rollover Detection Control" 72 "Coolant Valve Controller" 71 "Transfer Case Control" 70 "Auxiliary Regeneration Device" 69 "Engine Emission Aftertreatement System" 68 "Aftertreatment system gas measurement" 67 "Electrical System Controller" 66 "I/O Controller" 65 "Gas Flow Measurement" 64 "Endurance Braking" 63 "Engine Valve Controller" 62 "On-Board Diagnostic Unit" 61 "File Server/Printer" 60 "Cab Display" 59 "Starter" 58 "Fan Drive Control" 57 "Steering Column Unit" 56 "Communications Unit, Radio" 55 "Communications Unit, Satellite" 54 "Communications Unit, Cellular" 53 "Alternator/Charging System" 52 "Chassis Controller" 51 "Forward-Looking Collision Warning System" 50 "Auxiliary Heater" 49 "Clutch/Converter Control" 48 "Ramp Control" 47 "Information System Controller" 46 "Oil Sensor Unit" 45 "Vehicle Dynamic Stability Control" 44 "Exhaust Emission Control" 43 "Transmission Display" ;
VAL_ 2364473169 ManufacturerCode 454 "NGK Spark Plug Co. Ltd" 453 "Cooper Bussmann" 452 "WIKA Alexander Wiegand SE & Co. KG" 451 "Parker Hannifin Corp" 450 "Dycor Technologies Ltd." 449 "Polaris Industries Inc" 448 "Stanadyne Corporation, Electronics Systems" 447 "Great Plains Mfg." 446 "CertTech, L.L.C." 445 "KAT MECHATRONIC, Electronic Product Division" 444 "ITT Power Solutions" 443 "SignalQuest, Inc." 442 "Horsch Maschinen GmbH" 441 "PTG Reifendruckregelsysteme GmbH" 440 "Cummins Power Generation" 439 "Hyundai Heavy Industries" 438 "Comar Systems Ltd" 437 "Digital Yacht Limited" 436 "Kinze Manufacturing" 435 "Zunhammer GmbH" 434 "Stored Energy Systems" 433 "Rowe Electronics" 432 "S&A Systems, Inc." 431 "Tohatsu Corporation" 430 "Auteq Telematica S.A." 520 "Trapeze" 519 "Peeters Landbouwmachines b.v." 518 "Transas USA Inc." 517 "Noland Engineering" 516 "AVAT Automation GmbH" 515 "GINAF Trucks Nederland B.V." 514 "DISTek Integration, Inc." 513 "FarmscanAg" 512 "Inpower LLC" 511 "Sulky" 510 "Marinesoft Co. Ltd" 509 "MOTORTECH GmbH" 508 "Transtech Innovations" 507 "Test Center ISOBUS" 506 "IHI STAR Machinery Corporation" 505 "Yetter Farm Equipment" 504 "Vesper Marine" 503 "Naviop S.R.L." 502 "Attwood Corporation" 501 "Agrotronix S.A." 500 "Oxbo International Corporation" 499 "LCJ Capteurs" 498 "Innovative Design Solutions, Inc" 497 "SENTRON Sistemas Embarcados" 496 "W. Gessmann GmbH" 495 "HOLMER Maschinenbau GmbH" 494 "Synerject" 493 "Watcheye" 492 "Inergy Automotive Systems" 491 "Penny and Giles Ltd" 490 "QuikQ" 489 "Appareo Systems" 488 "The Charles Machine Works, Inc." 487 "DSE Test Solutions A/S" 486 "Westport Innovations Inc." 485 "MATT automotive" 484 "Headsight Inc." 483 "Valeo" 482 "Tricon Electronics" 481 "Chetco Digital Instruments" 480 "EnerDel, Inc." 479 "Vapor Bus International" 478 "OceanSat BV" 477 "OilQuick AB" 476 "Hummingbird Marine Electronics" 475 "GME" 474 "Persen Technologies Inc." 473 "Boss Industries, Inc." 472 "Tenneco Inc." 471 "Sea Cross Marine AB" 470 "SI-TEX Marine Electronics" 469 "RA Consulting GmbH" 468 "Tyco Fire Protection Products" 467 "Lely Industries N.V." 466 "Veethree Electronics and Marine LLC" 465 "Ashcroft Inc" 464 "Leach International Corporation" 463 "PROBOTIQ" 462 "IHI Shibaura Machinery Corporation" 461 "HAWE Hydraulik SE" 460 "San Giorgio S.E.I.N." 459 "Alltek Marine Electronics Corp" 458 "Control Solutions, Inc." 457 "RUSELPROM-ElectricDrive Ltd" 456 "General Kinetics" 455 "ADZ NAGANO GmbH" 429 "Rota Engineering Ltd." 428 "Mfg_428" 427 "em-trak Marine Electronics Ltd" 426 "Egersund Marine Electronics AS" 425 "Methode Electronics Inc, MDI" 424 "Odyne LLC" 423 "BSM Wireless, Inc." 422 "True Heading AB" 421 "Vertex Standard Co, Ltd" 420 "Vermeer Corporation, ACS Group" 419 "Fusion Electronics Ltd" 418 "Intellistick Inc" 417 "KZValve" 416 "Kubota Corporation" 415 "Valid Manufacturing Ltd." 414 "Cattron Group International" 413 "Datapross Nijbroek bv" 412 "WebTech Wireless Inc." 411 "Hy-Drive Technologies Ltd." 410 "COBO S.p.A. Divisione 3B6" 409 "Transfluid S.r.L." 408 "Corvus Energy Ltd." 407 "Comtech Mobile Datacom" 406 "Vecima Networks Inc." 405 "Wema System AS" 404 "Com Nav Marine Ltd" 403 "Trackwell ADS, Inc." 402 "Simma Software, Inc." 401 "Torqeedo GmbH" 400 "Livorsi Marine" 399 "ISEKI & Co., Ltd." 398 "Hilite International" 397 "Sanyo-kiki Co Ltd." 396 "Beyond Measure" 395 "GENTEC S.R.L." 394 "Capi 2 Nederland BV" 393 "Harvest Tec, Inc" 392 "Tianyuan Technology Co Ltd." 391 "Electronic Design for Industry, Inc" 390 "Partech Inc." 389 "Benchmark Electronics, Minnesota Division" 388 "Innomatix, LLC" 387 "Orscheln Products, LLC" 386 "JLG Automation BVBA" 385 "Johnson Outdoor Marine Electronics" 384 "Camano Light" 383 "MCL Industries" 382 "National Agricultural and Food Research Organization" 380 "Suntech International Ltd." 379 "Yamabiko Corporation" 378 "Glendinning Marine Products" 377 "ifm electronic gmbh" 376 "Quake Global" 375 "Williams Controls Inc." 372 "Delphi" 381 "B&G" 374 "Northern Lights, Inc." 373 "Electronic Design Inc." 371 "Heinzmann GmbH & Co. KG" 370 "Rolls-Royce Marine AS" 369 "Power Torque Engineering Ltd" 368 "HANSENHOF_electronic" 367 "Fliegl Agrartechnik" 366 "Viewnyx Corp." 365 "Digi-Star, LLC" 364 "OEM Controls Inc." 363 "BEI Duncan" 362 "Alois Poettinger Maschinenfabrik GmbH" 361 "InMach" 360 "HJS Emission Technology GmbH & Co KG" 359 "Ludwig Bergmann GmbH" 358 "Victron Energy BV" 357 "Hardi International A/S" 356 "Fischer Panda Generators, Inc" 355 "Mastervolt International B.V." 354 "Junkkari OY" 353 "Hegemon Electronics, Inc." 352 "SAME DEUTZ-FAHR" 351 "Thrane & Thrane" 350 "Noris Marine Systems GmbH & Co KG" 349 "Suonentiet" 348 "Amazonen Werke H. Dreyer" 347 "Honeywell" 346 "Control Solutions" 345 "Korean Maritime University" 344 "Parvus Corporation" 343 "Baumer Group" 342 "THOMAS MAGNETE GmbH" 341 "Boning GmbH & Co" 340 "Continental AG" 339 "Competence Center ISOBUS e.V." 338 "GRAF-SYTECO" 337 "Carraro S.p.A." 336 "APE s.r.o." 335 "Evo Electric Ltd" 334 "Takata-Petri AG" 333 "Hadley Products Corporation" 332 "HWH Corporation" 331 "Horton, Inc." 330 "Kidde Aerospace and Defense" 329 "Deif A/S" 328 "Qwerty Electronik AB" 252 "Sensor-Technik Wiedemann GmbH" 251 "German Agricultural Society" 250 "Kuhn Group" 249 "Schaltbau GmbH" 233 "Yacht Monitoring Solutions Inc." 232 "TSD Integrated Controls" 1863 "Thomas G. Faria Co." 1862 "Sanshin" 1861 "Vector CANtech" 1860 "MMP" 1859 "Kvasar AB" 1858 "Litton" 1857 "Simrad" 1856 "Trimble" 1855 "Furuno USA" 1854 "Northstar Technologies" 1853 "Japan Radio Co." 1852 "Navionics" 1851 "Raymarine" 1850 "Teleflex" 222 "Generac Power Systems, Inc." 221 "SiE" 220 "Beede Electrical Instrument Company, Inc." 219 "Cat OEM Solutions" 218 "Gits Manufacturing Company" 217 "RM Michaelides Software & Elektronik GmbH" 216 "Paneltronics Inc." 215 "Aetna Engineering/Fireboy-Xintex" 214 "MC elettronica Srl" 213 "CNH Belgium N.V." 212 "Sure Power Industries, Inc." 211 "DNA Group" 210 "Iteris, Inc." 209 "Bell Equip. Co. SA (PTY) LTD" 208 "Drew Technologies, Inc." 207 "Otto Engineering" 206 "port GmbH" 205 "SmarTire Systems Inc" 204 "The Morey Corporation" 203 "MILtronik GmbH" 202 "Curtis Instruments, Inc." 201 "Disenos y Tecnologia S.A." 200 "MGM Brakes" 199 "Actia Corp." 198 "Mystic Valley Communications" 197 "Mechron Power Systems" 196 "LEMKEN GmbH & Co. KG" 195 "General Engine Products" 194 "TriMark Corporation" 193 "Nobletec" 192 "Floscan" 191 "XRS Corporation" 190 "Hella KGaA Hueck & Co." 189 "QUALCOMM" 188 "EMP Corp." 187 "Air-Weigh" 186 "Altronic, Inc." 185 "Beede Electrical Instrument Company" 184 "EIA Electronics" 183 "KDS Controls, Inc." 182 "Vehicle Systems Engineering B.V." 181 "Coretronics, Inc." 180 "Smart Power Systems" 179 "TeeJet Technologies Denmark" 178 "Siemens VDO Automotive AG" 177 "Diagnostic System Associates" 176 "Moritz Aerospace" 175 "Veris Technologies, Inc." 174 "AB Volvo Penta" 173 "Ryeso, Inc." 172 "Yanmar Marine USA" 171 "Wachendorff Elektronik GmbH & Co. KG" 170 "Computronics Corporation Ltd." 169 "Marlin Technologies Inc." 168 "Xantrex" 167 "JLG Industries Inc." 166 "Phoenix International" 165 "CPAC Systems AB" 164 "DaimlerChrysler Off-Highway" 163 "BRP Inc." 162 "Axiomatic Technologies" 161 "Offshore Systems (UK) Limited" 160 "Nido" 159 "NTech Industries Inc." 158 "Firestone Industrial Products Company" 157 "ISSPRO Inc." 156 "ITT Industries - Cannon" 155 "Vetronix Corporation" 154 "Westerbeke Corporation" 153 "Woodward, Industrial Controls Division" 152 "elobau GmbH & Co. KG" 151 "Raven Industries Inc. - Flow Controls Division" 150 "Fleetguard" 149 "Holset" 148 "Blue Water Data, Inc." 147 "Nautibus Electronic GmbH" 146 "Maxima Technologies" 145 "MurCal Controls" 144 "Mercury Marine" 143 "W. Gmeiner GmbH & Co." 142 "TRW Automotive (Commercial Steering Systems)" 141 "Thales Navigation Ltd." 140 "Lowrance Electronics, Inc." 139 "Caterpillar Trimble Control Technologies (CTCT), LLC" 138 "Georg Fritzmeier GmbH & Co. KG" 137 "Maretron" 136 "Komatsu Ltd." 135 "Airmar Technology Corporation" 134 "Iris Technology Ltd." 133 "Bucher Schoerling GmbH" 132 "Mulag-Fahrzeugwerk" 131 "ITT Industries" 130 "Nido - Universal Machines B.V." 129 "OMNEX Control Systems, Inc." 128 "Gerhard Duecker GmbH & Co. KG" 127 "Holland USA" 126 "Driver Tech" 125 "Nevada Automotive Test Center" 124 "Hydac Electronic" 123 "Basler Electric" 122 "FG Wilson (Engineering) Limited" 121 "HED (Hydro Electronic Devices, Inc.)" 120 "RDS Technology Ltd." 119 "IntegriNautics" 118 "Intron GmbH" 117 "HUSCO International" 116 "BEELINE Technologies" 115 "NACCO Materials Handling Group, Inc." 114 "EControls, Inc." 113 "Stress-Tek, Inc." 112 "MECALAC" 111 "Maschinenfabrik Bernard Krone GmbH" 110 "EPIQ Sensor-Nite" 109 "TeeJet Technologies Denmark" 108 "WTK-Elecktronik GmbH" 107 "Grimme Landmaschinen GmbH & Co. KG" 106 "BAE Systems Controls, Inc." 105 "Kiepe Elektrik GmbH & Co. KG" 104 "Claas Selbstfahrende Erntemaschinen GmbH" 103 "CLAAS Agrosystems GmbH & Co. KG" 102 "AGCO GmbH & Co." 101 "Sensoria" 100 "VDO Technik AG" 99 "International Transmissions Ltd (ITL)" 98 "Mueller-Elektronik GmbH & Co." 97 "Ag Leader Technology, Inc." 96 "Mech@tronic IT GmbH" 95 "Pacific Insight Electronics Corp." 94 "CNH Global N.V." 93 "Perkins Engines Company Ltd." 92 "Ag-Chem Equipment Co., Inc." 91 "BSG Bodensee Steuergeraete GmbH" 90 "Knorr-Bremse SfN GmbH" 89 "Kverneland Group, Electronics Division" 88 "Satloc Precision GPS" 87 "J.C. Bamford Excavators Ltd (JCB)" 86 "C.E. Niehoff & Company" 85 "Kohler Co." 84 "New Holland UK Limited" 83 "Bendix VORAD Technologies" 82 "Bobcat/Ingersoll-Rand" 81 "Fire Research Corp" 80 "Twin Disc, Inc." 79 "Daimler Benz AG - Engine Division (PBM)" 78 "Frank W. Murphy Manufacturing, Inc." 77 "Deere Power Systems Group" 76 "unused" 75 "Deere & Co. Agricultural Division" 74 "Eaton Axle-Brake Division" 73 "LeTourneau, Inc." 72 "Sisu Corporation" 71 "Vansco Electronics Ltd." 70 "Flex-Coil Limited" 69 "Trimble Navigation" 68 "Scania" 67 "Funk Manufacturing Company" 66 "John Deere Construction Equipment Division" 65 "MAN Nutzfahrzeuge AG" 64 "unused" 63 "ZF Industries Inc." 62 "Wabco" 61 "Volvo Truck Corp." 60 "Volvo Trucks North America Inc." 59 "VES Inc." 58 "SPX Corporation, OTC Division" 57 "Sauer-Danfoss Co." 56 "SAIC" 55 "Ryder System Inc." 54 "Meritor Wabco" 53 "Continental Automotive Systems US, Inc." 52 "Meritor Automotive, Inc." 51 "Robert Bosch GmbH" 50 "Robert Bosch Corp" 49 "RE America Inc." 48 "Pollak Alphabet" 47 "Phillips Semiconductor" 46 "Noregon Systems, Inc" 45 "PACCAR" 44 "Nippondenso Co. Ltd." 43 "International Truck and Engine Corp. Vehicle Electronics" 42 "International Truck and Engine Corp. Engine Electronics" 41 "Motorola Inc." 40 "Motorola AIEG Inc." 39 "Microfirm Inc." 38 "Micro Processor Systems Inc." 37 "Mack Trucks Inc." 36 "Lucas Ltd." 35 "Kenworth Truck Co." 34 "Kelsey Hayes Co." 33 "John Deere" 32 "Jacobs Vehicle Systems" 31 "J Pollak Corp." 30 "Isuzu Motors Ltd." 29 "Hino Motors Ltd." 28 "Grote Ind. Inc." 27 "GMC" 26 "General Motors Corp., Service Technology Group" 25 "Daimler Trucks North America LLC" 24 "Ford Motor Co., Vehicle Controls" 23 "Ford Motor Co., Heavy Truck" 22 "Ford Motor Co., Electronic Concepts $ Systems" 21 "Echilin Inc., Midland Brake Inc." 20 "Eaton Ltd" 19 "Eaton Corp. Trucking Info Services" 18 "Eaton Corp, Transmission Division" 17 "Eaton Corp. Res & Dev" 16 "Eaton Corp." 15 "Dickey-John Corp." 14 "Detroit Diesel Corporation" 13 "Delco Electronics" 12 "Deere & Company, Precision Farming" 11 "Dearborn Group Inc." 10 "Cummins Engine Co." 9 "Chrysler Corp." 8 "Caterpillar Inc." 7 "Case Corp." 6 "Berifors Electronics AB" 5 "AMP Inc." 4 "Ametek-Dixson" 3 "Ametek, US Gauge Division" 2 "Allison Transmission, GMC" 1 "Allied Signal Inc." 0 "Reserved" 231 "Topcon Positioning Systems, Inc." 230 "Saucon Technologies" 229 "Garmin International Inc." 228 "ZF Marine Electronics" 227 "Lykketronic A/S" 226 "Monaco Coach Corporation" 225 "SKF" 224 "EMMI Network, S.L." 223 "Vaueo Retarder Co., Ltd." 263 "IMMI" 262 "HydraForce, Inc" 261 "Red Dot Corporation" 260 "Reichhardt GmbH" 259 "Jetter AG" 258 "ARAG" 257 "Honda Motor Co., Ltd" 256 "Tyco Electronics AMP" 255 "MEAS France" 254 "GE Sensing" 253 "Mobile Control Systems" 298 "Holley Performance" 297 "Zonar Systems Inc" 296 "micro dynamics GmbH" 295 "BEP Marine" 294 "Grayhill Inc." 293 "Spyder Controls Corp." 292 "IKUSI - Angel Iglesias S.A." 291 "Groeneveld Transport Efficiency BV" 290 "Kuebler GmbH" 289 "Watlow" 288 "Mitsubishi FUSO Truck & Bus Corp." 287 "NTech Industries, Inc" 286 "Coelmo srl" 285 "Sea Recovery Corp" 284 "Mobile Tech Chile" 283 "CWF Hamilton & Co Ltd" 282 "Medallion Instrumentation Systems" 281 "Precision Governors LLC" 311 "Patrick Power Products" 310 "TECNORD srl" 309 "Krauss-Maffei Wegmann GmbH & Co. KG" 308 "Cyntrx" 307 "MBW Technologies" 306 "Sleipner Motor AB" 305 "NovAtel Inc" 304 "EmpirBus AB" 303 "CTS Corporation" 302 "Nissin Kogyo Co., LTD" 301 "Parker Hannifin (UK) Ltd FDE group" 300 "Systron Donner Automotive" 299 "Rauch Landmaschinen GmbH" 280 "Leica Geosystems Pty Ltd" 279 "Geometris LP" 278 "Takata Electronics" 277 "LHP Telematics" 276 "Aqua-Hot Heating Systems" 275 "Navico Egersund AS" 274 "LTW Technology Co., LTD" 273 "Active Research Limited" 272 "Gross Mechanical Laboratories, Inc" 327 "Sonceboz SA" 326 "Akron Brass Company" 325 "ASM Automation Sensorik Messtechnik GmbH" 324 "Snap-on Diagnostics" 323 "Mobileye Vision Technologies Ltd." 322 "MICHENKA s.r.o." 321 "Ultra Electronics, Electrics" 320 "Miedema Landbouwwerktuigenfabriek B.V." 319 "Cadec Global" 318 "SAT Plan" 317 "Navtronics Bvba" 316 "ITT Flow Control" 315 "Icom Incorporated" 314 "CSM GmbH" 313 "Ilmor Engineering, Inc" 312 "Lectronix, Inc." 271 "Cole Hersee" 270 "Tennant" 269 "Saft America Inc.,  Space & Defense Division" 268 "Accurate Technologies" 267 "Red Lion Controls, Inc" 266 "International Thermal Research Ltd" 265 "MTS Sensor Technologie GmbH" 264 "Autolync" 248 "Cooper Standard Automotive Active Systems Group" 247 "ePULSE" 246 "Class 1, Inc" 245 "Capstan Ag Systems, Inc." 244 "Techno-Matic" 243 "eRide, Inc." 242 "Kokusandenki Co. Ltd" 241 "Schneider Automation SAS " 240 "Vanair Mfg" 239 "May & Scofield Ltd" 238 "ZF Friedrichshafen AG" 237 "Agtron Enterprises Inc" 236 "Norac Systems International Inc" 235 "SailorMade Marine Telemetry - Tetra Technology Ltd." 234 "Mondial electronic GmbH" ;
VAL_ 2364473169 VehicleSystem 0 "Non-specific System" 127 "Not Available" ;
VAL_ 2364473169 VehicleSystem5 127 "Not Available" 0 "Ind. Process Control Stationary" ;
VAL_ 2364473169 VehicleSystem4 125 "Entertainment" 120 "Display" 85 "External Environment" 75 "Sensor Communication Interface" 35 "Electrical Generation" 100 "Deck, Cargo and Fishing Equipment" 90 "Internal Environment" 80 "Instrumentation/General Systems (deprecate)" 70 "Communications" 60 "Navigation" 50 "Propulsion" 40 "Steering and Control Surfaces" 30 "Electrical Distribution" 25 "Inter/Intranetwork Device" 20 "Safety Systems" 10 "System Tools" 127 "Not Available" 0 "Non-specific System" ;
VAL_ 2364473169 VehicleSystem3 8 "Grader" 7 "Four Wheel Drive Loader" 6 "Forklift" 5 "Excavator" 4 "Crawler" 3 "Backhoe" 2 "Articulated Dump Truck" 1 "Skid Steer Loader" 127 "Not Available" 0 "Non-specific System" ;
VAL_ 2364473169 VehicleSystem2 25 "Slurry Applicators" 24 "Utility Vehicles" 23 "Mulchers" 22 "Timber Processing Machines" 21 "Timber loaders" 20 "Forwarders" 19 "Timber Harvesters" 17 "Sensor Systems" 16 "Skidder" 15 "Earth Work" 14 "Special Crops" 13 "Powered Auxiliary Device" 12 "Farm Yard Operations" 11 "Transport/Trailer" 10 "Irrigation" 9 "Forage" 8 "Root Harvesters" 7 "Harvesters" 6 "Sprayers" 5 "Fertilizers" 4 "Planters/Seeders" 3 "Secondary Tillage" 2 "Tillage" 1 "Tractor" 127 "Not Available" 0 "Non-specific System" ;
VAL_ 2364473169 VehicleSystem1 2 "Trailer" 1 "Tractor" 127 "Not Available" 0 "Non-specific System" ;
VAL_ 2566838014 HybrdSystmBrkPdlRgnrtvBrkngDsblS 3 "Not Available" 2 "Error" 1 "Brake pedal regenerative braking disable switch is on.  When this switch is on, regenerative braking shall not be activated by brake pedal application." 0 "Brake pedal regenerative braking disable switch is off.  When this switch is off, regenerative braking may be activated by brake pedal application." ;
VAL_ 2566838014 HybrdSystmRgnrtvBrkngDsbleSwitch 3 "Not Available" 2 "Error" 1 "Regenerative Braking  Disable Switch is on.  Regenerative braking is not allowed." 0 "Regenerative Braking Disable Switch is off.  Regenerative braking is allowed." ;
VAL_ 2566838014 HybrdSystmOffBrdChrgrCnnctnSttus 3 "Not available" 2 "Error" 1 "Off-board charger is connected" 0 "Off-board charger is not connected" ;
VAL_ 2566838014 HybrdSystmPwrElctrncsClntLvlSwtc 3 "Not Available" 2 "Error" 1 "Coolant Level is sufficient" 0 "Coolant Level is not sufficient" ;
VAL_ 2566838014 HybrdSystmPrplsnClantLevelSwitch 3 "Not Available" 2 "Error" 1 "Coolant Level is sufficient" 0 "Coolant Level is not sufficient" ;
VAL_ 2566838014 HybrdSystmPrtctionOverrideSwitch 3 "Not Available" 2 "Error" 1 "Active" 0 "Not Active" ;
VAL_ 2566687998 AT1PrtcltSensorRegenerationState 15 "- Not Available" 3 "- Regeneration is active and has been initiated due to time based conditions" 2 "- Regeneration is active and has been initiated because of sensor conditions" 1 "- Regneration is active and has been initiated by request via SPN 6783" 0 "- Regeneration is not active" ;
VAL_ 2566687998 AT1PrtcltSnsorRegenerationStatus 3 "not available" 2 "Regeneration failed" 1 "Regeneration was successful" 0 "Regeneration attempt has not occurred during this operational cycle" ;
VAL_ 2566687998 AT1ParticulateSensorHeaterState 3 "Heater is off" 2 "Heater is in ramp up mode" 1 "Heater is being held at a specified level" 0 "Heater is in closed loop control" ;
VAL_ 2566687742 AT1ParticulateSensorPowerSupply 11 "Unavailable" 10 "Error" 1 "On" 0 "Off" ;
VAL_ 2566687742 AT1PrtclateSensorDetectionStatus 15 "– Not supported" 8 "– Halt particulate matter detection. An irrecoverable fault likely occurred. Will remain in this state until a manual fault clear or a new operational cycle has started." 7 "– Sensor regeneration did not complete due to system parameters out of range (e.g., exhaust temperature out of range). Regeneration will restart once the values of the appropriate system parameters are conducive to regeneration." 6 "– Relearning particulate sensor resistance after particulate sensor regeneration" 5 "– Heater diagnostics test" 4 "– Cooling after particulate sensor regeneration" 3 "– Heater is active for particulate sensor regeneration" 2 "– Particulate matter detection" 1 "– Waiting for dew point (see SPN 6784)" 0 "– Initialization for particulate matter detection" ;
VAL_ 2365348350 EngLoadShareStatus 15 "- Unavailable" 14 "- Error" 4 "- Unloading" 3 "- Loading" 2 "- Slave" 1 "- Master" 0 "- Offline" ;
VAL_ 2365348350 EngUnloadStatus 3 "Not Available" 2 "Error" 1 "Requested" 0 "Not Requested" ;
VAL_ 2633782014 BinWeighingErrorStatus 15 "Not available / not applicable" 3 "Weighing error: empty bin lifted, emptied" 2 "Weighing error: bin lifted, not emptied" 1 "Bad lift cycle" 0 "No error" ;
VAL_ 2365346302 LiftAxle2Status 7 "Not available" 6 "Error" 5 "Loading (load is being transferred to the tag axle)" 4 "Lowering (tag axle is moving down)" 3 "Up (tag axle is up and stationary)" 2 "Lifting (tag axle is moving up)" 1 "Unloading (load is being transferred from the tag axle)" 0 "Down (tag axle is laden)" ;
VAL_ 2365346302 LiftAxle1Status 7 "Not available" 6 "Error" 5 "Loading (load is being transferred to the tag axle)" 4 "Lowering (tag axle is moving down)" 3 "Up (tag axle is up and stationary)" 2 "Lifting (tag axle is moving up)" 1 "Unloading (load is being transferred from the tag axle)" 0 "Down (tag axle is laden)" ;
VAL_ 2566672638 HaulModeStatus 15 "- Not Available" 14 "- Error" 5 "- Unloaded -- Machine is empty" 4 "- Unloading -- Payload is being removed from the machine" 3 "- Loaded -- Loading operation has been completed" 2 "- Approaching Loaded -- Machine is near its maximum capacity" 1 "- Loading -- Payload is being added to the machine" 0 "- Not in Haul Mode" ;
VAL_ 2566672382 PayloadWeightSensor8Status 3 "Not available" 2 "Error (Sensor failed)" 1 "Sensor degraded" 0 "Sensor fully functional" ;
VAL_ 2566672382 PayloadWeightSensor7Status 3 "Not available" 2 "Error (Sensor failed)" 1 "Sensor degraded" 0 "Sensor fully functional" ;
VAL_ 2566672382 PayloadWeightSensor6Status 3 "Not available" 2 "Error (Sensor failed)" 1 "Sensor degraded" 0 "Sensor fully functional" ;
VAL_ 2566672382 PayloadWeightSensor5Status 3 "Not available" 2 "Error (Sensor failed)" 1 "Sensor degraded" 0 "Sensor fully functional" ;
VAL_ 2566672382 PayloadWeightSensor4Status 3 "Not available" 2 "Error (Sensor failed)" 1 "Sensor degraded" 0 "Sensor fully functional" ;
VAL_ 2566672382 PayloadWeightSensor3Status 3 "Not available" 2 "Error (Sensor failed)" 1 "Sensor degraded" 0 "Sensor fully functional" ;
VAL_ 2566672382 PayloadWeightSensor2Status 3 "Not available" 2 "Error (Sensor failed)" 1 "Sensor degraded" 0 "Sensor fully functional" ;
VAL_ 2566672382 PayloadWeightSensor1Status 3 "Not available" 2 "Error (Sensor failed)" 1 "Sensor degraded" 0 "Sensor fully functional" ;
VAL_ 2566671614 SCROprtrInducementOverrideEnable 3 "Not available" 2 "SAE Reserved" 1 "Override allowed" 0 "Override not allowed" ;
VAL_ 2566671102 SCRSystemCleaningForcedStatus 7 "not available" 6 "Reserved for SAE Assignment" 5 "Reserved for SAE Assignment" 4 "Reserved for SAE Assignment" 3 "Reserved for SAE Assignment" 2 "Active – Forced by Service Tool " 1 "Active – Forced by Switch (See SPN 3696)" 0 "Not Active" ;
VAL_ 2566671102 SCRSystmClnngAtmtcIntationConfig 3 "not available" 2 "reserved for SAE assignment" 1 "enabled" 0 "not enabled" ;
VAL_ 2566671102 SCRSystmClnngInhbtdDTVhclSpdBlwA 3 "not available" 2 "reserved for SAE assignment" 1 "inhibited" 0 "not inhibited" ;
VAL_ 2566671102 SCRSystmClnngInhbtdDTEngNtWrmdUp 3 "not available" 2 "reserved for SAE assignment" 1 "inhibited" 0 "not inhibited" ;
VAL_ 2566671102 SCRSystmClnngInhbtdDTPrmnntSystm 3 "not available" 2 "reserved for SAE assignment" 1 "inhibited" 0 "not inhibited" ;
VAL_ 2566671102 SCRSystmClnngInhbtdDTTmprrySystm 3 "not available" 2 "reserved for SAE assignment" 1 "inhibited" 0 "not inhibited" ;
VAL_ 2566671102 SCRSystmClnngInhbtdDTSystmTmeout 3 "not available" 2 "reserved for SAE assignment" 1 "inhibited" 0 "not inhibited" ;
VAL_ 2566671102 SCRSystmClnngInhbtdDTSystmFltAct 3 "not available" 2 "reserved for SAE assignment" 1 "inhibited" 0 "not inhibited" ;
VAL_ 2566671102 SCRSystmClnngInhbtdDTLwExhstTemp 3 "not available" 2 "reserved for SAE assignment" 1 "inhibited" 0 "not inhibited" ;
VAL_ 2566671102 SCRSystmClnngInhbtdDTPrkngBrkNtS 3 "not available" 2 "reserved for SAE assignment" 1 "inhibited" 0 "not inhibited" ;
VAL_ 2566671102 SCRSystmClnngInhbtdDTVhclSpdAbvA 3 "not available" 2 "reserved for SAE assignment" 1 "inhibited" 0 "not inhibited" ;
VAL_ 2566671102 SCRSystmClnngInhbtdDTOtOfNeutral 3 "not available" 2 "reserved for SAE assignment" 1 "inhibited" 0 "not inhibited" ;
VAL_ 2566671102 SCRSystmClnngInhbtdDTAcclPdlOffI 3 "not available" 2 "reserved for SAE assignment" 1 "inhibited" 0 "not inhibited" ;
VAL_ 2566671102 SCRSystmClnngInhbtdDeToPTOActive 3 "not available" 2 "reserved for SAE assignment" 1 "inhibited" 0 "not inhibited" ;
VAL_ 2566671102 SCRSystmClnngInhbtdDTSrvcBrkActv 3 "not available" 2 "reserved for SAE assignment" 1 "inhibited" 0 "not inhibited" ;
VAL_ 2566671102 SCRSystmClnngInhbtdDTCltchDsnggd 3 "not available" 2 "reserved for SAE assignment" 1 "inhibited" 0 "not inhibited" ;
VAL_ 2566671102 SCRSystmClnngInhbtdDTInhbtSwitch 3 "not available" 2 "reserved for SAE assignment" 1 "inhibited" 0 "not inhibited" ;
VAL_ 2566671102 SCRSystemCleaningInhibitedStatus 3 "not available" 2 "reserved for SAE assignment" 1 "inhibited" 0 "not inhibited" ;
VAL_ 2566671102 SCRSystemCleaningStatus 3 "not available" 2 "SCR system cleaning is needed - automatically initiated SCR system cleaning imminent" 1 "active" 0 "not active" ;
VAL_ 2566671102 SCRSystemCleaningLampCmd 7 "not available" 6 "reserved for SAE assignment" 5 "reserved for SAE assignment" 4 "On – fast blink (1 HZ)" 3 "reserved for SAE assignment" 2 "reserved for SAE assignment " 1 "On – solid" 0 "Off" ;
VAL_ 2566668030 HtExchngerDebrisPurgeApproaching 3 "Not available" 2 "SAE reserved" 1 "Approaching" 0 "Not approaching" ;
VAL_ 2566668030 HeatExchangerDebrisPurgeStatus 3 "Not available" 2 "SAE reserved" 1 "Active" 0 "Inactive" ;
VAL_ 2499556094 AT1PrtcltSnsrHtrPwrSpplyDgnstcSt 7 "– Not Available. Aftertreatment 1 Particulate Sensor Heater Power Supply Preliminary FMI (SPN 7329) is not valid." 3 "– Enable or pause conditions have allowed tests to execute this power cycle. If tests are executed while this parameter is 011, then this parameter shall change to 010. To assure that recipients of this parameter detect this state change, this parameter s" 2 "– Enable or pause conditions have allowed tests to execute this power cycle. If tests are executed while this parameter is 010, then this parameter shall change to 011. To assure that recipients of this parameter detect this state change, this parameter s" 1 "- Tests supported but not completed this power cycle. Enable or pause conditions have not been satisfied, which has prevented tests from executing. When tests have completed, this parameter shall change to 010. Aftertreatment 1 Particulate Sensor Heater P" 0 "- Tests monitored continuously. There are no enable or pause conditions. See Aftertreatment 1 Particulate Sensor Heater Power Supply Preliminary FMI (SPN 7329) for result. " ;
VAL_ 2499556094 AT1PrtcltSnsrPwrSpplyDgnstcSttus 1 "- Tests supported but not completed this power cycle. Enable or pause conditions have not been satisfied, which has prevented tests from executing. When tests have completed, this parameter shall change to 010. Aftertreatment 1 Particulate Sensor Power Su" 0 "- Tests monitored continuously. There are no enable or pause conditions. See Aftertreatment 1 Particulate Sensor Power Supply Preliminary FMI (SPN 7327) for result." 7 "– Not Available. Aftertreatment 1 Particulate Sensor Power Supply Preliminary FMI (SPN 7327) is not valid." 3 "– Enable or pause conditions have allowed tests to execute this power cycle. If tests are executed while this parameter is 011, then this parameter shall change to 010. To assure that recipients of this parameter detect this state change, this parameter s" 2 "– Enable or pause conditions have allowed tests to execute this power cycle. If tests are executed while this parameter is 010, then this parameter shall change to 011. To assure that recipients of this parameter detect this state change, this parameter s" ;
VAL_ 2499556094 AT1PrtcltSnsrInptDagnosticStatus 7 "– Not Available. Aftertreatment 1 Particulate Sensor Input Preliminary FMI (SPN 7325) is not valid." 3 "– Enable or pause conditions have allowed tests to execute this power cycle. If tests are executed while this parameter is 011, then this parameter shall change to 010. To assure that recipients of this parameter detect this state change, this parameter s" 2 "– Enable or pause conditions have allowed tests to execute this power cycle. If tests are executed while this parameter is 010, then this parameter shall change to 011. To assure that recipients of this parameter detect this state change, this parameter s" 1 "- Tests supported but not completed this power cycle. Enable or pause conditions have not been satisfied, which has prevented tests from executing. When tests have completed, this parameter shall change to 010. Aftertreatment 1 Particulate Sensor Input Pr" 0 "- Tests monitored continuously. There are no enable or pause conditions. See Aftertreatment 1 Particulate Sensor Input Preliminary FMI (SPN 7325) for result." ;
VAL_ 2499556094 AT1PrtcltSnsrHtrLwSdDrvrDgnstcSt 7 "– Not Available. Aftertreatment 1 Particulate Sensor Heater Low Side Driver Preliminary FMI (SPN 7323) is not valid." 3 "– Enable or pause conditions have allowed tests to execute this power cycle. If tests are executed while this parameter is 011, then this parameter shall change to 010. To assure that recipients of this parameter detect this state change, this parameter s" 2 "– Enable or pause conditions have allowed tests to execute this power cycle. If tests are executed while this parameter is 010, then this parameter shall change to 011. To assure that recipients of this parameter detect this state change, this parameter s" 1 "- Tests supported but not completed this power cycle. Enable or pause conditions have not been satisfied, which has prevented tests from executing. When tests have completed, this parameter shall change to 010. Aftertreatment 1 Particulate Sensor Heater L" 0 "- Tests monitored continuously. There are no enable or pause conditions. See Aftertreatment 1 Particulate Sensor Heater Low Side Driver Preliminary FMI (SPN 7323) for result." ;
VAL_ 2499556094 AT1PrtcltSnsrHtrHghSdDrvrDgnstcS 7 "– Not Available. Aftertreatment 1 Particulate Sensor Heater High Side Driver Preliminary FMI (SPN 7321) is not valid." 3 "– Enable or pause conditions have allowed tests to execute this power cycle. If tests are executed while this parameter is 011, then this parameter shall change to 010. To assure that recipients of this parameter detect this state change, this parameter s" 2 "– Enable or pause conditions have allowed tests to execute this power cycle. If tests are executed while this parameter is 010, then this parameter shall change to 011. To assure that recipients of this parameter detect this state change, this parameter s" 1 "- Tests supported but not completed this power cycle. Enable or pause conditions have not been satisfied, which has prevented tests from executing. When tests have completed, this parameter shall change to 010. Aftertreatment 1 Particulate Sensor Heater H" 0 "- Tests monitored continuously. There are no enable or pause conditions. See Aftertreatment 1 Particulate Sensor Heater High Side Driver Preliminary FMI (SPN 7321) for result." ;
VAL_ 2566664702 ATEngLoadRq 3 "Not Available" 2 "Urgent Aftertreatment Engine Load Desired" 1 "Aftertreatment Engine Load Desired" 0 "No Request" ;
VAL_ 2566664702 ATEngSpeedCtrlRq 3 "Not Available" 2 "Urgent Aftertreatment Engine Speed Control Desired" 1 "Aftertreatment Engine Speed Control Desired" 0 "No Request" ;
VAL_ 2566664702 ATActvRgnrtnInhbtdDTLwExhstPress 3 "Not Available" 2 "Reserved for SAE assignment" 1 "Inhibited" 0 "Not Inhibited" ;
VAL_ 2566664702 ATThermalManagementStatus 3 "Not available" 2 "Reserved for SAE assignment" 1 "Active" 0 "Not active" ;
VAL_ 2633773310 SCROprtrIndcmntOvrrdRnwlRequired 3 "Not Available" 2 "Error" 1 "Required" 0 "Not Required" ;
VAL_ 2633773310 SCROpratorInducementOverrideMode 7 "Not Available" 4 "Expired" 3 "Active Extended" 2 "Active" 1 "Available - Not Active" 0 "Not Available" ;
VAL_ 2566663934 EngThrttlVlv1MotorCurrentDisable 3 "Don't Care/Take No Action" 2 "Reserved" 1 "Disable" 0 "Do Not Disable" ;
VAL_ 2566663934 EngCylHdBypssActtr1MtrCrrntDsble 3 "Don't Care/Take No Action" 2 "Reserved" 1 "Disable" 0 "Do Not Disable" ;
VAL_ 2566663934 EngTrbWstgtActtr1MtrCrrntDisable 3 "Don't Care/Take No Action" 2 "Reserved" 1 "Disable" 0 "Do Not Disable" ;
VAL_ 2566663934 EngTrbCmprssrBlwffActtr1MtrCrrnt 3 "Don't Care/Take No Action" 2 "Reserved" 1 "Disable" 0 "Do Not Disable" ;
VAL_ 2566663422 TrlrBrkClprLnngClranceAxle5Right 3 "Not available / not applicable" 2 "Error" 1 "Caliper lining clearance is low" 0 "Caliper lining clearance is adequate" ;
VAL_ 2566663422 TrlrBrkClprLnngClaranceAxle5Left 3 "Not available / not applicable" 2 "Error" 1 "Caliper lining clearance is low" 0 "Caliper lining clearance is adequate" ;
VAL_ 2566663422 TrlrBrkClprLnngClranceAxle4Right 3 "Not available / not applicable" 2 "Error" 1 "Caliper lining clearance is low" 0 "Caliper lining clearance is adequate" ;
VAL_ 2566663422 TrlrBrkClprLnngClaranceAxle4Left 3 "Not available / not applicable" 2 "Error" 1 "Caliper lining clearance is low" 0 "Caliper lining clearance is adequate" ;
VAL_ 2566663422 TrlrBrkClprLnngClranceAxle3Right 3 "Not available / not applicable" 2 "Error" 1 "Caliper lining clearance is low" 0 "Caliper lining clearance is adequate" ;
VAL_ 2566663422 TrlrBrkClprLnngClaranceAxle3Left 3 "Not available / not applicable" 2 "Error" 1 "Caliper lining clearance is low" 0 "Caliper lining clearance is adequate" ;
VAL_ 2566663422 TrlrBrkClprLnngClranceAxle2Right 3 "Not available / not applicable" 2 "Error" 1 "Caliper lining clearance is low" 0 "Caliper lining clearance is adequate" ;
VAL_ 2566663422 TrlrBrkClprLnngClaranceAxle2Left 3 "Not available / not applicable" 2 "Error" 1 "Caliper lining clearance is low" 0 "Caliper lining clearance is adequate" ;
VAL_ 2566663422 TrlrBrkClprLnngClranceAxle1Right 3 "Not available / not applicable" 2 "Error" 1 "Caliper lining clearance is low" 0 "Caliper lining clearance is adequate" ;
VAL_ 2566663422 TrlrBrkClprLnngClaranceAxle1Left 3 "Not available / not applicable" 2 "Error" 1 "Caliper lining clearance is low" 0 "Caliper lining clearance is adequate" ;
VAL_ 2566663422 TrctrBrkClprLnngClrnceAxle5Right 3 "Not available / not applicable" 2 "Error" 1 "Caliper lining clearance is low" 0 "Caliper lining clearance is adequate" ;
VAL_ 2566663422 TrctrBrkClprLnngClranceAxle5Left 3 "Not available / not applicable" 2 "Error" 1 "Caliper lining clearance is low" 0 "Caliper lining clearance is adequate" ;
VAL_ 2566663422 TrctrBrkClprLnngClrnceAxle4Right 3 "Not available / not applicable" 2 "Error" 1 "Caliper lining clearance is low" 0 "Caliper lining clearance is adequate" ;
VAL_ 2566663422 TrctrBrkClprLnngClranceAxle4Left 3 "Not available / not applicable" 2 "Error" 1 "Caliper lining clearance is low" 0 "Caliper lining clearance is adequate" ;
VAL_ 2566663422 TrctrBrkClprLnngClrnceAxle3Right 3 "Not available / not applicable" 2 "Error" 1 "Caliper lining clearance is low" 0 "Caliper lining clearance is adequate" ;
VAL_ 2566663422 TrctrBrkClprLnngClranceAxle3Left 3 "Not available / not applicable" 2 "Error" 1 "Caliper lining clearance is low" 0 "Caliper lining clearance is adequate" ;
VAL_ 2566663422 TrctrBrkClprLnngClrnceAxle2Right 3 "Not available / not applicable" 2 "Error" 1 "Caliper lining clearance is low" 0 "Caliper lining clearance is adequate" ;
VAL_ 2566663422 TrctrBrkClprLnngClranceAxle2Left 3 "Not available / not applicable" 2 "Error" 1 "Caliper lining clearance is low" 0 "Caliper lining clearance is adequate" ;
VAL_ 2566663422 TrctrBrkClprLnngClrnceAxle1Right 3 "Not available / not applicable" 2 "Error" 1 "Caliper lining clearance is low" 0 "Caliper lining clearance is adequate" ;
VAL_ 2566663422 TrctrBrkClprLnngClranceAxle1Left 3 "Not available / not applicable" 2 "Error" 1 "Caliper lining clearance is low" 0 "Caliper lining clearance is adequate" ;
VAL_ 2566662654 LaneMarkQualityOnTheRightSide 7 "= not available or not installed" 6 "= error" 3 "= perfect recognition of lane marks" 2 "= good reliablity of detected lane marks" 1 "= low reliablity of detected lane marks" 0 "= no lane marks detected" ;
VAL_ 2566662654 LaneMarkQualityOnTheLeftSide 7 "= not available or not installed" 6 "= error" 3 "= perfect recognition of lane marks" 2 "= good reliablity of detected lane marks" 1 "= low reliablity of detected lane marks" 0 "= no lane marks detected" ;
VAL_ 2566662654 LaneDepartureAngleRight 255 "not available or not installed" 254 "error" 253 "reserved / not used" 252 "not reliable" 251 "not in range" ;
VAL_ 2566662654 LaneDepartureAngleLeft 255 "not available or not installed" 254 "error" 253 "reserved / not used" 252 "not reliable" 251 "not in range" ;
VAL_ 2566662654 RghtDstncTLnMrkFrmVehiclesMiddle 255 "not available or not installed" 254 "error" 253 "reserved / not used" 252 "not reliable" 251 "not in range" ;
VAL_ 2566662654 LftDstncTLnMrkFromVehiclesMiddle 255 "not available or not installed" 254 "error" 253 "reserved / not used" 252 "not reliable" 251 "not in range" ;
